VERSION ""

NS_ :

BS_:

BU_: SGW PBWM IDCM EVCU2 ECM DMPI BPCM AGSM

BO_ 276 HYBRID_POWERTRAIN1: 64 EVCU2
 SG_ MessageCounter_HYBRID_POWERTRAI : 435|4@0+ (1,0) [0|15] "-"  ECM
 SG_ TransInpSpdPrfl : 68|13@0+ (1,0) [0|8191] "rpm"  ECM
 SG_ InputSpdRaw : 179|12@0+ (1,-2048) [-2048|2046] "rpm"  ECM
 SG_ HybTransSt : 255|8@0+ (1,0) [0|0] "-"  ECM
 SG_ Hybrid_Remedial_Stop : 290|1@0+ (1,0) [0|0] "-"  ECM
 SG_ HybFeedback_Engine : 294|1@0+ (1,0) [0|0] "-"  ECM
 SG_ HybEstEngTorqV : 280|1@0+ (1,0) [0|0] "-"  ECM
 SG_ HybEstEngTorq : 163|12@0+ (0.32,-300.16) [-300.16|1008] "Nm"  ECM
 SG_ HybCrnkAbrted : 282|1@0+ (1,0) [0|0] "-"  ECM
 SG_ HybCmndEngTorqRespTyp : 277|2@0+ (1,0) [0|0] "-"  ECM
 SG_ HybCmndEngTorqPrdtd : 147|12@0+ (0.32,-300.16) [-300.16|1008] "Nm"  ECM
 SG_ HybCmndEngTorqImmed : 131|12@0+ (0.32,-300.16) [-300.16|1008] "Nm"  ECM
 SG_ EngTrqReserveCmd : 263|8@0+ (0.32,0) [0|81.28] "Nm"  ECM
 SG_ EngCntrlMode : 283|1@0+ (1,0) [0|0] "-"  ECM
 SG_ ECMPrepIdleRes : 295|1@0+ (1,0) [0|0] "-"  ECM
 SG_ CRC_HYBRID_POWERTRAIN1 : 447|8@0+ (1,0) [0|255] "-"  ECM
 SG_ PropulsionSystemActive : 408|1@0+ (1,0) [0|1] "-"  ECM
 SG_ HybFstTrqRq_Trans : 293|1@0+ (1,0) [0|0] "-"  ECM

BO_ 271 ENGINE_HYBD_FD_1: 64 ECM
 SG_ TLC_LRN_Rq : 322|1@0+ (1,0) [0|0] "-"  EVCU2
 SG_ Sum_FW_ID_Slw : 327|5@0+ (1,0) [0|30] "-"  EVCU2
 SG_ Sum_FW_ID_Fst : 367|5@0+ (1,0) [0|30] "-"  EVCU2
 SG_ PT_CrnkAct : 310|1@0+ (1,0) [0|0] "-"  EVCU2
 SG_ MinPrdtdEngRunTorqCapV : 213|1@0+ (1,0) [0|0] "-"  EVCU2
 SG_ MinPrdtdEngRunTorqCap : 243|12@0+ (0.32,-300.16) [-300.16|1008] "Nm"  EVCU2
 SG_ MinImmedEngTorqCapV : 215|1@0+ (1,0) [0|0] "-"  EVCU2
 SG_ MinImmedEngTorqCap : 227|12@0+ (0.32,-300.16) [-300.16|1008] "Nm"  EVCU2
 SG_ MinEngTorqCapV : 196|1@0+ (1,0) [0|0] "-"  EVCU2
 SG_ MinEngTorqCap : 211|12@0+ (0.32,-300.16) [-300.16|1008] "Nm"  EVCU2
 SG_ MinAirFlowMinSparkTorqCapV : 197|1@0+ (1,0) [0|0] "-"  EVCU2
 SG_ MinAirFlowMinSparkTorqCap : 195|12@0+ (0.32,-300.16) [-300.16|1008] "Nm"  EVCU2
 SG_ MessageCounter_ENGINE_HYBD_FD_1 : 435|4@0+ (1,0) [0|15] "-"  EVCU2
 SG_ MaxPrdtdEngTorqCapV : 198|1@0+ (1,0) [0|0] "-"  EVCU2
 SG_ MaxPrdtdEngTorqCap : 179|12@0+ (0.32,-300.16) [-300.16|1008] "Nm"  EVCU2
 SG_ MaxOffEngTorqCap : 163|12@0+ (0.32,-300.16) [-300.16|1008] "Nm"  EVCU2
 SG_ HybActEngTorqRespTyp : 149|2@0+ (1,0) [0|0] "-"  EVCU2
 SG_ Feedback_HCP : 293|1@0+ (1,0) [0|0] "-"  EVCU2
 SG_ ETRQ_Mode : 362|3@0+ (1,0) [0|5] "-"  EVCU2
 SG_ EngTrqReserveReq : 351|8@0+ (0.32,0) [0|81.28] "Nm"  EVCU2
 SG_ EngRunCrnkAct : 295|1@0+ (1,0) [0|0] "-"  EVCU2
 SG_ EngOffRecom : 276|1@0+ (1,0) [0|0] "-"  EVCU2
 SG_ Engine_Sync_720 : 277|1@0+ (1,0) [0|0] "-"  Vector__XXX
 SG_ EngDFCO_St : 278|1@0+ (1,0) [0|0] "-"  EVCU2
 SG_ EngDFCO_Req : 279|1@0+ (1,0) [0|0] "-"  EVCU2
 SG_ EngDFCO_Allw : 260|1@0+ (1,0) [0|0] "-"  EVCU2
 SG_ EngCmbstnCmnd : 199|1@0+ (1,0) [0|0] "-"  EVCU2
 SG_ EngAirFlwStdyStTorqV : 262|1@0+ (1,0) [0|0] "-"  EVCU2
 SG_ EngAirFlwStdyStTorq : 275|12@0+ (0.32,-300.16) [-300.16|1008] "Nm"  EVCU2
 SG_ EngActuatorsStat : 133|2@0+ (1,0) [0|0] "-"  EVCU2
 SG_ EngActStdyStTorqV : 263|1@0+ (1,0) [0|0] "-"  EVCU2
 SG_ EngActStdyStTorq : 259|12@0+ (0.32,-300.16) [-300.16|1008] "Nm"  EVCU2
 SG_ CylOff : 245|1@0+ (1,0) [0|0] "-"  EVCU2
 SG_ CRC_ENGINE_HYBD_FD_1 : 447|8@0+ (1,0) [0|255] "-"  EVCU2
 SG_ Crank_Maturing_Fault : 246|1@0+ (1,0) [0|0] "-"  EVCU2
 SG_ Crank_Locked : 247|1@0+ (1,0) [0|0] "-"  Vector__XXX
 SG_ Cam_Int_1_Locked : 229|1@0+ (1,0) [0|0] "-"  Vector__XXX
 SG_ Cam_Exh_1_Locked : 231|1@0+ (1,0) [0|0] "-"  Vector__XXX
 SG_ AccPosV : 214|1@0+ (1,0) [0|1] "" EVCU2
 SG_ AccPos : 343|8@0+ (0.392157,0) [0|100] "%"  EVCU2
 SG_ ECMReq_Remedial_Stop : 135|2@0+ (1,0) [0|0] "-"  EVCU2
 SG_ ECM_Crank_Phase : 372|3@0+ (1,0) [0|7] "-"  Vector__XXX
 SG_ MAP_4_BAR_PHEV : 392|9@0+ (0.8,0) [0|408] "kPa"  EVCU2
 SG_ RedSpkAuthorityAvbl : 308|1@0+ (1,0) [0|1] "" EVCU2
 SG_ EngMinSparkNomCurrAirTorqCap : 82|11@0+ (1,-500) [-500|1547] "Nm"  EVCU2
 SG_ PnLimitMaxEngTrqCapV : 182|1@0+ (1,0) [0|1] "" EVCU2
 SG_ PnLimitMaxEngTrqCap : 321|10@0+ (1,0) [0|1023] "Nm"  EVCU2
 SG_ PnLimitActvFlg : 83|1@0+ (1,0) [0|1] "" EVCU2
 SG_ EngSysFld : 294|1@0+ (1,0) [0|0] "" EVCU2

BO_ 258 BRAKE_FD_2: 64 EVCU2
 SG_ VehicleSpeedVSOSig : 4|13@0+ (0.0625,0) [0|511.875] "Km/h"  IDCM,BPCM

BO_ 476 AGSM_FD_2: 32 AGSM
 SG_ MessageCounter_AGSM2 : 179|4@0+ (1,0) [0|15] "-"  PBWM,EVCU2
 SG_ CRC_AGSM2 : 191|8@0+ (1,0) [0|255] "-"  PBWM,EVCU2
 SG_ ShiftLeverPositionReq : 95|4@0+ (1,0) [0|15] "-"  PBWM,EVCU2

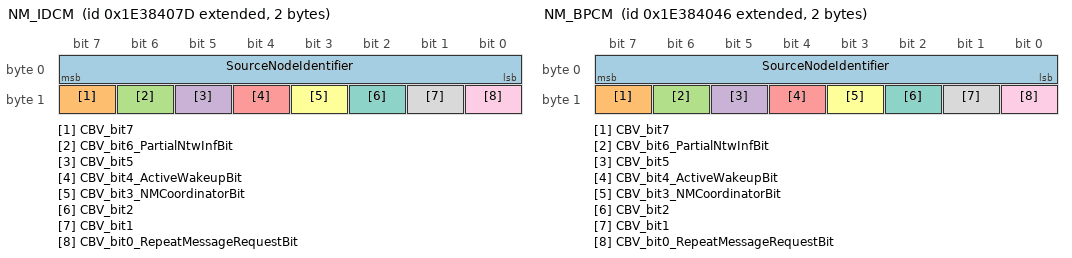
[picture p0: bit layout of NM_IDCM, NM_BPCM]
BO_ 2654486653 NM_IDCM: 2 IDCM
 SG_ SourceNodeIdentifier : 7|8@0+ (1,0) [0|255] "-"  DMPI,PBWM,EVCU2,SGW,BPCM,ECM
 SG_ CBV_bit7 : 15|1@0+ (1,0) [0|1] "" DMPI,PBWM,EVCU2,SGW,BPCM,ECM
 SG_ CBV_bit6_PartialNtwInfBit : 14|1@0+ (1,0) [0|1] "" DMPI,PBWM,EVCU2,SGW,BPCM,ECM
 SG_ CBV_bit5 : 13|1@0+ (1,0) [0|1] "" DMPI,PBWM,EVCU2,SGW,BPCM,ECM
 SG_ CBV_bit4_ActiveWakeupBit : 12|1@0+ (1,0) [0|1] "" DMPI,PBWM,EVCU2,SGW,BPCM,ECM
 SG_ CBV_bit3_NMCoordinatorBit : 11|1@0+ (1,0) [0|1] "" DMPI,PBWM,EVCU2,SGW,BPCM,ECM
 SG_ CBV_bit2 : 10|1@0+ (1,0) [0|1] "" DMPI,PBWM,EVCU2,SGW,BPCM,ECM
 SG_ CBV_bit1 : 9|1@0+ (1,0) [0|1] "" DMPI,PBWM,EVCU2,SGW,BPCM,ECM
 SG_ CBV_bit0_RepeatMessageRequestBit : 8|1@0+ (1,0) [0|1] "" DMPI,PBWM,EVCU2,SGW,BPCM,ECM

BO_ 2654486598 NM_BPCM: 2 BPCM
 SG_ SourceNodeIdentifier : 7|8@0+ (1,0) [0|255] "-"  DMPI,PBWM,EVCU2,IDCM,SGW,ECM
 SG_ CBV_bit7 : 15|1@0+ (1,0) [0|1] "" DMPI,PBWM,EVCU2,IDCM,SGW,ECM
 SG_ CBV_bit6_PartialNtwInfBit : 14|1@0+ (1,0) [0|1] "" DMPI,PBWM,EVCU2,IDCM,SGW,ECM
 SG_ CBV_bit5 : 13|1@0+ (1,0) [0|1] "" DMPI,PBWM,EVCU2,IDCM,SGW,ECM
 SG_ CBV_bit4_ActiveWakeupBit : 12|1@0+ (1,0) [0|1] "" DMPI,PBWM,EVCU2,IDCM,SGW,ECM
 SG_ CBV_bit3_NMCoordinatorBit : 11|1@0+ (1,0) [0|1] "" DMPI,PBWM,EVCU2,IDCM,SGW,ECM
 SG_ CBV_bit2 : 10|1@0+ (1,0) [0|1] "" DMPI,PBWM,EVCU2,IDCM,SGW,ECM
 SG_ CBV_bit1 : 9|1@0+ (1,0) [0|1] "" DMPI,PBWM,EVCU2,IDCM,SGW,ECM
 SG_ CBV_bit0_RepeatMessageRequestBit : 8|1@0+ (1,0) [0|1] "" DMPI,PBWM,EVCU2,IDCM,SGW,ECM

BO_ 1579 HYBRID_CHARGING_STATUS: 32 EVCU2
 SG_ HVBatteryVoltage_MinCal : 32|9@0+ (1,0) [0|510] "V"  IDCM,BPCM
 SG_ HVBatteryVoltage_MaxCal : 16|9@0+ (1,0) [0|510] "V"  IDCM,BPCM
 SG_ HVBatteryCurrent_MaxCal : 63|8@0+ (0.25,-32) [-32|31.5] "Amp"  IDCM,BPCM
 SG_ ChargeSystemFaultReason : 55|8@0+ (1,0) [0|254] "-"  IDCM
 SG_ ACCurrent_MaxCal : 0|9@0+ (0.25,-31.5) [-31.5|50] "Amp"  IDCM,BPCM
 SG_ MessageCounter_HYBRID_CHARGING_ : 179|4@0+ (1,0) [0|15] "-"  IDCM
 SG_ ChargingLevel : 4|4@0+ (1,0) [0|14] "-"  IDCM,SGW,BPCM
 SG_ OBCM_PLUG_STS : 23|2@0+ (1,0) [0|3] "" IDCM
 SG_ VDCM_UDCChrgr : 71|16@0+ (0.1,0) [0|6553.5] "V"  IDCM
 SG_ VDCM_IDCChrgr : 87|16@0+ (0.1,0) [0|6553.5] "A"  IDCM
 SG_ ChargeSystemSts : 7|3@0+ (1,0) [0|6] "-"  IDCM,BPCM
 SG_ ChargeSystemFault : 17|1@0+ (1,0) [0|1] "-"  IDCM
 SG_ CRC_HYBRID_CHARGING_STATUS : 191|8@0+ (1,0) [0|255] "-"  IDCM

BO_ 478 HYBRID_CHARGING_COMMAND: 32 EVCU2
 SG_ MessageCounter_HYBRID_CHARGING_ : 179|4@0+ (1,0) [0|15] "-"  IDCM
 SG_ CRC_HYBRID_CHARGING_COMMAND : 191|8@0+ (1,0) [0|255] "-"  IDCM
 SG_ VoltageRequest : 4|13@0+ (0.1,0) [0|819.1] "Volts"  IDCM
 SG_ OBC_ControlMethod : 38|2@0+ (1,0) [0|2] "-"  IDCM
 SG_ J1772_CloseS2 : 51|1@0+ (1,0) [0|1] "-"  IDCM
 SG_ HVPowertrain_InterlockSts : 34|2@0+ (1,0) [0|3] "-"  BPCM
 SG_ ClearLegislatedDiagInfo : 52|1@0+ (1,0) [0|1] "-"  BPCM
 SG_ OBC_OperativeModeReq : 87|4@0+ (1,0) [0|14] "-"  IDCM
 SG_ HV_Volt_Min_Thrsh : 138|11@0+ (1,0) [0|2047] "V"  IDCM
 SG_ HV_Volt_Max_Thrsh : 133|11@0+ (1,0) [0|2047] "V"  IDCM
 SG_ DC_Curr_Max_Thrsh : 127|10@0+ (1,-511) [-511|512] "A"  IDCM
 SG_ ChargeEnable : 171|2@0+ (1,0) [0|2] "-"  IDCM
 SG_ AC_Curr_Min_Thrsh : 165|10@0+ (1,-511) [-511|512] "A"  IDCM
 SG_ AC_Curr_Max_Thrsh : 159|10@0+ (1,-511) [-511|512] "A"  IDCM
 SG_ CurrentRequest : 81|10@0+ (0.1,-32) [-32|70.3] "A"  IDCM
 SG_ VDCM_StsWldgReq : 83|1@0+ (1,0) [0|1] "-"  IDCM
 SG_ VDCM_SessnStopReq : 82|1@0+ (1,0) [0|1] "-"  IDCM
 SG_ VDCM_StsSWWldgReq : 55|2@0+ (1,0) [0|3] "-"  Vector__XXX

BO_ 1578 HV_CHARGER2: 32 IDCM
 SG_ OBC_IdleTimeSec : 71|16@0+ (3,0) [0|196602] "sec"  EVCU2
 SG_ OBC_IdleTimeMin : 87|16@0+ (1,0) [0|65534] "min"  EVCU2
 SG_ OBC_ChargeTimeSec : 39|16@0+ (3,0) [0|196602] "sec"  EVCU2
 SG_ OBC_ChargeTimeMin : 55|16@0+ (1,0) [0|65534] "min"  EVCU2
 SG_ Charging_WHr : 23|16@0+ (1,0) [0|65534] "WHr"  EVCU2
 SG_ OnboardChargerReady : 116|2@0+ (1,0) [0|2] "-"  EVCU2
 SG_ OnboardChargerMode : 114|4@0+ (1,0) [0|15] "-"  EVCU2
 SG_ OBC_WakeReason : 107|4@0+ (1,0) [0|7] "-"  EVCU2
 SG_ OBC_GenericFailSts : 125|1@0+ (1,0) [0|1] "-"  EVCU2
 SG_ OBC_FaultReason : 102|7@0+ (1,0) [0|126] "-"  EVCU2
 SG_ OBC_EVServiceLampOn : 124|1@0+ (1,0) [0|1] "-"  EVCU2
 SG_ OBC_EVServiceLampFlash : 123|1@0+ (1,0) [0|1] "-"  EVCU2
 SG_ OBC_CurrentFailureSts : 121|1@0+ (1,0) [0|1] "-"  EVCU2
 SG_ OBC_ChargingFaultSts : 110|3@0+ (1,0) [0|7] "-"  EVCU2
 SG_ OBC_ChargeFailure : 120|1@0+ (1,0) [0|1] "-"  EVCU2
 SG_ OBC_CaptureEnvironmentData : 119|1@0+ (1,0) [0|1] "-"  EVCU2
 SG_ ACplug_PwrMax : 7|16@0+ (1,-32767) [-32767|32767] "W"  EVCU2
 SG_ OBC_Prox : 159|8@0+ (0.05,0) [0|12.75] "V"  EVCU2
 SG_ OBC_Pilot : 151|8@0+ (0.05,0) [0|12.75] "V"  EVCU2
 SG_ OBCM_PrechargeSts : 167|2@0+ (1,0) [0|3] "-"  EVCU2
 SG_ ChrgFailSts : 165|3@0+ (1,0) [0|7] "" EVCU2

BO_ 1372 DUALCHARGER_THERMAL: 32 IDCM
 SG_ OBC_Temp4 : 63|8@0+ (1,-40) [-40|214] "°C"  EVCU2
 SG_ OBC_Temp3 : 55|8@0+ (1,-40) [-40|214] "°C"  EVCU2
 SG_ OBC_Temp2 : 47|8@0+ (1,-40) [-40|214] "°C"  EVCU2
 SG_ OBC_Temp1 : 39|8@0+ (1,-40) [-40|214] "°C"  EVCU2

BO_ 2564682064 DIAGNOSTIC_ROE_IDCM: 8 IDCM
 SG_ N_PDU : 7|64@0+ (1,0) [0|0] "" SGW

BO_ 2564682320 DIAGNOSTIC_ROE_FD_IDCM: 64 IDCM
 SG_ N_PDU : 7|64@0+ (1,0) [0|0] "" SGW

BO_ 2564682308 DIAGNOSTIC_ROE_FD_BPCM: 64 BPCM
 SG_ N_PDU : 7|64@0+ (1,0) [0|0] "" SGW

BO_ 2564682052 DIAGNOSTIC_ROE_BPCM: 8 BPCM
 SG_ N_PDU : 7|64@0+ (1,0) [0|0] "" SGW

BO_ 2564485712 DIAGNOSTIC_RESPONSE_FD_IDCM: 64 IDCM
 SG_ N_PDU : 7|64@0+ (1,0) [0|0] "" SGW

BO_ 2564485700 DIAGNOSTIC_RESPONSE_FD_BPCM: 64 BPCM
 SG_ N_PDU : 7|64@0+ (1,0) [0|0] "" SGW

BO_ 2564444402 DIAGNOSTIC_REQUEST_FD_IDCM: 64 SGW
 SG_ N_PDU : 7|64@0+ (1,0) [0|0] "" IDCM

BO_ 2564441330 DIAGNOSTIC_REQUEST_FD_BPCM: 64 SGW
 SG_ N_PDU : 7|64@0+ (1,0) [0|0] "" BPCM

BO_ 1845 HVBATTERY_RM_BATTERYID: 64 BPCM
 SG_ HVBatSerialLength : 199|8@0+ (1,0) [0|254] "" SGW
 SG_ HVBatSerialNumber : 7|192@0+ (1,0) [0|0] "" SGW

BO_ 1460 FOTA_MASTER: 32 SGW
 SG_ FOTA_Status : 7|4@0+ (1,0) [0|15] "" EVCU2,BPCM

BO_ 1852 HVBATTERY_RM_CELLS8: 64 BPCM
 SG_ HVBatCellVoltage_Cell192 : 36|13@0+ (0.001,0) [0|5] "V"  Vector__XXX
 SG_ HVBatCellVoltage_Cell191 : 20|13@0+ (0.001,0) [0|5] "V"  Vector__XXX
 SG_ HVBatCellVoltage_Cell190 : 4|13@0+ (0.001,0) [0|5] "V"  Vector__XXX
 SG_ HVBatCellVoltage_Cell216 : 420|13@0+ (0.001,0) [0|5] "V"  SGW
 SG_ HVBatCellVoltage_Cell215 : 404|13@0+ (0.001,0) [0|5] "V"  Vector__XXX
 SG_ HVBatCellVoltage_Cell214 : 388|13@0+ (0.001,0) [0|5] "V"  Vector__XXX
 SG_ HVBatCellVoltage_Cell213 : 372|13@0+ (0.001,0) [0|5] "V"  Vector__XXX
 SG_ HVBatCellVoltage_Cell212 : 356|13@0+ (0.001,0) [0|5] "V"  Vector__XXX
 SG_ HVBatCellVoltage_Cell211 : 340|13@0+ (0.001,0) [0|5] "V"  Vector__XXX
 SG_ HVBatCellVoltage_Cell210 : 324|13@0+ (0.001,0) [0|5] "V"  Vector__XXX
 SG_ HVBatCellVoltage_Cell209 : 308|13@0+ (0.001,0) [0|5] "V"  Vector__XXX
 SG_ HVBatCellVoltage_Cell208 : 292|13@0+ (0.001,0) [0|5] "V"  Vector__XXX
 SG_ HVBatCellVoltage_Cell207 : 276|13@0+ (0.001,0) [0|5] "V"  Vector__XXX
 SG_ HVBatCellVoltage_Cell206 : 260|13@0+ (0.001,0) [0|5] "V"  Vector__XXX
 SG_ HVBatCellVoltage_Cell205 : 244|13@0+ (0.001,0) [0|5] "V"  Vector__XXX
 SG_ HVBatCellVoltage_Cell204 : 228|13@0+ (0.001,0) [0|5] "V"  Vector__XXX
 SG_ HVBatCellVoltage_Cell203 : 212|13@0+ (0.001,0) [0|5] "V"  Vector__XXX
 SG_ HVBatCellVoltage_Cell202 : 196|13@0+ (0.001,0) [0|5] "V"  Vector__XXX
 SG_ HVBatCellVoltage_Cell201 : 180|13@0+ (0.001,0) [0|5] "V"  Vector__XXX
 SG_ HVBatCellVoltage_Cell200 : 164|13@0+ (0.001,0) [0|5] "V"  Vector__XXX
 SG_ HVBatCellVoltage_Cell198 : 132|13@0+ (0.001,0) [0|5] "V"  Vector__XXX
 SG_ HVBatCellVoltage_Cell197 : 116|13@0+ (0.001,0) [0|5] "V"  Vector__XXX
 SG_ HVBatCellVoltage_Cell196 : 100|13@0+ (0.001,0) [0|5] "V"  Vector__XXX
 SG_ HVBatCellVoltage_Cell195 : 84|13@0+ (0.001,0) [0|5] "V"  Vector__XXX
 SG_ HVBatCellVoltage_Cell194 : 68|13@0+ (0.001,0) [0|5] "V"  Vector__XXX
 SG_ HVBatCellVoltage_Cell193 : 52|13@0+ (0.001,0) [0|5] "V"  Vector__XXX

BO_ 1851 HVBATTERY_RM_CELLS7: 64 BPCM
 SG_ HVBatCellVoltage_Cell189 : 420|13@0+ (0.001,0) [0|5] "V"  Vector__XXX
 SG_ HVBatCellVoltage_Cell188 : 404|13@0+ (0.001,0) [0|5] "V"  Vector__XXX
 SG_ HVBatCellVoltage_Cell187 : 388|13@0+ (0.001,0) [0|5] "V"  Vector__XXX
 SG_ HVBatCellVoltage_Cell186 : 372|13@0+ (0.001,0) [0|5] "V"  Vector__XXX
 SG_ HVBatCellVoltage_Cell185 : 356|13@0+ (0.001,0) [0|5] "V"  Vector__XXX
 SG_ HVBatCellVoltage_Cell184 : 340|13@0+ (0.001,0) [0|5] "V"  Vector__XXX
 SG_ HVBatCellVoltage_Cell183 : 324|13@0+ (0.001,0) [0|5] "V"  SGW
 SG_ HVBatCellVoltage_Cell182 : 308|13@0+ (0.001,0) [0|5] "V"  SGW
 SG_ HVBatCellVoltage_Cell181 : 292|13@0+ (0.001,0) [0|5] "V"  SGW
 SG_ HVBatCellVoltage_Cell180 : 276|13@0+ (0.001,0) [0|5] "V"  SGW
 SG_ HVBatCellVoltage_Cell179 : 260|13@0+ (0.001,0) [0|5] "V"  SGW
 SG_ HVBatCellVoltage_Cell178 : 244|13@0+ (0.001,0) [0|5] "V"  SGW
 SG_ HVBatCellVoltage_Cell177 : 228|13@0+ (0.001,0) [0|5] "V"  SGW
 SG_ HVBatCellVoltage_Cell176 : 212|13@0+ (0.001,0) [0|5] "V"  SGW
 SG_ HVBatCellVoltage_Cell175 : 196|13@0+ (0.001,0) [0|5] "V"  SGW
 SG_ HVBatCellVoltage_Cell174 : 180|13@0+ (0.001,0) [0|5] "V"  SGW
 SG_ HVBatCellVoltage_Cell173 : 164|13@0+ (0.001,0) [0|5] "V"  SGW
 SG_ HVBatCellVoltage_Cell172 : 148|13@0+ (0.001,0) [0|5] "V"  SGW
 SG_ HVBatCellVoltage_Cell171 : 132|13@0+ (0.001,0) [0|5] "V"  SGW
 SG_ HVBatCellVoltage_Cell170 : 116|13@0+ (0.001,0) [0|5] "V"  SGW
 SG_ HVBatCellVoltage_Cell169 : 100|13@0+ (0.001,0) [0|5] "V"  SGW
 SG_ HVBatCellVoltage_Cell168 : 84|13@0+ (0.001,0) [0|5] "V"  SGW
 SG_ HVBatCellVoltage_Cell167 : 68|13@0+ (0.001,0) [0|5] "V"  SGW
 SG_ HVBatCellVoltage_Cell166 : 52|13@0+ (0.001,0) [0|5] "V"  SGW
 SG_ HVBatCellVoltage_Cell165 : 36|13@0+ (0.001,0) [0|5] "V"  SGW
 SG_ HVBatCellVoltage_Cell164 : 20|13@0+ (0.001,0) [0|5] "V"  SGW
 SG_ HVBatCellVoltage_Cell163 : 4|13@0+ (0.001,0) [0|5] "V"  SGW

BO_ 1850 HVBATTERY_RM_CELLS6: 64 BPCM
 SG_ HVBatCellVoltage_Cell162 : 420|13@0+ (0.001,0) [0|5] "V"  SGW
 SG_ HVBatCellVoltage_Cell161 : 404|13@0+ (0.001,0) [0|5] "V"  SGW
 SG_ HVBatCellVoltage_Cell160 : 388|13@0+ (0.001,0) [0|5] "V"  SGW
 SG_ HVBatCellVoltage_Cell159 : 372|13@0+ (0.001,0) [0|5] "V"  SGW
 SG_ HVBatCellVoltage_Cell158 : 356|13@0+ (0.001,0) [0|5] "V"  SGW
 SG_ HVBatCellVoltage_Cell157 : 340|13@0+ (0.001,0) [0|5] "V"  SGW
 SG_ HVBatCellVoltage_Cell156 : 324|13@0+ (0.001,0) [0|5] "V"  SGW
 SG_ HVBatCellVoltage_Cell155 : 308|13@0+ (0.001,0) [0|5] "V"  SGW
 SG_ HVBatCellVoltage_Cell154 : 292|13@0+ (0.001,0) [0|5] "V"  SGW
 SG_ HVBatCellVoltage_Cell153 : 276|13@0+ (0.001,0) [0|5] "V"  SGW
 SG_ HVBatCellVoltage_Cell152 : 260|13@0+ (0.001,0) [0|5] "V"  SGW
 SG_ HVBatCellVoltage_Cell151 : 244|13@0+ (0.001,0) [0|5] "V"  SGW
 SG_ HVBatCellVoltage_Cell150 : 228|13@0+ (0.001,0) [0|5] "V"  SGW
 SG_ HVBatCellVoltage_Cell149 : 212|13@0+ (0.001,0) [0|5] "V"  SGW
 SG_ HVBatCellVoltage_Cell148 : 196|13@0+ (0.001,0) [0|5] "V"  SGW
 SG_ HVBatCellVoltage_Cell147 : 180|13@0+ (0.001,0) [0|5] "V"  SGW
 SG_ HVBatCellVoltage_Cell146 : 164|13@0+ (0.001,0) [0|5] "V"  SGW
 SG_ HVBatCellVoltage_Cell145 : 148|13@0+ (0.001,0) [0|5] "V"  SGW
 SG_ HVBatCellVoltage_Cell144 : 132|13@0+ (0.001,0) [0|5] "V"  SGW
 SG_ HVBatCellVoltage_Cell143 : 116|13@0+ (0.001,0) [0|5] "V"  SGW
 SG_ HVBatCellVoltage_Cell142 : 100|13@0+ (0.001,0) [0|5] "V"  SGW
 SG_ HVBatCellVoltage_Cell141 : 84|13@0+ (0.001,0) [0|5] "V"  SGW
 SG_ HVBatCellVoltage_Cell140 : 68|13@0+ (0.001,0) [0|5] "V"  SGW
 SG_ HVBatCellVoltage_Cell139 : 52|13@0+ (0.001,0) [0|5] "V"  SGW
 SG_ HVBatCellVoltage_Cell138 : 36|13@0+ (0.001,0) [0|5] "V"  SGW
 SG_ HVBatCellVoltage_Cell137 : 20|13@0+ (0.001,0) [0|5] "V"  SGW
 SG_ HVBatCellVoltage_Cell136 : 4|13@0+ (0.001,0) [0|5] "V"  SGW

BO_ 1849 HVBATTERY_RM_CELLS5: 64 BPCM
 SG_ HVBatCellVoltage_Cell135 : 420|13@0+ (0.001,0) [0|5] "V"  SGW
 SG_ HVBatCellVoltage_Cell134 : 404|13@0+ (0.001,0) [0|5] "V"  SGW
 SG_ HVBatCellVoltage_Cell133 : 388|13@0+ (0.001,0) [0|5] "V"  SGW
 SG_ HVBatCellVoltage_Cell132 : 372|13@0+ (0.001,0) [0|5] "V"  SGW
 SG_ HVBatCellVoltage_Cell131 : 356|13@0+ (0.001,0) [0|5] "V"  SGW
 SG_ HVBatCellVoltage_Cell130 : 340|13@0+ (0.001,0) [0|5] "V"  SGW
 SG_ HVBatCellVoltage_Cell129 : 324|13@0+ (0.001,0) [0|5] "V"  SGW
 SG_ HVBatCellVoltage_Cell128 : 308|13@0+ (0.001,0) [0|5] "V"  SGW
 SG_ HVBatCellVoltage_Cell127 : 292|13@0+ (0.001,0) [0|5] "V"  SGW
 SG_ HVBatCellVoltage_Cell126 : 276|13@0+ (0.001,0) [0|5] "V"  SGW
 SG_ HVBatCellVoltage_Cell125 : 260|13@0+ (0.001,0) [0|5] "V"  SGW
 SG_ HVBatCellVoltage_Cell124 : 244|13@0+ (0.001,0) [0|5] "V"  SGW
 SG_ HVBatCellVoltage_Cell123 : 228|13@0+ (0.001,0) [0|5] "V"  SGW
 SG_ HVBatCellVoltage_Cell122 : 212|13@0+ (0.001,0) [0|5] "V"  SGW
 SG_ HVBatCellVoltage_Cell121 : 196|13@0+ (0.001,0) [0|5] "V"  SGW
 SG_ HVBatCellVoltage_Cell120 : 180|13@0+ (0.001,0) [0|5] "V"  SGW
 SG_ HVBatCellVoltage_Cell119 : 164|13@0+ (0.001,0) [0|5] "V"  SGW
 SG_ HVBatCellVoltage_Cell118 : 148|13@0+ (0.001,0) [0|5] "V"  SGW
 SG_ HVBatCellVoltage_Cell117 : 132|13@0+ (0.001,0) [0|5] "V"  SGW
 SG_ HVBatCellVoltage_Cell116 : 116|13@0+ (0.001,0) [0|5] "V"  SGW
 SG_ HVBatCellVoltage_Cell115 : 100|13@0+ (0.001,0) [0|5] "V"  SGW
 SG_ HVBatCellVoltage_Cell114 : 84|13@0+ (0.001,0) [0|5] "V"  SGW
 SG_ HVBatCellVoltage_Cell113 : 68|13@0+ (0.001,0) [0|5] "V"  SGW
 SG_ HVBatCellVoltage_Cell112 : 52|13@0+ (0.001,0) [0|5] "V"  SGW
 SG_ HVBatCellVoltage_Cell111 : 36|13@0+ (0.001,0) [0|5] "V"  SGW
 SG_ HVBatCellVoltage_Cell110 : 20|13@0+ (0.001,0) [0|5] "V"  SGW
 SG_ HVBatCellVoltage_Cell109 : 4|13@0+ (0.001,0) [0|5] "V"  SGW

CM_ SG_ 276 TransInpSpdPrfl "Transmission Input Speed Profile";
CM_ SG_ 276 PropulsionSystemActive "Propulsion system active, [1] = active";
CM_ SG_ 276 MessageCounter_HYBRID_POWERTRAI "This signal is a counter used for safety checks strategies. This counter is incremented of 1 (one) unit at each frame transmission.";
CM_ SG_ 276 InputSpdRaw "Trans input speed from HCP.";
CM_ SG_ 276 HybTransSt "Hybrid transmission state";
CM_ SG_ 276 Hybrid_Remedial_Stop "Engine Start Allowed.0 = ENG_ON_ALLOWED, 1 = ENG_ON_NOT_ALLOW";
CM_ SG_ 276 HybFstTrqRq_Trans "HCP request for Spark Retard to honor Trans Torque reduction request. 0 - False; 1 - True.";
CM_ SG_ 276 HybFeedback_Engine "Indication that the HCP is receiving valid data from the ECM. 0 - False; 1 - True.";
CM_ SG_ 276 HybEstEngTorqV "Hybrid estimated engine torque validity. 0 = Valid, 1 = Invalid";
CM_ SG_ 276 HybEstEngTorq "Hybrid estimated engine torque";
CM_ SG_ 276 HybCrnkAbrted "Hybrid Crank Aborted";
CM_ SG_ 276 HybCmndEngTorqRespTyp "Hybrid Commanded Engine Torque Response Type";
CM_ SG_ 276 HybCmndEngTorqPrdtd "Hybrid commanded engine torque predicted torque (slow path).";
CM_ SG_ 276 HybCmndEngTorqImmed "Hybrid commanded engine torque immediate torque (fast path)";
CM_ SG_ 276 EngTrqReserveCmd "Engine torque reserve command";
CM_ SG_ 276 EngCntrlMode "EngCntrlMode, [0] = Torque Mode, [1] = Speed Mode";
CM_ SG_ 276 ECMPrepIdleRes "ECM to prep for rolling idle reserve";
CM_ SG_ 276 CRC_HYBRID_POWERTRAIN1 "CRC according to SAE J1850 standard at each frame transmission.";
CM_ SG_ 271 EngMinSparkNomCurrAirTorqCap "Engine Torque capacity at current airflow  min and  nominal spark advance.";
CM_ SG_ 271 Engine_Sync_720 "Indicates that the crank and cams have synchronized";
CM_ SG_ 271 EngDFCO_St "Engine deceleration fuel cut off state";
CM_ SG_ 271 EngDFCO_Req "Engine deceleration fuel cut off requested";
CM_ SG_ 271 EngDFCO_Allw "Engine deceleration fuel cut off allowed";
CM_ SG_ 271 EngCmbstnCmnd "Engine combustion commanded";
CM_ SG_ 271 EngAirFlwStdyStTorqV "Engine airflow steady state torque validity; Invalid = [1]";
CM_ SG_ 271 EngAirFlwStdyStTorq "Engine airflow steady state torque (potential)";
CM_ SG_ 271 EngActuatorsStat "Engine Actuator Status for Autostop";
CM_ SG_ 271 EngActStdyStTorqV "Engine actual steady state torque validity; Invalid = [1]";
CM_ SG_ 271 EngActStdyStTorq "Engine actual steady state torque (current conditions)";
CM_ SG_ 271 ECMReq_Remedial_Stop "Engine Stop Request";
CM_ SG_ 271 ECM_Crank_Phase "BSG applications between the ECM and HCP";
CM_ SG_ 271 CylOff "Cylinder off due to misfire";
CM_ SG_ 271 CRC_ENGINE_HYBD_FD_1 "CRC according to SAE J1850 standard at each frame transmission.";
CM_ SG_ 271 Crank_Maturing_Fault "Indicates ECM is maturing a crank fault diagnostic";
CM_ SG_ 271 Crank_Locked "Indicates that the crankshaft has locked its position";
CM_ SG_ 271 Cam_Int_1_Locked "Indicates the camshaft driver has locked the camshaft position (intake cam bank 1)";
CM_ SG_ 271 Cam_Exh_1_Locked "Indicates the camshaft driver has locked the camshaft position (exhaust cam bank 1)";
CM_ SG_ 271 AccPosV "Accelerator Effective Position Validity";
CM_ SG_ 271 AccPos "Accelerator Effective Position";
CM_ SG_ 271 TLC_LRN_Rq "TLC learning request";
CM_ SG_ 271 Sum_FW_ID_Slw "Enumeration of system controlling combustion slow path";
CM_ SG_ 271 Sum_FW_ID_Fst "Enumeration of system controlling combustion fast path";
CM_ SG_ 271 RedSpkAuthorityAvbl "Reduced Spark Availability Warning";
CM_ SG_ 271 PT_CrnkAct "Powertrain crank active";
CM_ SG_ 271 PnLimitMaxEngTrqCapV "Validity Bit for Engine Max Torque Capacity PN Limitation";
CM_ SG_ 271 PnLimitMaxEngTrqCap "Engine Max Torque Capacity for PN Limitation";
CM_ SG_ 271 EngSysFld "Engine System Failed";
CM_ SG_ 271 PnLimitActvFlg "Activation flag for PN Limitation feature.";
CM_ SG_ 271 MinPrdtdEngRunTorqCapV "Minimum predicted engine run torque capacity validity; Invalid = [1]";
CM_ SG_ 271 MinPrdtdEngRunTorqCap "Minimum predicted engine run torque capacity (minimum air flow, MBT spark)";
CM_ SG_ 271 MinImmedEngTorqCapV "Minimum immediate engine torque capacity validity; Invalid = [1]";
CM_ SG_ 271 MinImmedEngTorqCap "Minimum immediate engine torque capacity (current air flow, minimum spark)";
CM_ SG_ 271 MinEngTorqCapV "Minimum engine torque capacity validity; Invalid = [1]";
CM_ SG_ 271 MinEngTorqCap "Minimum engine torque capacity (min air flow, fuel off)";
CM_ SG_ 271 MinAirFlowMinSparkTorqCapV "Engine Torque capacity at minimum air flow and  minimum spark validity; Invalid = [1]";
CM_ SG_ 271 ETRQ_Mode "Enumeration of combustion torque mode";
CM_ SG_ 271 EngTrqReserveReq "Engine Torque Reserve Request";
CM_ SG_ 271 EngRunCrnkAct "ECM run crank terminal status, 1=active";
CM_ SG_ 271 EngOffRecom "Engine off recommendation";
CM_ SG_ 271 MinAirFlowMinSparkTorqCap "Engine Torque capacity at minimum air flow and  minimum spark";
CM_ SG_ 271 MessageCounter_ENGINE_HYBD_FD_1 "This signal is a counter used for safety checks strategies. This counter is incremented of 1 (one) unit at each frame transmission.";
CM_ SG_ 271 MaxPrdtdEngTorqCapV "Maximum predicted engine torque capacity validity; Invalid = [1]";
CM_ SG_ 271 MaxPrdtdEngTorqCap "Maximum predicted engine torque capacity";
CM_ SG_ 271 MaxOffEngTorqCap "Capacity Max-off";
CM_ SG_ 271 MAP_4_BAR_PHEV "Engine manifold pressure (4 bar range) 10ms cyclic";
CM_ SG_ 271 HybActEngTorqRespTyp "Hybrid Actual Engine Torque Response Type";
CM_ SG_ 271 Feedback_HCP "Indication that the ECM is receiving valid data from the HCP. 0 - False; 1 - True.";
CM_ SG_ 258 VehicleSpeedVSOSig "It is the average vehicle speed calculated.";
CM_ SG_ 476 MessageCounter_AGSM2 "This signal is a counter used for safety checks strategies. This counter is incremented of 1 (one) unit at each frame transmission.";
CM_ SG_ 476 CRC_AGSM2 "CRC according to SAE J1850 standard at each frame transmission.";
CM_ SG_ 476 ShiftLeverPositionReq "This signal describes the shift lever position requested by the driver.";
CM_ SG_ 2654486653 SourceNodeIdentifier "Source Node Identifier";
CM_ SG_ 2654486653 CBV_bit6_PartialNtwInfBit "Partial Network Information Bit (PNI)";
CM_ SG_ 2654486653 CBV_bit4_ActiveWakeupBit "Active Wakeup Bit";
CM_ SG_ 2654486653 CBV_bit3_NMCoordinatorBit "NM Coordinator Sleep Bit";
CM_ SG_ 2654486653 CBV_bit0_RepeatMessageRequestBit "Repeat Message Request Bit";
CM_ SG_ 2654486598 SourceNodeIdentifier "Source Node Identifier";
CM_ SG_ 2654486598 CBV_bit6_PartialNtwInfBit "Partial Network Information Bit (PNI)";
CM_ SG_ 2654486598 CBV_bit4_ActiveWakeupBit "Active Wakeup Bit";
CM_ SG_ 2654486598 CBV_bit3_NMCoordinatorBit "NM Coordinator Sleep Bit";
CM_ SG_ 2654486598 CBV_bit0_RepeatMessageRequestBit "Repeat Message Request Bit";
CM_ SG_ 1579 VDCM_UDCChrgr "For comm with charging station type B";
CM_ SG_ 1579 VDCM_IDCChrgr "For comm with charging station type B";
CM_ SG_ 1579 OBCM_PLUG_STS "Plug Status retrieved by the VDCM according to the proximity Sts and pilot Sts and current input available sent by the OBCM";
CM_ SG_ 1579 MessageCounter_HYBRID_CHARGING_ "This signal is a counter used for safety checks strategies. This counter is incremented of 1 (one) unit at each frame transmission.";
CM_ SG_ 1579 HVBatteryVoltage_MinCal "Minimum allowable HV battery voltage";
CM_ SG_ 1579 HVBatteryVoltage_MaxCal "Maximum allowable HV battery voltage";
CM_ SG_ 1579 HVBatteryCurrent_MaxCal "Maximum allowable HV battery current";
CM_ SG_ 1579 CRC_HYBRID_CHARGING_STATUS "CRC according to SAE J1850 standard at each frame transmission.";
CM_ SG_ 1579 ChargingLevel "Charging level and type.";
CM_ SG_ 1579 ChargeSystemSts "Charging System status";
CM_ SG_ 1579 ChargeSystemFaultReason "Charge System Fault Reason";
CM_ SG_ 1579 ChargeSystemFault "Charging System Fault status";
CM_ SG_ 1579 ACCurrent_MaxCal "Maximum allowable AC current";
CM_ SG_ 478 VoltageRequest "High Voltage Battery Voltage";
CM_ SG_ 478 VDCM_StsWldgReq "This signal indicates the welding check request from VDCM";
CM_ SG_ 478 VDCM_StsSWWldgReq "Software welding check request from VDCM";
CM_ SG_ 478 VDCM_SessnStopReq "This signal indicates the session stop request from VDCM";
CM_ SG_ 478 OBC_OperativeModeReq "This signal indicates the Onboard charger mode request";
CM_ SG_ 478 OBC_ControlMethod "Onboard charger commanded control method";
CM_ SG_ 478 MessageCounter_HYBRID_CHARGING_ "This signal is a counter used for safety checks strategies. This counter is incremented of 1 (one) unit at each frame transmission.";
CM_ SG_ 478 J1772_CloseS2 "J 1772 Close command";
CM_ SG_ 478 HVPowertrain_InterlockSts "Powertrain High voltage interlock state";
CM_ SG_ 478 HV_Volt_Min_Thrsh "This signal indicates the Commanded minimum Traction Battery Voltage to On Board Charger.";
CM_ SG_ 478 HV_Volt_Max_Thrsh "This signal indicates the Commanded maximum Traction Battery Voltage to On Board Charger.";
CM_ SG_ 478 DC_Curr_Max_Thrsh "Maximum Threshold for charging DC current.";
CM_ SG_ 478 CurrentRequest "HCP current request to the on board charger";
CM_ SG_ 478 CRC_HYBRID_CHARGING_COMMAND "CRC according to SAE J1850 standard at each frame transmission.";
CM_ SG_ 478 ClearLegislatedDiagInfo "Clear Legislated Diagnostic Information";
CM_ SG_ 478 ChargeEnable "Charge Enable";
CM_ SG_ 478 AC_Curr_Min_Thrsh "Commanded AC current min threshold to On Board Charge";
CM_ SG_ 478 AC_Curr_Max_Thrsh "Commanded AC current max threshold to On Board Charge";
CM_ SG_ 1578 OnboardChargerReady "OBCM Ready status";
CM_ SG_ 1578 OnboardChargerMode "OBCM operative mode";
CM_ SG_ 1578 OBCM_PrechargeSts "OBCM precharge status feedback";
CM_ SG_ 1578 OBC_WakeReason "OBCM wakeup status";
CM_ SG_ 1578 OBC_IdleTimeSec "On board charger idle time";
CM_ SG_ 1578 OBC_IdleTimeMin "On board charger idle time - long";
CM_ SG_ 1578 OBC_GenericFailSts ".";
CM_ SG_ 1578 OBC_FaultReason "OBCM Fault Reason";
CM_ SG_ 1578 OBC_EVServiceLampOn "Ev service On request from OBCM";
CM_ SG_ 1578 OBC_EVServiceLampFlash "Ev service LIGHT flash from OBCM";
CM_ SG_ 1578 OBC_CurrentFailureSts ".";
CM_ SG_ 1578 OBC_ChargingFaultSts "OBCM charging fault status";
CM_ SG_ 1578 OBC_ChargeTimeSec "On board charge time";
CM_ SG_ 1578 OBC_ChargeTimeMin "On board charge time - long";
CM_ SG_ 1578 OBC_ChargeFailure "0 = Open, 1 = Off/SNA";
CM_ SG_ 1578 OBC_CaptureEnvironmentData "Capture Environmental Data";
CM_ SG_ 1578 ChrgFailSts "TxMessageResponse from EVSE.";
CM_ SG_ 1578 Charging_WHr "Watt-hours of charge";
CM_ SG_ 1578 ACplug_PwrMax "Maximum  AC power limit";
CM_ SG_ 1372 OBC_Temp4 "OBCM temperature sensor 3";
CM_ SG_ 1372 OBC_Temp3 "OBCM temperature sensor 4";
CM_ SG_ 1372 OBC_Temp2 "OBCM temperature sensor 2";
CM_ SG_ 1372 OBC_Temp1 "OBCM temperature sensor 1";
CM_ SG_ 2564682064 N_PDU "This signal is used for diagnostic purposes";
CM_ SG_ 2564682320 N_PDU "This signal is used for diagnostic purposes";
CM_ SG_ 2564682308 N_PDU "This signal is used for diagnostic purposes";
CM_ SG_ 2564682052 N_PDU "This signal is used for diagnostic purposes";
CM_ SG_ 2564485712 N_PDU "This signal is used for diagnostic purposes";
CM_ SG_ 2564485700 N_PDU "This signal is used for diagnostic purposes";
CM_ SG_ 2564444402 N_PDU "This signal is used for diagnostic purposes";
CM_ SG_ 2564441330 N_PDU "This signal is used for diagnostic purposes";
CM_ SG_ 1845 HVBatSerialNumber "High Voltage Battery pack serial number, ASCII 8-bit encoded.";
CM_ SG_ 1845 HVBatSerialLength "Length of the High Voltage Battery pack's serial number (number of ASCII characters)";
CM_ SG_ 1460 FOTA_Status "FOTA_Status";
CM_ SG_ 1852 HVBatCellVoltage_Cell216 "High voltage battery cell voltage for Cell 216";
CM_ SG_ 1852 HVBatCellVoltage_Cell215 "High voltage battery cell voltage for Cell 215";
CM_ SG_ 1852 HVBatCellVoltage_Cell214 "High voltage battery cell voltage for Cell 214";
CM_ SG_ 1852 HVBatCellVoltage_Cell213 "High voltage battery cell voltage for Cell 213";
CM_ SG_ 1852 HVBatCellVoltage_Cell212 "High voltage battery cell voltage for Cell 212";
CM_ SG_ 1852 HVBatCellVoltage_Cell211 "High voltage battery cell voltage for Cell 211";
CM_ SG_ 1852 HVBatCellVoltage_Cell210 "High voltage battery cell voltage for Cell 210";
CM_ SG_ 1852 HVBatCellVoltage_Cell209 "High voltage battery cell voltage for Cell 209";
CM_ SG_ 1852 HVBatCellVoltage_Cell208 "High voltage battery cell voltage for Cell 208";
CM_ SG_ 1852 HVBatCellVoltage_Cell207 "High voltage battery cell voltage for Cell 207";
CM_ SG_ 1852 HVBatCellVoltage_Cell206 "High voltage battery cell voltage for Cell 206";
CM_ SG_ 1852 HVBatCellVoltage_Cell205 "High voltage battery cell voltage for Cell 205";
CM_ SG_ 1852 HVBatCellVoltage_Cell204 "High voltage battery cell voltage for Cell 204";
CM_ SG_ 1852 HVBatCellVoltage_Cell203 "High voltage battery cell voltage for Cell 203";
CM_ SG_ 1852 HVBatCellVoltage_Cell202 "High voltage battery cell voltage for Cell 202";
CM_ SG_ 1852 HVBatCellVoltage_Cell201 "High voltage battery cell voltage for Cell 201";
CM_ SG_ 1852 HVBatCellVoltage_Cell200 "High voltage battery cell voltage for Cell 200";
CM_ SG_ 1852 HVBatCellVoltage_Cell198 "High voltage battery cell voltage for Cell 198";
CM_ SG_ 1852 HVBatCellVoltage_Cell197 "High voltage battery cell voltage for Cell 197";
CM_ SG_ 1852 HVBatCellVoltage_Cell196 "High voltage battery cell voltage for Cell 196";
CM_ SG_ 1852 HVBatCellVoltage_Cell195 "High voltage battery cell voltage for Cell 195";
CM_ SG_ 1852 HVBatCellVoltage_Cell194 "High voltage battery cell voltage for Cell 194";
CM_ SG_ 1852 HVBatCellVoltage_Cell193 "High voltage battery cell voltage for Cell 193";
CM_ SG_ 1852 HVBatCellVoltage_Cell192 "High voltage battery cell voltage for Cell 192";
CM_ SG_ 1852 HVBatCellVoltage_Cell191 "High voltage battery cell voltage for Cell 191";
CM_ SG_ 1852 HVBatCellVoltage_Cell190 "High voltage battery cell voltage for Cell 190";
CM_ SG_ 1851 HVBatCellVoltage_Cell189 "High voltage battery cell voltage for Cell 189";
CM_ SG_ 1851 HVBatCellVoltage_Cell188 "High voltage battery cell voltage for Cell 188";
CM_ SG_ 1851 HVBatCellVoltage_Cell187 "High voltage battery cell voltage for Cell 187";
CM_ SG_ 1851 HVBatCellVoltage_Cell186 "High voltage battery cell voltage for Cell 186";
CM_ SG_ 1851 HVBatCellVoltage_Cell185 "High voltage battery cell voltage for Cell 185";
CM_ SG_ 1851 HVBatCellVoltage_Cell184 "High voltage battery cell voltage for Cell 184";
CM_ SG_ 1851 HVBatCellVoltage_Cell183 "High voltage battery cell voltage for Cell 183";
CM_ SG_ 1851 HVBatCellVoltage_Cell182 "High voltage battery cell voltage for Cell 182";
CM_ SG_ 1851 HVBatCellVoltage_Cell181 "High voltage battery cell voltage for Cell 181";
CM_ SG_ 1851 HVBatCellVoltage_Cell180 "High voltage battery cell voltage for Cell 180";
CM_ SG_ 1851 HVBatCellVoltage_Cell179 "High voltage battery cell voltage for Cell 179";
CM_ SG_ 1851 HVBatCellVoltage_Cell178 "High voltage battery cell voltage for Cell 178";
CM_ SG_ 1851 HVBatCellVoltage_Cell177 "High voltage battery cell voltage for Cell 177";
CM_ SG_ 1851 HVBatCellVoltage_Cell176 "High voltage battery cell voltage for Cell 176";
CM_ SG_ 1851 HVBatCellVoltage_Cell175 "High voltage battery cell voltage for Cell 175";
CM_ SG_ 1851 HVBatCellVoltage_Cell174 "High voltage battery cell voltage for Cell 174";
CM_ SG_ 1851 HVBatCellVoltage_Cell173 "High voltage battery cell voltage for Cell 173";
CM_ SG_ 1851 HVBatCellVoltage_Cell172 "High voltage battery cell voltage for Cell 172";
CM_ SG_ 1851 HVBatCellVoltage_Cell171 "High voltage battery cell voltage for Cell 171";
CM_ SG_ 1851 HVBatCellVoltage_Cell170 "High voltage battery cell voltage for Cell 170";
CM_ SG_ 1851 HVBatCellVoltage_Cell169 "High voltage battery cell voltage for Cell 169";
CM_ SG_ 1851 HVBatCellVoltage_Cell168 "High voltage battery cell voltage for Cell 168";
CM_ SG_ 1851 HVBatCellVoltage_Cell167 "High voltage battery cell voltage for Cell 167";
CM_ SG_ 1851 HVBatCellVoltage_Cell166 "High voltage battery cell voltage for Cell 166";
CM_ SG_ 1851 HVBatCellVoltage_Cell165 "High voltage battery cell voltage for Cell 165";
CM_ SG_ 1851 HVBatCellVoltage_Cell164 "High voltage battery cell voltage for Cell 164";
CM_ SG_ 1851 HVBatCellVoltage_Cell163 "High voltage battery cell voltage for Cell 163";
CM_ SG_ 1850 HVBatCellVoltage_Cell162 "High voltage battery cell voltage for Cell 162";
CM_ SG_ 1850 HVBatCellVoltage_Cell161 "High voltage battery cell voltage for Cell 161";
CM_ SG_ 1850 HVBatCellVoltage_Cell160 "High voltage battery cell voltage for Cell 160";
CM_ SG_ 1850 HVBatCellVoltage_Cell159 "High voltage battery cell voltage for Cell 159";
CM_ SG_ 1850 HVBatCellVoltage_Cell158 "High voltage battery cell voltage for Cell 158";
CM_ SG_ 1850 HVBatCellVoltage_Cell157 "High voltage battery cell voltage for Cell 157";
CM_ SG_ 1850 HVBatCellVoltage_Cell156 "High voltage battery cell voltage for Cell 156";
CM_ SG_ 1850 HVBatCellVoltage_Cell155 "High voltage battery cell voltage for Cell 155";
CM_ SG_ 1850 HVBatCellVoltage_Cell154 "High voltage battery cell voltage for Cell 154";
CM_ SG_ 1850 HVBatCellVoltage_Cell153 "High voltage battery cell voltage for Cell 153";
CM_ SG_ 1850 HVBatCellVoltage_Cell152 "High voltage battery cell voltage for Cell 152";
CM_ SG_ 1850 HVBatCellVoltage_Cell151 "High voltage battery cell voltage for Cell 151";
CM_ SG_ 1850 HVBatCellVoltage_Cell150 "High voltage battery cell voltage for Cell 150";
CM_ SG_ 1850 HVBatCellVoltage_Cell149 "High voltage battery cell voltage for Cell 149";
CM_ SG_ 1850 HVBatCellVoltage_Cell148 "High voltage battery cell voltage for Cell 148";
CM_ SG_ 1850 HVBatCellVoltage_Cell147 "High voltage battery cell voltage for Cell 147";
CM_ SG_ 1850 HVBatCellVoltage_Cell146 "High voltage battery cell voltage for Cell 146";
CM_ SG_ 1850 HVBatCellVoltage_Cell145 "High voltage battery cell voltage for Cell 145";
CM_ SG_ 1850 HVBatCellVoltage_Cell144 "High voltage battery cell voltage for Cell 144";
CM_ SG_ 1850 HVBatCellVoltage_Cell143 "High voltage battery cell voltage for Cell 143";
CM_ SG_ 1850 HVBatCellVoltage_Cell142 "High voltage battery cell voltage for Cell 142";
CM_ SG_ 1850 HVBatCellVoltage_Cell141 "High voltage battery cell voltage for Cell 141";
CM_ SG_ 1850 HVBatCellVoltage_Cell140 "High voltage battery cell voltage for Cell 140";
CM_ SG_ 1850 HVBatCellVoltage_Cell139 "High voltage battery cell voltage for Cell 139";
CM_ SG_ 1850 HVBatCellVoltage_Cell138 "High voltage battery cell voltage for Cell 138";
CM_ SG_ 1850 HVBatCellVoltage_Cell137 "High voltage battery cell voltage for Cell 137";
CM_ SG_ 1850 HVBatCellVoltage_Cell136 "High voltage battery cell voltage for Cell 136";
CM_ SG_ 1849 HVBatCellVoltage_Cell135 "High voltage battery cell voltage for Cell 135";
CM_ SG_ 1849 HVBatCellVoltage_Cell134 "High voltage battery cell voltage for Cell 134";
CM_ SG_ 1849 HVBatCellVoltage_Cell133 "High voltage battery cell voltage for Cell 133";
CM_ SG_ 1849 HVBatCellVoltage_Cell132 "High voltage battery cell voltage for Cell 132";
CM_ SG_ 1849 HVBatCellVoltage_Cell131 "High voltage battery cell voltage for Cell 131";
CM_ SG_ 1849 HVBatCellVoltage_Cell130 "High voltage battery cell voltage for Cell 130";
CM_ SG_ 1849 HVBatCellVoltage_Cell129 "High voltage battery cell voltage for Cell 129";
CM_ SG_ 1849 HVBatCellVoltage_Cell128 "High voltage battery cell voltage for Cell 128";
CM_ SG_ 1849 HVBatCellVoltage_Cell127 "High voltage battery cell voltage for Cell 127";
CM_ SG_ 1849 HVBatCellVoltage_Cell126 "High voltage battery cell voltage for Cell 126";
CM_ SG_ 1849 HVBatCellVoltage_Cell125 "High voltage battery cell voltage for Cell 125";
CM_ SG_ 1849 HVBatCellVoltage_Cell124 "High voltage battery cell voltage for Cell 124";
CM_ SG_ 1849 HVBatCellVoltage_Cell123 "High voltage battery cell voltage for Cell 123";
CM_ SG_ 1849 HVBatCellVoltage_Cell122 "High voltage battery cell voltage for Cell 122";
CM_ SG_ 1849 HVBatCellVoltage_Cell121 "High voltage battery cell voltage for Cell 121";
CM_ SG_ 1849 HVBatCellVoltage_Cell120 "High voltage battery cell voltage for Cell 120";
CM_ SG_ 1849 HVBatCellVoltage_Cell119 "High voltage battery cell voltage for Cell 119";
CM_ SG_ 1849 HVBatCellVoltage_Cell118 "High voltage battery cell voltage for Cell 118";
CM_ SG_ 1849 HVBatCellVoltage_Cell117 "High voltage battery cell voltage for Cell 117";
CM_ SG_ 1849 HVBatCellVoltage_Cell116 "High voltage battery cell voltage for Cell 116";
CM_ SG_ 1849 HVBatCellVoltage_Cell115 "High voltage battery cell voltage for Cell 115";
CM_ SG_ 1849 HVBatCellVoltage_Cell114 "High voltage battery cell voltage for Cell 114";
CM_ SG_ 1849 HVBatCellVoltage_Cell113 "High voltage battery cell voltage for Cell 113";
CM_ SG_ 1849 HVBatCellVoltage_Cell112 "High voltage battery cell voltage for Cell 112";
CM_ SG_ 1849 HVBatCellVoltage_Cell111 "High voltage battery cell voltage for Cell 111";
CM_ SG_ 1849 HVBatCellVoltage_Cell110 "High voltage battery cell voltage for Cell 110";
CM_ SG_ 1849 HVBatCellVoltage_Cell109 "High voltage battery cell voltage for Cell 109";
BA_DEF_ BO_ "CANFD_BRS" ENUM "0","1";
BA_DEF_ BO_ "VFrameFormat" ENUM "StandardCAN","ExtendedCAN","reserved","reserved","reserved","reserved","reserved","reserved","reserved","reserved","reserved","reserved","reserved","reserved","StandardCAN_FD","ExtendedCAN_FD";
BA_DEF_ BO_ "CanTpFcFrameId" HEX 0 2147483647;
BA_DEF_ BO_ "DiagConnection" HEX 0 65535;
BA_DEF_ BO_ "DiagState" ENUM "No","Yes";
BA_DEF_ BO_ "NmAsrMessage" ENUM "No","Yes";
BA_DEF_ BO_ "GenMsgDelayTime" INT 0 65535;
BA_DEF_ BO_ "GenMsgCycleTime" INT 0 65535;
BA_DEF_ BO_ "GenMsgCycleTimeFast" INT 0 65535;
BA_DEF_ BO_ "GenMsgStartDelayTime" INT 0 65535;
BA_DEF_ BO_ "GenMsgILSupport" ENUM "No","Yes";
BA_DEF_ BO_ "GenMsgNrOfRepetition" INT 0 255;
BA_DEF_ BO_ "GenMsgSendType" ENUM "Cyclic","NotUsed","NotUsed","NotUsed","NotUsed","NotUsed","NotUsed","NotUsed","NoMsgSendType";
BA_DEF_ BO_ "NmMessage" ENUM "No","Yes";
BA_DEF_ BO_ "DiagResponse" ENUM "No","Yes";
BA_DEF_ BO_ "Type" ENUM "P","C","PE","COC","PE_Cntrl","E","E_Cntrl","OC","S","BAF","DC","EM","MM","ISO-TP","-";
BA_DEF_ BO_ "DiagRequest" ENUM "No","Yes";
BA_DEF_ SG_ "GenSigTimeoutTime_SGW" INT 0 65535;
BA_DEF_ SG_ "GenSigTimeoutTime_PBWM" INT 0 65535;
BA_DEF_ SG_ "GenSigTimeoutTime_IDCM" INT 0 65535;
BA_DEF_ SG_ "GenSigTimeoutTime_EVCU2" INT 0 65535;
BA_DEF_ SG_ "GenSigTimeoutTime_ECM" INT 0 65535;
BA_DEF_ SG_ "GenSigTimeoutTime_DMPI" INT 0 65535;
BA_DEF_ SG_ "GenSigTimeoutTime_BPCM" INT 0 65535;
BA_DEF_ SG_ "GenSigTimeoutTime_AGSM" INT 0 65535;
BA_DEF_ SG_ "SystemSignalLongSymbol" STRING ;
BA_DEF_ SG_ "GenSigSendType" ENUM "NotUsed","OnWrite","OnWriteWithRepetition","OnChange","OnChangeWithRepetition","IfActive","IfActiveWithRepetition","NoSigSendType";
BA_DEF_ SG_ "GenSigInactiveValue" INT 0 2147483647;
BA_DEF_ SG_ "GenSigStartValue" INT 0 2147483647;
BA_DEF_DEF_ "CANFD_BRS" "0";
BA_DEF_DEF_ "VFrameFormat" "StandardCAN_FD";
BA_DEF_DEF_ "CanTpFcFrameId" 2147483647;
BA_DEF_DEF_ "DiagConnection" 0;
BA_DEF_DEF_ "DiagState" "No";
BA_DEF_DEF_ "NmAsrMessage" "No";
BA_DEF_DEF_ "GenMsgDelayTime" 0;
BA_DEF_DEF_ "GenMsgCycleTime" 0;
BA_DEF_DEF_ "GenMsgCycleTimeFast" 0;
BA_DEF_DEF_ "GenMsgStartDelayTime" 0;
BA_DEF_DEF_ "GenMsgILSupport" "No";
BA_DEF_DEF_ "GenMsgNrOfRepetition" 0;
BA_DEF_DEF_ "GenMsgSendType" "NoMsgSendType";
BA_DEF_DEF_ "NmMessage" "No";
BA_DEF_DEF_ "DiagResponse" "No";
BA_DEF_DEF_ "Type" "-";
BA_DEF_DEF_ "DiagRequest" "No";
BA_DEF_DEF_ "GenSigTimeoutTime_SGW" 2500;
BA_DEF_DEF_ "GenSigTimeoutTime_PBWM" 2500;
BA_DEF_DEF_ "GenSigTimeoutTime_IDCM" 2500;
BA_DEF_DEF_ "GenSigTimeoutTime_EVCU2" 2500;
BA_DEF_DEF_ "GenSigTimeoutTime_ECM" 2500;
BA_DEF_DEF_ "GenSigTimeoutTime_DMPI" 2500;
BA_DEF_DEF_ "GenSigTimeoutTime_BPCM" 2500;
BA_DEF_DEF_ "GenSigTimeoutTime_AGSM" 2500;
BA_DEF_DEF_ "SystemSignalLongSymbol" "";
BA_DEF_DEF_ "GenSigSendType" "NoSigSendType";
BA_DEF_DEF_ "GenSigInactiveValue" 0;
BA_DEF_DEF_ "GenSigStartValue" 0;
BA_ "CANFD_BRS" BO_ 276 1;
BA_ "GenMsgCycleTime" BO_ 276 10;
BA_ "GenMsgStartDelayTime" BO_ 276 10;
BA_ "GenMsgILSupport" BO_ 276 1;
BA_ "GenMsgSendType" BO_ 276 0;
BA_ "Type" BO_ 276 1;
BA_ "CANFD_BRS" BO_ 271 1;
BA_ "GenMsgCycleTime" BO_ 271 10;
BA_ "GenMsgILSupport" BO_ 271 1;
BA_ "GenMsgSendType" BO_ 271 0;
BA_ "Type" BO_ 271 1;
BA_ "CANFD_BRS" BO_ 258 1;
BA_ "GenMsgCycleTime" BO_ 258 10;
BA_ "GenMsgILSupport" BO_ 258 1;
BA_ "GenMsgSendType" BO_ 258 0;
BA_ "Type" BO_ 258 1;
BA_ "CANFD_BRS" BO_ 476 1;
BA_ "GenMsgDelayTime" BO_ 476 15;
BA_ "GenMsgCycleTime" BO_ 476 20;
BA_ "GenMsgCycleTimeFast" BO_ 476 20;
BA_ "GenMsgILSupport" BO_ 476 1;
BA_ "GenMsgNrOfRepetition" BO_ 476 2;
BA_ "GenMsgSendType" BO_ 476 0;
BA_ "Type" BO_ 476 3;
BA_ "CANFD_BRS" BO_ 2654486653 1;
BA_ "VFrameFormat" BO_ 2654486653 15;
BA_ "NmAsrMessage" BO_ 2654486653 1;
BA_ "NmMessage" BO_ 2654486653 1;
BA_ "Type" BO_ 2654486653 8;
BA_ "CANFD_BRS" BO_ 2654486598 1;
BA_ "VFrameFormat" BO_ 2654486598 15;
BA_ "NmAsrMessage" BO_ 2654486598 1;
BA_ "NmMessage" BO_ 2654486598 1;
BA_ "Type" BO_ 2654486598 8;
BA_ "CANFD_BRS" BO_ 1579 1;
BA_ "GenMsgCycleTime" BO_ 1579 500;
BA_ "GenMsgILSupport" BO_ 1579 1;
BA_ "GenMsgSendType" BO_ 1579 0;
BA_ "Type" BO_ 1579 1;
BA_ "CANFD_BRS" BO_ 478 1;
BA_ "GenMsgCycleTime" BO_ 478 20;
BA_ "GenMsgILSupport" BO_ 478 1;
BA_ "GenMsgSendType" BO_ 478 0;
BA_ "Type" BO_ 478 1;
BA_ "CANFD_BRS" BO_ 1578 1;
BA_ "GenMsgCycleTime" BO_ 1578 500;
BA_ "GenMsgCycleTimeFast" BO_ 1578 10;
BA_ "GenMsgILSupport" BO_ 1578 1;
BA_ "GenMsgNrOfRepetition" BO_ 1578 3;
BA_ "GenMsgSendType" BO_ 1578 0;
BA_ "Type" BO_ 1578 3;
BA_ "CANFD_BRS" BO_ 1372 1;
BA_ "GenMsgCycleTime" BO_ 1372 250;
BA_ "GenMsgILSupport" BO_ 1372 1;
BA_ "GenMsgSendType" BO_ 1372 0;
BA_ "Type" BO_ 1372 1;
BA_ "VFrameFormat" BO_ 2564682064 1;
BA_ "DiagConnection" BO_ 2564682064 61776;
BA_ "DiagResponse" BO_ 2564682064 1;
BA_ "Type" BO_ 2564682064 8;
BA_ "CANFD_BRS" BO_ 2564682320 1;
BA_ "VFrameFormat" BO_ 2564682320 15;
BA_ "DiagConnection" BO_ 2564682320 62032;
BA_ "DiagResponse" BO_ 2564682320 1;
BA_ "Type" BO_ 2564682320 8;
BA_ "CANFD_BRS" BO_ 2564682308 1;
BA_ "VFrameFormat" BO_ 2564682308 15;
BA_ "DiagConnection" BO_ 2564682308 62020;
BA_ "DiagResponse" BO_ 2564682308 1;
BA_ "Type" BO_ 2564682308 8;
BA_ "VFrameFormat" BO_ 2564682052 1;
BA_ "DiagConnection" BO_ 2564682052 61764;
BA_ "DiagResponse" BO_ 2564682052 1;
BA_ "Type" BO_ 2564682052 8;
BA_ "DiagResponse" BO_ 2564485712 1;
BA_ "Type" BO_ 2564485712 8;
BA_ "CANFD_BRS" BO_ 2564485712 1;
BA_ "VFrameFormat" BO_ 2564485712 15;
BA_ "DiagConnection" BO_ 2564485712 62032;
BA_ "CANFD_BRS" BO_ 2564485700 1;
BA_ "VFrameFormat" BO_ 2564485700 15;
BA_ "DiagConnection" BO_ 2564485700 62020;
BA_ "DiagResponse" BO_ 2564485700 1;
BA_ "Type" BO_ 2564485700 8;
BA_ "CANFD_BRS" BO_ 2564444402 1;
BA_ "VFrameFormat" BO_ 2564444402 15;
BA_ "DiagConnection" BO_ 2564444402 62032;
BA_ "Type" BO_ 2564444402 8;
BA_ "DiagRequest" BO_ 2564444402 1;
BA_ "CANFD_BRS" BO_ 2564441330 1;
BA_ "VFrameFormat" BO_ 2564441330 15;
BA_ "DiagConnection" BO_ 2564441330 62020;
BA_ "Type" BO_ 2564441330 8;
BA_ "DiagRequest" BO_ 2564441330 1;
BA_ "CANFD_BRS" BO_ 1845 1;
BA_ "GenMsgCycleTime" BO_ 1845 1000;
BA_ "GenMsgILSupport" BO_ 1845 1;
BA_ "GenMsgSendType" BO_ 1845 0;
BA_ "Type" BO_ 1845 1;
BA_ "CANFD_BRS" BO_ 1460 1;
BA_ "GenMsgDelayTime" BO_ 1460 20;
BA_ "GenMsgCycleTime" BO_ 1460 1000;
BA_ "GenMsgILSupport" BO_ 1460 1;
BA_ "GenMsgSendType" BO_ 1460 0;
BA_ "Type" BO_ 1460 3;
BA_ "CANFD_BRS" BO_ 1852 1;
BA_ "GenMsgCycleTime" BO_ 1852 1000;
BA_ "GenMsgILSupport" BO_ 1852 1;
BA_ "GenMsgSendType" BO_ 1852 0;
BA_ "Type" BO_ 1852 1;
BA_ "CANFD_BRS" BO_ 1851 1;
BA_ "GenMsgCycleTime" BO_ 1851 1000;
BA_ "GenMsgILSupport" BO_ 1851 1;
BA_ "GenMsgSendType" BO_ 1851 0;
BA_ "Type" BO_ 1851 1;
BA_ "CANFD_BRS" BO_ 1850 1;
BA_ "GenMsgCycleTime" BO_ 1850 1000;
BA_ "GenMsgILSupport" BO_ 1850 1;
BA_ "GenMsgSendType" BO_ 1850 0;
BA_ "Type" BO_ 1850 1;
BA_ "CANFD_BRS" BO_ 1849 1;
BA_ "GenMsgCycleTime" BO_ 1849 1000;
BA_ "GenMsgILSupport" BO_ 1849 1;
BA_ "GenMsgSendType" BO_ 1849 0;
BA_ "Type" BO_ 1849 1;
BA_ "GenSigTimeoutTime_SGW" SG_ 276 ECMPrepIdleRes 0;
BA_ "GenSigTimeoutTime_PBWM" SG_ 276 ECMPrepIdleRes 0;
BA_ "GenSigTimeoutTime_IDCM" SG_ 276 ECMPrepIdleRes 0;
BA_ "GenSigTimeoutTime_EVCU2" SG_ 276 ECMPrepIdleRes 0;
BA_ "GenSigTimeoutTime_DMPI" SG_ 276 ECMPrepIdleRes 0;
BA_ "GenSigTimeoutTime_BPCM" SG_ 276 ECMPrepIdleRes 0;
BA_ "GenSigTimeoutTime_AGSM" SG_ 276 ECMPrepIdleRes 0;
BA_ "GenSigTimeoutTime_SGW" SG_ 276 CRC_HYBRID_POWERTRAIN1 0;
BA_ "GenSigTimeoutTime_PBWM" SG_ 276 CRC_HYBRID_POWERTRAIN1 0;
BA_ "GenSigTimeoutTime_IDCM" SG_ 276 CRC_HYBRID_POWERTRAIN1 0;
BA_ "GenSigTimeoutTime_EVCU2" SG_ 276 CRC_HYBRID_POWERTRAIN1 0;
BA_ "GenSigTimeoutTime_DMPI" SG_ 276 CRC_HYBRID_POWERTRAIN1 0;
BA_ "GenSigTimeoutTime_BPCM" SG_ 276 CRC_HYBRID_POWERTRAIN1 0;
BA_ "GenSigTimeoutTime_AGSM" SG_ 276 CRC_HYBRID_POWERTRAIN1 0;
BA_ "GenSigTimeoutTime_SGW" SG_ 276 EngCntrlMode 0;
BA_ "GenSigTimeoutTime_PBWM" SG_ 276 EngCntrlMode 0;
BA_ "GenSigTimeoutTime_IDCM" SG_ 276 EngCntrlMode 0;
BA_ "GenSigTimeoutTime_EVCU2" SG_ 276 EngCntrlMode 0;
BA_ "GenSigTimeoutTime_DMPI" SG_ 276 EngCntrlMode 0;
BA_ "GenSigTimeoutTime_BPCM" SG_ 276 EngCntrlMode 0;
BA_ "GenSigTimeoutTime_AGSM" SG_ 276 EngCntrlMode 0;
BA_ "GenSigTimeoutTime_SGW" SG_ 276 EngTrqReserveCmd 0;
BA_ "GenSigTimeoutTime_PBWM" SG_ 276 EngTrqReserveCmd 0;
BA_ "GenSigTimeoutTime_IDCM" SG_ 276 EngTrqReserveCmd 0;
BA_ "GenSigTimeoutTime_EVCU2" SG_ 276 EngTrqReserveCmd 0;
BA_ "GenSigTimeoutTime_DMPI" SG_ 276 EngTrqReserveCmd 0;
BA_ "GenSigTimeoutTime_BPCM" SG_ 276 EngTrqReserveCmd 0;
BA_ "GenSigTimeoutTime_AGSM" SG_ 276 EngTrqReserveCmd 0;
BA_ "GenSigTimeoutTime_SGW" SG_ 276 HybCmndEngTorqImmed 0;
BA_ "GenSigTimeoutTime_PBWM" SG_ 276 HybCmndEngTorqImmed 0;
BA_ "GenSigTimeoutTime_IDCM" SG_ 276 HybCmndEngTorqImmed 0;
BA_ "GenSigTimeoutTime_EVCU2" SG_ 276 HybCmndEngTorqImmed 0;
BA_ "GenSigTimeoutTime_DMPI" SG_ 276 HybCmndEngTorqImmed 0;
BA_ "GenSigTimeoutTime_BPCM" SG_ 276 HybCmndEngTorqImmed 0;
BA_ "GenSigTimeoutTime_AGSM" SG_ 276 HybCmndEngTorqImmed 0;
BA_ "GenSigStartValue" SG_ 276 HybCmndEngTorqImmed 938;
BA_ "GenSigTimeoutTime_SGW" SG_ 276 HybCmndEngTorqPrdtd 0;
BA_ "GenSigTimeoutTime_PBWM" SG_ 276 HybCmndEngTorqPrdtd 0;
BA_ "GenSigTimeoutTime_IDCM" SG_ 276 HybCmndEngTorqPrdtd 0;
BA_ "GenSigTimeoutTime_EVCU2" SG_ 276 HybCmndEngTorqPrdtd 0;
BA_ "GenSigTimeoutTime_DMPI" SG_ 276 HybCmndEngTorqPrdtd 0;
BA_ "GenSigTimeoutTime_BPCM" SG_ 276 HybCmndEngTorqPrdtd 0;
BA_ "GenSigTimeoutTime_AGSM" SG_ 276 HybCmndEngTorqPrdtd 0;
BA_ "GenSigStartValue" SG_ 276 HybCmndEngTorqPrdtd 938;
BA_ "GenSigTimeoutTime_SGW" SG_ 276 HybCmndEngTorqRespTyp 0;
BA_ "GenSigTimeoutTime_PBWM" SG_ 276 HybCmndEngTorqRespTyp 0;
BA_ "GenSigTimeoutTime_IDCM" SG_ 276 HybCmndEngTorqRespTyp 0;
BA_ "GenSigTimeoutTime_EVCU2" SG_ 276 HybCmndEngTorqRespTyp 0;
BA_ "GenSigTimeoutTime_DMPI" SG_ 276 HybCmndEngTorqRespTyp 0;
BA_ "GenSigTimeoutTime_BPCM" SG_ 276 HybCmndEngTorqRespTyp 0;
BA_ "GenSigTimeoutTime_AGSM" SG_ 276 HybCmndEngTorqRespTyp 0;
BA_ "GenSigTimeoutTime_SGW" SG_ 276 HybCrnkAbrted 0;
BA_ "GenSigTimeoutTime_PBWM" SG_ 276 HybCrnkAbrted 0;
BA_ "GenSigTimeoutTime_IDCM" SG_ 276 HybCrnkAbrted 0;
BA_ "GenSigTimeoutTime_EVCU2" SG_ 276 HybCrnkAbrted 0;
BA_ "GenSigTimeoutTime_DMPI" SG_ 276 HybCrnkAbrted 0;
BA_ "GenSigTimeoutTime_BPCM" SG_ 276 HybCrnkAbrted 0;
BA_ "GenSigTimeoutTime_AGSM" SG_ 276 HybCrnkAbrted 0;
BA_ "GenSigTimeoutTime_SGW" SG_ 276 HybEstEngTorq 0;
BA_ "GenSigTimeoutTime_PBWM" SG_ 276 HybEstEngTorq 0;
BA_ "GenSigTimeoutTime_IDCM" SG_ 276 HybEstEngTorq 0;
BA_ "GenSigTimeoutTime_EVCU2" SG_ 276 HybEstEngTorq 0;
BA_ "GenSigTimeoutTime_DMPI" SG_ 276 HybEstEngTorq 0;
BA_ "GenSigTimeoutTime_BPCM" SG_ 276 HybEstEngTorq 0;
BA_ "GenSigTimeoutTime_AGSM" SG_ 276 HybEstEngTorq 0;
BA_ "GenSigStartValue" SG_ 276 HybEstEngTorq 938;
BA_ "GenSigTimeoutTime_SGW" SG_ 276 HybEstEngTorqV 0;
BA_ "GenSigTimeoutTime_PBWM" SG_ 276 HybEstEngTorqV 0;
BA_ "GenSigTimeoutTime_IDCM" SG_ 276 HybEstEngTorqV 0;
BA_ "GenSigTimeoutTime_EVCU2" SG_ 276 HybEstEngTorqV 0;
BA_ "GenSigTimeoutTime_DMPI" SG_ 276 HybEstEngTorqV 0;
BA_ "GenSigTimeoutTime_BPCM" SG_ 276 HybEstEngTorqV 0;
BA_ "GenSigTimeoutTime_AGSM" SG_ 276 HybEstEngTorqV 0;
BA_ "GenSigTimeoutTime_SGW" SG_ 276 HybFeedback_Engine 0;
BA_ "GenSigTimeoutTime_PBWM" SG_ 276 HybFeedback_Engine 0;
BA_ "GenSigTimeoutTime_IDCM" SG_ 276 HybFeedback_Engine 0;
BA_ "GenSigTimeoutTime_EVCU2" SG_ 276 HybFeedback_Engine 0;
BA_ "GenSigTimeoutTime_DMPI" SG_ 276 HybFeedback_Engine 0;
BA_ "GenSigTimeoutTime_BPCM" SG_ 276 HybFeedback_Engine 0;
BA_ "GenSigTimeoutTime_AGSM" SG_ 276 HybFeedback_Engine 0;
BA_ "GenSigTimeoutTime_EVCU2" SG_ 276 Hybrid_Remedial_Stop 0;
BA_ "GenSigTimeoutTime_DMPI" SG_ 276 Hybrid_Remedial_Stop 0;
BA_ "GenSigTimeoutTime_BPCM" SG_ 276 Hybrid_Remedial_Stop 0;
BA_ "GenSigTimeoutTime_AGSM" SG_ 276 Hybrid_Remedial_Stop 0;
BA_ "GenSigTimeoutTime_SGW" SG_ 276 HybFstTrqRq_Trans 0;
BA_ "GenSigTimeoutTime_PBWM" SG_ 276 HybFstTrqRq_Trans 0;
BA_ "GenSigTimeoutTime_IDCM" SG_ 276 HybFstTrqRq_Trans 0;
BA_ "GenSigTimeoutTime_EVCU2" SG_ 276 HybFstTrqRq_Trans 0;
BA_ "GenSigTimeoutTime_DMPI" SG_ 276 HybFstTrqRq_Trans 0;
BA_ "GenSigTimeoutTime_BPCM" SG_ 276 HybFstTrqRq_Trans 0;
BA_ "GenSigTimeoutTime_AGSM" SG_ 276 HybFstTrqRq_Trans 0;
BA_ "GenSigTimeoutTime_BPCM" SG_ 478 VoltageRequest 0;
BA_ "GenSigTimeoutTime_AGSM" SG_ 478 VoltageRequest 0;
BA_ "GenSigTimeoutTime_SGW" SG_ 478 VoltageRequest 0;
BA_ "GenSigTimeoutTime_PBWM" SG_ 478 VoltageRequest 0;
BA_ "GenSigTimeoutTime_EVCU2" SG_ 478 VoltageRequest 0;
BA_ "GenSigTimeoutTime_ECM" SG_ 478 VoltageRequest 0;
BA_ "GenSigTimeoutTime_DMPI" SG_ 478 VoltageRequest 0;
BA_ "GenSigTimeoutTime_SGW" SG_ 1579 MessageCounter_HYBRID_CHARGING_ 0;
BA_ "GenSigTimeoutTime_PBWM" SG_ 1579 MessageCounter_HYBRID_CHARGING_ 0;
BA_ "GenSigTimeoutTime_EVCU2" SG_ 1579 MessageCounter_HYBRID_CHARGING_ 0;
BA_ "GenSigTimeoutTime_ECM" SG_ 1579 MessageCounter_HYBRID_CHARGING_ 0;
BA_ "GenSigTimeoutTime_DMPI" SG_ 1579 MessageCounter_HYBRID_CHARGING_ 0;
BA_ "GenSigTimeoutTime_BPCM" SG_ 1579 MessageCounter_HYBRID_CHARGING_ 0;
BA_ "GenSigTimeoutTime_AGSM" SG_ 1579 MessageCounter_HYBRID_CHARGING_ 0;
BA_ "SystemSignalLongSymbol" SG_ 1579 MessageCounter_HYBRID_CHARGING_ "MessageCounter_HYBRID_CHARGING_STATUS";
BA_ "GenSigTimeoutTime_SGW" SG_ 1579 ACCurrent_MaxCal 0;
BA_ "GenSigTimeoutTime_PBWM" SG_ 1579 ACCurrent_MaxCal 0;
BA_ "GenSigTimeoutTime_EVCU2" SG_ 1579 ACCurrent_MaxCal 0;
BA_ "GenSigTimeoutTime_ECM" SG_ 1579 ACCurrent_MaxCal 0;
BA_ "GenSigTimeoutTime_DMPI" SG_ 1579 ACCurrent_MaxCal 0;
BA_ "GenSigTimeoutTime_AGSM" SG_ 1579 ACCurrent_MaxCal 0;
BA_ "GenSigTimeoutTime_SGW" SG_ 1579 ChargeSystemFaultReason 0;
BA_ "GenSigTimeoutTime_PBWM" SG_ 1579 ChargeSystemFaultReason 0;
BA_ "GenSigTimeoutTime_EVCU2" SG_ 1579 ChargeSystemFaultReason 0;
BA_ "GenSigTimeoutTime_ECM" SG_ 1579 ChargeSystemFaultReason 0;
BA_ "GenSigTimeoutTime_DMPI" SG_ 1579 ChargeSystemFaultReason 0;
BA_ "GenSigTimeoutTime_BPCM" SG_ 1579 ChargeSystemFaultReason 0;
BA_ "GenSigTimeoutTime_AGSM" SG_ 1579 ChargeSystemFaultReason 0;
BA_ "GenSigTimeoutTime_SGW" SG_ 1579 HVBatteryCurrent_MaxCal 0;
BA_ "GenSigTimeoutTime_PBWM" SG_ 1579 HVBatteryCurrent_MaxCal 0;
BA_ "GenSigTimeoutTime_EVCU2" SG_ 1579 HVBatteryCurrent_MaxCal 0;
BA_ "GenSigTimeoutTime_ECM" SG_ 1579 HVBatteryCurrent_MaxCal 0;
BA_ "GenSigTimeoutTime_DMPI" SG_ 1579 HVBatteryCurrent_MaxCal 0;
BA_ "GenSigTimeoutTime_AGSM" SG_ 1579 HVBatteryCurrent_MaxCal 0;
BA_ "GenSigTimeoutTime_SGW" SG_ 1579 HVBatteryVoltage_MaxCal 0;
BA_ "GenSigTimeoutTime_PBWM" SG_ 1579 HVBatteryVoltage_MaxCal 0;
BA_ "GenSigTimeoutTime_EVCU2" SG_ 1579 HVBatteryVoltage_MaxCal 0;
BA_ "GenSigTimeoutTime_ECM" SG_ 1579 HVBatteryVoltage_MaxCal 0;
BA_ "GenSigTimeoutTime_DMPI" SG_ 1579 HVBatteryVoltage_MaxCal 0;
BA_ "GenSigTimeoutTime_AGSM" SG_ 1579 HVBatteryVoltage_MaxCal 0;
BA_ "GenSigTimeoutTime_SGW" SG_ 1579 HVBatteryVoltage_MinCal 0;
BA_ "GenSigTimeoutTime_PBWM" SG_ 1579 HVBatteryVoltage_MinCal 0;
BA_ "GenSigTimeoutTime_EVCU2" SG_ 1579 HVBatteryVoltage_MinCal 0;
BA_ "GenSigTimeoutTime_ECM" SG_ 1579 HVBatteryVoltage_MinCal 0;
BA_ "GenSigTimeoutTime_DMPI" SG_ 1579 HVBatteryVoltage_MinCal 0;
BA_ "GenSigTimeoutTime_AGSM" SG_ 1579 HVBatteryVoltage_MinCal 0;
BA_ "GenSigTimeoutTime_PBWM" SG_ 1579 ChargingLevel 0;
BA_ "GenSigTimeoutTime_EVCU2" SG_ 1579 ChargingLevel 0;
BA_ "GenSigTimeoutTime_ECM" SG_ 1579 ChargingLevel 0;
BA_ "GenSigTimeoutTime_DMPI" SG_ 1579 ChargingLevel 0;
BA_ "GenSigTimeoutTime_AGSM" SG_ 1579 ChargingLevel 0;
BA_ "GenSigTimeoutTime_SGW" SG_ 478 VDCM_StsSWWldgReq 0;
BA_ "GenSigTimeoutTime_PBWM" SG_ 478 VDCM_StsSWWldgReq 0;
BA_ "GenSigTimeoutTime_IDCM" SG_ 478 VDCM_StsSWWldgReq 0;
BA_ "GenSigTimeoutTime_EVCU2" SG_ 478 VDCM_StsSWWldgReq 0;
BA_ "GenSigTimeoutTime_ECM" SG_ 478 VDCM_StsSWWldgReq 0;
BA_ "GenSigTimeoutTime_DMPI" SG_ 478 VDCM_StsSWWldgReq 0;
BA_ "GenSigTimeoutTime_BPCM" SG_ 478 VDCM_StsSWWldgReq 0;
BA_ "GenSigTimeoutTime_AGSM" SG_ 478 VDCM_StsSWWldgReq 0;
BA_ "GenSigTimeoutTime_SGW" SG_ 1579 CRC_HYBRID_CHARGING_STATUS 0;
BA_ "GenSigTimeoutTime_PBWM" SG_ 1579 CRC_HYBRID_CHARGING_STATUS 0;
BA_ "GenSigTimeoutTime_EVCU2" SG_ 1579 CRC_HYBRID_CHARGING_STATUS 0;
BA_ "GenSigTimeoutTime_ECM" SG_ 1579 CRC_HYBRID_CHARGING_STATUS 0;
BA_ "GenSigTimeoutTime_DMPI" SG_ 1579 CRC_HYBRID_CHARGING_STATUS 0;
BA_ "GenSigTimeoutTime_BPCM" SG_ 1579 CRC_HYBRID_CHARGING_STATUS 0;
BA_ "GenSigTimeoutTime_AGSM" SG_ 1579 CRC_HYBRID_CHARGING_STATUS 0;
BA_ "GenSigTimeoutTime_SGW" SG_ 1579 VDCM_IDCChrgr 0;
BA_ "GenSigTimeoutTime_PBWM" SG_ 1579 VDCM_IDCChrgr 0;
BA_ "GenSigTimeoutTime_EVCU2" SG_ 1579 VDCM_IDCChrgr 0;
BA_ "GenSigTimeoutTime_ECM" SG_ 1579 VDCM_IDCChrgr 0;
BA_ "GenSigTimeoutTime_DMPI" SG_ 1579 VDCM_IDCChrgr 0;
BA_ "GenSigTimeoutTime_BPCM" SG_ 1579 VDCM_IDCChrgr 0;
BA_ "GenSigTimeoutTime_AGSM" SG_ 1579 VDCM_IDCChrgr 0;
BA_ "GenSigTimeoutTime_SGW" SG_ 1579 VDCM_UDCChrgr 0;
BA_ "GenSigTimeoutTime_PBWM" SG_ 1579 VDCM_UDCChrgr 0;
BA_ "GenSigTimeoutTime_EVCU2" SG_ 1579 VDCM_UDCChrgr 0;
BA_ "GenSigTimeoutTime_ECM" SG_ 1579 VDCM_UDCChrgr 0;
BA_ "GenSigTimeoutTime_DMPI" SG_ 1579 VDCM_UDCChrgr 0;
BA_ "GenSigTimeoutTime_BPCM" SG_ 1579 VDCM_UDCChrgr 0;
BA_ "GenSigTimeoutTime_AGSM" SG_ 1579 VDCM_UDCChrgr 0;
BA_ "GenSigTimeoutTime_SGW" SG_ 1579 ChargeSystemFault 0;
BA_ "GenSigTimeoutTime_PBWM" SG_ 1579 ChargeSystemFault 0;
BA_ "GenSigTimeoutTime_EVCU2" SG_ 1579 ChargeSystemFault 0;
BA_ "GenSigTimeoutTime_ECM" SG_ 1579 ChargeSystemFault 0;
BA_ "GenSigTimeoutTime_DMPI" SG_ 1579 ChargeSystemFault 0;
BA_ "GenSigTimeoutTime_BPCM" SG_ 1579 ChargeSystemFault 0;
BA_ "GenSigTimeoutTime_AGSM" SG_ 1579 ChargeSystemFault 0;
BA_ "GenSigTimeoutTime_SGW" SG_ 1579 ChargeSystemSts 0;
BA_ "GenSigTimeoutTime_PBWM" SG_ 1579 ChargeSystemSts 0;
BA_ "GenSigTimeoutTime_EVCU2" SG_ 1579 ChargeSystemSts 0;
BA_ "GenSigTimeoutTime_ECM" SG_ 1579 ChargeSystemSts 0;
BA_ "GenSigTimeoutTime_DMPI" SG_ 1579 ChargeSystemSts 0;
BA_ "GenSigTimeoutTime_AGSM" SG_ 1579 ChargeSystemSts 0;
BA_ "GenSigTimeoutTime_SGW" SG_ 478 OBC_OperativeModeReq 0;
BA_ "GenSigTimeoutTime_PBWM" SG_ 478 OBC_OperativeModeReq 0;
BA_ "GenSigTimeoutTime_EVCU2" SG_ 478 OBC_OperativeModeReq 0;
BA_ "GenSigTimeoutTime_SGW" SG_ 1579 OBCM_PLUG_STS 0;
BA_ "GenSigTimeoutTime_PBWM" SG_ 1579 OBCM_PLUG_STS 0;
BA_ "GenSigTimeoutTime_EVCU2" SG_ 1579 OBCM_PLUG_STS 0;
BA_ "GenSigTimeoutTime_ECM" SG_ 1579 OBCM_PLUG_STS 0;
BA_ "GenSigTimeoutTime_DMPI" SG_ 1579 OBCM_PLUG_STS 0;
BA_ "GenSigTimeoutTime_BPCM" SG_ 1579 OBCM_PLUG_STS 0;
BA_ "GenSigTimeoutTime_AGSM" SG_ 1579 OBCM_PLUG_STS 0;
BA_ "GenSigTimeoutTime_SGW" SG_ 478 VDCM_SessnStopReq 0;
BA_ "GenSigTimeoutTime_PBWM" SG_ 478 VDCM_SessnStopReq 0;
BA_ "GenSigTimeoutTime_EVCU2" SG_ 478 VDCM_SessnStopReq 0;
BA_ "GenSigTimeoutTime_ECM" SG_ 478 VDCM_SessnStopReq 0;
BA_ "GenSigTimeoutTime_DMPI" SG_ 478 VDCM_SessnStopReq 0;
BA_ "GenSigTimeoutTime_BPCM" SG_ 478 VDCM_SessnStopReq 0;
BA_ "GenSigTimeoutTime_AGSM" SG_ 478 VDCM_SessnStopReq 0;
BA_ "GenSigTimeoutTime_SGW" SG_ 478 VDCM_StsWldgReq 0;
BA_ "GenSigTimeoutTime_PBWM" SG_ 478 VDCM_StsWldgReq 0;
BA_ "GenSigTimeoutTime_EVCU2" SG_ 478 VDCM_StsWldgReq 0;
BA_ "GenSigTimeoutTime_ECM" SG_ 478 VDCM_StsWldgReq 0;
BA_ "GenSigTimeoutTime_DMPI" SG_ 478 VDCM_StsWldgReq 0;
BA_ "GenSigTimeoutTime_BPCM" SG_ 478 VDCM_StsWldgReq 0;
BA_ "GenSigTimeoutTime_AGSM" SG_ 478 VDCM_StsWldgReq 0;
BA_ "GenSigTimeoutTime_PBWM" SG_ 1852 HVBatCellVoltage_Cell216 0;
BA_ "GenSigTimeoutTime_IDCM" SG_ 1852 HVBatCellVoltage_Cell216 0;
BA_ "GenSigTimeoutTime_IDCM" SG_ 1851 HVBatCellVoltage_Cell188 0;
BA_ "GenSigTimeoutTime_EVCU2" SG_ 1851 HVBatCellVoltage_Cell188 0;
BA_ "GenSigTimeoutTime_ECM" SG_ 1851 HVBatCellVoltage_Cell188 0;
BA_ "GenSigTimeoutTime_DMPI" SG_ 1851 HVBatCellVoltage_Cell188 0;
BA_ "GenSigTimeoutTime_BPCM" SG_ 1851 HVBatCellVoltage_Cell188 0;
BA_ "GenSigTimeoutTime_AGSM" SG_ 1851 HVBatCellVoltage_Cell188 0;
BA_ "GenSigTimeoutTime_SGW" SG_ 1851 HVBatCellVoltage_Cell187 0;
BA_ "GenSigTimeoutTime_PBWM" SG_ 1851 HVBatCellVoltage_Cell187 0;
BA_ "GenSigTimeoutTime_IDCM" SG_ 1851 HVBatCellVoltage_Cell187 0;
BA_ "GenSigTimeoutTime_EVCU2" SG_ 1851 HVBatCellVoltage_Cell187 0;
BA_ "GenSigTimeoutTime_ECM" SG_ 1851 HVBatCellVoltage_Cell187 0;
BA_ "GenSigTimeoutTime_DMPI" SG_ 1851 HVBatCellVoltage_Cell187 0;
BA_ "GenSigTimeoutTime_BPCM" SG_ 1851 HVBatCellVoltage_Cell187 0;
BA_ "GenSigTimeoutTime_AGSM" SG_ 1851 HVBatCellVoltage_Cell187 0;
BA_ "GenSigTimeoutTime_SGW" SG_ 1851 HVBatCellVoltage_Cell185 0;
BA_ "GenSigTimeoutTime_PBWM" SG_ 1851 HVBatCellVoltage_Cell185 0;
BA_ "GenSigTimeoutTime_IDCM" SG_ 1851 HVBatCellVoltage_Cell185 0;
BA_ "GenSigTimeoutTime_EVCU2" SG_ 1851 HVBatCellVoltage_Cell185 0;
BA_ "GenSigTimeoutTime_ECM" SG_ 1851 HVBatCellVoltage_Cell185 0;
BA_ "GenSigTimeoutTime_DMPI" SG_ 1851 HVBatCellVoltage_Cell185 0;
BA_ "GenSigTimeoutTime_BPCM" SG_ 1851 HVBatCellVoltage_Cell185 0;
BA_ "GenSigTimeoutTime_AGSM" SG_ 1851 HVBatCellVoltage_Cell185 0;
BA_ "GenSigTimeoutTime_SGW" SG_ 1851 HVBatCellVoltage_Cell186 0;
BA_ "GenSigTimeoutTime_PBWM" SG_ 1851 HVBatCellVoltage_Cell186 0;
BA_ "GenSigTimeoutTime_IDCM" SG_ 1851 HVBatCellVoltage_Cell186 0;
BA_ "GenSigTimeoutTime_EVCU2" SG_ 1851 HVBatCellVoltage_Cell186 0;
BA_ "GenSigTimeoutTime_ECM" SG_ 1851 HVBatCellVoltage_Cell186 0;
BA_ "GenSigTimeoutTime_DMPI" SG_ 1851 HVBatCellVoltage_Cell186 0;
BA_ "GenSigTimeoutTime_BPCM" SG_ 1851 HVBatCellVoltage_Cell186 0;
BA_ "GenSigTimeoutTime_AGSM" SG_ 1851 HVBatCellVoltage_Cell186 0;
BA_ "GenSigTimeoutTime_PBWM" SG_ 1851 HVBatCellVoltage_Cell169 0;
BA_ "GenSigTimeoutTime_IDCM" SG_ 1851 HVBatCellVoltage_Cell169 0;
BA_ "GenSigTimeoutTime_EVCU2" SG_ 1851 HVBatCellVoltage_Cell169 0;
BA_ "GenSigTimeoutTime_ECM" SG_ 1851 HVBatCellVoltage_Cell169 0;
BA_ "GenSigTimeoutTime_DMPI" SG_ 1851 HVBatCellVoltage_Cell169 0;
BA_ "GenSigTimeoutTime_BPCM" SG_ 1851 HVBatCellVoltage_Cell169 0;
BA_ "GenSigTimeoutTime_AGSM" SG_ 1851 HVBatCellVoltage_Cell169 0;
BA_ "GenSigTimeoutTime_PBWM" SG_ 1851 HVBatCellVoltage_Cell170 0;
BA_ "GenSigTimeoutTime_IDCM" SG_ 1851 HVBatCellVoltage_Cell170 0;
BA_ "GenSigTimeoutTime_EVCU2" SG_ 1851 HVBatCellVoltage_Cell170 0;
BA_ "GenSigTimeoutTime_ECM" SG_ 1851 HVBatCellVoltage_Cell170 0;
BA_ "GenSigTimeoutTime_DMPI" SG_ 1851 HVBatCellVoltage_Cell170 0;
BA_ "GenSigTimeoutTime_BPCM" SG_ 1851 HVBatCellVoltage_Cell170 0;
BA_ "GenSigTimeoutTime_AGSM" SG_ 1851 HVBatCellVoltage_Cell170 0;
BA_ "GenSigTimeoutTime_PBWM" SG_ 1851 HVBatCellVoltage_Cell171 0;
BA_ "GenSigTimeoutTime_IDCM" SG_ 1851 HVBatCellVoltage_Cell171 0;
BA_ "GenSigTimeoutTime_EVCU2" SG_ 1851 HVBatCellVoltage_Cell171 0;
BA_ "GenSigTimeoutTime_ECM" SG_ 1851 HVBatCellVoltage_Cell171 0;
BA_ "GenSigTimeoutTime_DMPI" SG_ 1851 HVBatCellVoltage_Cell171 0;
BA_ "GenSigTimeoutTime_BPCM" SG_ 1851 HVBatCellVoltage_Cell171 0;
BA_ "GenSigTimeoutTime_AGSM" SG_ 1851 HVBatCellVoltage_Cell171 0;
BA_ "GenSigTimeoutTime_PBWM" SG_ 1851 HVBatCellVoltage_Cell172 0;
BA_ "GenSigTimeoutTime_IDCM" SG_ 1851 HVBatCellVoltage_Cell172 0;
BA_ "GenSigTimeoutTime_EVCU2" SG_ 1851 HVBatCellVoltage_Cell172 0;
BA_ "GenSigTimeoutTime_ECM" SG_ 1851 HVBatCellVoltage_Cell172 0;
BA_ "GenSigTimeoutTime_DMPI" SG_ 1851 HVBatCellVoltage_Cell172 0;
BA_ "GenSigTimeoutTime_BPCM" SG_ 1851 HVBatCellVoltage_Cell172 0;
BA_ "GenSigTimeoutTime_AGSM" SG_ 1851 HVBatCellVoltage_Cell172 0;
BA_ "GenSigTimeoutTime_PBWM" SG_ 1851 HVBatCellVoltage_Cell173 0;
BA_ "GenSigTimeoutTime_IDCM" SG_ 1851 HVBatCellVoltage_Cell173 0;
BA_ "GenSigTimeoutTime_EVCU2" SG_ 1851 HVBatCellVoltage_Cell173 0;
BA_ "GenSigTimeoutTime_ECM" SG_ 1851 HVBatCellVoltage_Cell173 0;
BA_ "GenSigTimeoutTime_DMPI" SG_ 1851 HVBatCellVoltage_Cell173 0;
BA_ "GenSigTimeoutTime_BPCM" SG_ 1851 HVBatCellVoltage_Cell173 0;
BA_ "GenSigTimeoutTime_AGSM" SG_ 1851 HVBatCellVoltage_Cell173 0;
BA_ "GenSigTimeoutTime_PBWM" SG_ 1851 HVBatCellVoltage_Cell174 0;
BA_ "GenSigTimeoutTime_IDCM" SG_ 1851 HVBatCellVoltage_Cell174 0;
BA_ "GenSigTimeoutTime_EVCU2" SG_ 1851 HVBatCellVoltage_Cell174 0;
BA_ "GenSigTimeoutTime_ECM" SG_ 1851 HVBatCellVoltage_Cell174 0;
BA_ "GenSigTimeoutTime_DMPI" SG_ 1851 HVBatCellVoltage_Cell174 0;
BA_ "GenSigTimeoutTime_BPCM" SG_ 1851 HVBatCellVoltage_Cell174 0;
BA_ "GenSigTimeoutTime_AGSM" SG_ 1851 HVBatCellVoltage_Cell174 0;
BA_ "GenSigTimeoutTime_PBWM" SG_ 1851 HVBatCellVoltage_Cell175 0;
BA_ "GenSigTimeoutTime_IDCM" SG_ 1851 HVBatCellVoltage_Cell175 0;
BA_ "GenSigTimeoutTime_EVCU2" SG_ 1851 HVBatCellVoltage_Cell175 0;
BA_ "GenSigTimeoutTime_ECM" SG_ 1851 HVBatCellVoltage_Cell175 0;
BA_ "GenSigTimeoutTime_DMPI" SG_ 1851 HVBatCellVoltage_Cell175 0;
BA_ "GenSigTimeoutTime_BPCM" SG_ 1851 HVBatCellVoltage_Cell175 0;
BA_ "GenSigTimeoutTime_AGSM" SG_ 1851 HVBatCellVoltage_Cell175 0;
BA_ "GenSigTimeoutTime_PBWM" SG_ 1851 HVBatCellVoltage_Cell176 0;
BA_ "GenSigTimeoutTime_IDCM" SG_ 1851 HVBatCellVoltage_Cell176 0;
BA_ "GenSigTimeoutTime_EVCU2" SG_ 1851 HVBatCellVoltage_Cell176 0;
BA_ "GenSigTimeoutTime_ECM" SG_ 1851 HVBatCellVoltage_Cell176 0;
BA_ "GenSigTimeoutTime_DMPI" SG_ 1851 HVBatCellVoltage_Cell176 0;
BA_ "GenSigTimeoutTime_BPCM" SG_ 1851 HVBatCellVoltage_Cell176 0;
BA_ "GenSigTimeoutTime_AGSM" SG_ 1851 HVBatCellVoltage_Cell176 0;
BA_ "GenSigTimeoutTime_PBWM" SG_ 1851 HVBatCellVoltage_Cell177 0;
BA_ "GenSigTimeoutTime_IDCM" SG_ 1851 HVBatCellVoltage_Cell177 0;
BA_ "GenSigTimeoutTime_EVCU2" SG_ 1851 HVBatCellVoltage_Cell177 0;
BA_ "GenSigTimeoutTime_ECM" SG_ 1851 HVBatCellVoltage_Cell177 0;
BA_ "GenSigTimeoutTime_DMPI" SG_ 1851 HVBatCellVoltage_Cell177 0;
BA_ "GenSigTimeoutTime_BPCM" SG_ 1851 HVBatCellVoltage_Cell177 0;
BA_ "GenSigTimeoutTime_AGSM" SG_ 1851 HVBatCellVoltage_Cell177 0;
BA_ "GenSigTimeoutTime_PBWM" SG_ 1851 HVBatCellVoltage_Cell178 0;
BA_ "GenSigTimeoutTime_IDCM" SG_ 1851 HVBatCellVoltage_Cell178 0;
BA_ "GenSigTimeoutTime_EVCU2" SG_ 1851 HVBatCellVoltage_Cell178 0;
BA_ "GenSigTimeoutTime_ECM" SG_ 1851 HVBatCellVoltage_Cell178 0;
BA_ "GenSigTimeoutTime_DMPI" SG_ 1851 HVBatCellVoltage_Cell178 0;
BA_ "GenSigTimeoutTime_BPCM" SG_ 1851 HVBatCellVoltage_Cell178 0;
BA_ "GenSigTimeoutTime_AGSM" SG_ 1851 HVBatCellVoltage_Cell178 0;
BA_ "GenSigTimeoutTime_PBWM" SG_ 1851 HVBatCellVoltage_Cell179 0;
BA_ "GenSigTimeoutTime_IDCM" SG_ 1851 HVBatCellVoltage_Cell179 0;
BA_ "GenSigTimeoutTime_EVCU2" SG_ 1851 HVBatCellVoltage_Cell179 0;
BA_ "GenSigTimeoutTime_ECM" SG_ 1851 HVBatCellVoltage_Cell179 0;
BA_ "GenSigTimeoutTime_DMPI" SG_ 1851 HVBatCellVoltage_Cell179 0;
BA_ "GenSigTimeoutTime_BPCM" SG_ 1851 HVBatCellVoltage_Cell179 0;
BA_ "GenSigTimeoutTime_AGSM" SG_ 1851 HVBatCellVoltage_Cell179 0;
BA_ "GenSigTimeoutTime_PBWM" SG_ 1851 HVBatCellVoltage_Cell180 0;
BA_ "GenSigTimeoutTime_IDCM" SG_ 1851 HVBatCellVoltage_Cell180 0;
BA_ "GenSigTimeoutTime_EVCU2" SG_ 1851 HVBatCellVoltage_Cell180 0;
BA_ "GenSigTimeoutTime_ECM" SG_ 1851 HVBatCellVoltage_Cell180 0;
BA_ "GenSigTimeoutTime_DMPI" SG_ 1851 HVBatCellVoltage_Cell180 0;
BA_ "GenSigTimeoutTime_BPCM" SG_ 1851 HVBatCellVoltage_Cell180 0;
BA_ "GenSigTimeoutTime_AGSM" SG_ 1851 HVBatCellVoltage_Cell180 0;
BA_ "GenSigTimeoutTime_PBWM" SG_ 1851 HVBatCellVoltage_Cell181 0;
BA_ "GenSigTimeoutTime_IDCM" SG_ 1851 HVBatCellVoltage_Cell181 0;
BA_ "GenSigTimeoutTime_EVCU2" SG_ 1851 HVBatCellVoltage_Cell181 0;
BA_ "GenSigTimeoutTime_ECM" SG_ 1851 HVBatCellVoltage_Cell181 0;
BA_ "GenSigTimeoutTime_DMPI" SG_ 1851 HVBatCellVoltage_Cell181 0;
BA_ "GenSigTimeoutTime_BPCM" SG_ 1851 HVBatCellVoltage_Cell181 0;
BA_ "GenSigTimeoutTime_AGSM" SG_ 1851 HVBatCellVoltage_Cell181 0;
BA_ "GenSigTimeoutTime_PBWM" SG_ 1851 HVBatCellVoltage_Cell182 0;
BA_ "GenSigTimeoutTime_IDCM" SG_ 1851 HVBatCellVoltage_Cell182 0;
BA_ "GenSigTimeoutTime_EVCU2" SG_ 1851 HVBatCellVoltage_Cell182 0;
BA_ "GenSigTimeoutTime_ECM" SG_ 1851 HVBatCellVoltage_Cell182 0;
BA_ "GenSigTimeoutTime_DMPI" SG_ 1851 HVBatCellVoltage_Cell182 0;
BA_ "GenSigTimeoutTime_BPCM" SG_ 1851 HVBatCellVoltage_Cell182 0;
BA_ "GenSigTimeoutTime_AGSM" SG_ 1851 HVBatCellVoltage_Cell182 0;
BA_ "GenSigTimeoutTime_PBWM" SG_ 1851 HVBatCellVoltage_Cell183 0;
BA_ "GenSigTimeoutTime_IDCM" SG_ 1851 HVBatCellVoltage_Cell183 0;
BA_ "GenSigTimeoutTime_EVCU2" SG_ 1851 HVBatCellVoltage_Cell183 0;
BA_ "GenSigTimeoutTime_ECM" SG_ 1851 HVBatCellVoltage_Cell183 0;
BA_ "GenSigTimeoutTime_DMPI" SG_ 1851 HVBatCellVoltage_Cell183 0;
BA_ "GenSigTimeoutTime_BPCM" SG_ 1851 HVBatCellVoltage_Cell183 0;
BA_ "GenSigTimeoutTime_AGSM" SG_ 1851 HVBatCellVoltage_Cell183 0;
BA_ "GenSigTimeoutTime_SGW" SG_ 1851 HVBatCellVoltage_Cell184 0;
BA_ "GenSigTimeoutTime_PBWM" SG_ 1851 HVBatCellVoltage_Cell184 0;
BA_ "GenSigTimeoutTime_IDCM" SG_ 1851 HVBatCellVoltage_Cell184 0;
BA_ "GenSigTimeoutTime_EVCU2" SG_ 1851 HVBatCellVoltage_Cell184 0;
BA_ "GenSigTimeoutTime_ECM" SG_ 1851 HVBatCellVoltage_Cell184 0;
BA_ "GenSigTimeoutTime_DMPI" SG_ 1851 HVBatCellVoltage_Cell184 0;
BA_ "GenSigTimeoutTime_BPCM" SG_ 1851 HVBatCellVoltage_Cell184 0;
BA_ "GenSigTimeoutTime_AGSM" SG_ 1851 HVBatCellVoltage_Cell184 0;
BA_ "GenSigTimeoutTime_PBWM" SG_ 1850 HVBatCellVoltage_Cell159 0;
BA_ "GenSigTimeoutTime_IDCM" SG_ 1850 HVBatCellVoltage_Cell159 0;
BA_ "GenSigTimeoutTime_EVCU2" SG_ 1850 HVBatCellVoltage_Cell159 0;
BA_ "GenSigTimeoutTime_PBWM" SG_ 1850 HVBatCellVoltage_Cell160 0;
BA_ "GenSigTimeoutTime_IDCM" SG_ 1850 HVBatCellVoltage_Cell160 0;
BA_ "GenSigTimeoutTime_EVCU2" SG_ 1850 HVBatCellVoltage_Cell160 0;
BA_ "GenSigTimeoutTime_ECM" SG_ 1850 HVBatCellVoltage_Cell160 0;
BA_ "GenSigTimeoutTime_DMPI" SG_ 1850 HVBatCellVoltage_Cell160 0;
BA_ "GenSigTimeoutTime_BPCM" SG_ 1850 HVBatCellVoltage_Cell160 0;
BA_ "GenSigTimeoutTime_AGSM" SG_ 1850 HVBatCellVoltage_Cell160 0;
BA_ "GenSigTimeoutTime_PBWM" SG_ 1850 HVBatCellVoltage_Cell161 0;
BA_ "GenSigTimeoutTime_IDCM" SG_ 1850 HVBatCellVoltage_Cell161 0;
BA_ "GenSigTimeoutTime_EVCU2" SG_ 1850 HVBatCellVoltage_Cell161 0;
BA_ "GenSigTimeoutTime_ECM" SG_ 1850 HVBatCellVoltage_Cell161 0;
BA_ "GenSigTimeoutTime_DMPI" SG_ 1850 HVBatCellVoltage_Cell161 0;
BA_ "GenSigTimeoutTime_BPCM" SG_ 1850 HVBatCellVoltage_Cell161 0;
BA_ "GenSigTimeoutTime_AGSM" SG_ 1850 HVBatCellVoltage_Cell161 0;
BA_ "GenSigTimeoutTime_PBWM" SG_ 1850 HVBatCellVoltage_Cell162 0;
BA_ "GenSigTimeoutTime_IDCM" SG_ 1850 HVBatCellVoltage_Cell162 0;
BA_ "GenSigTimeoutTime_EVCU2" SG_ 1850 HVBatCellVoltage_Cell162 0;
BA_ "GenSigTimeoutTime_ECM" SG_ 1850 HVBatCellVoltage_Cell162 0;
BA_ "GenSigTimeoutTime_DMPI" SG_ 1850 HVBatCellVoltage_Cell162 0;
BA_ "GenSigTimeoutTime_BPCM" SG_ 1850 HVBatCellVoltage_Cell162 0;
BA_ "GenSigTimeoutTime_AGSM" SG_ 1850 HVBatCellVoltage_Cell162 0;
BA_ "GenSigTimeoutTime_ECM" SG_ 1851 HVBatCellVoltage_Cell163 0;
BA_ "GenSigTimeoutTime_DMPI" SG_ 1851 HVBatCellVoltage_Cell163 0;
BA_ "GenSigTimeoutTime_BPCM" SG_ 1851 HVBatCellVoltage_Cell163 0;
BA_ "GenSigTimeoutTime_AGSM" SG_ 1851 HVBatCellVoltage_Cell163 0;
BA_ "GenSigTimeoutTime_PBWM" SG_ 1851 HVBatCellVoltage_Cell163 0;
BA_ "GenSigTimeoutTime_IDCM" SG_ 1851 HVBatCellVoltage_Cell163 0;
BA_ "GenSigTimeoutTime_EVCU2" SG_ 1851 HVBatCellVoltage_Cell163 0;
BA_ "GenSigTimeoutTime_PBWM" SG_ 1851 HVBatCellVoltage_Cell164 0;
BA_ "GenSigTimeoutTime_IDCM" SG_ 1851 HVBatCellVoltage_Cell164 0;
BA_ "GenSigTimeoutTime_EVCU2" SG_ 1851 HVBatCellVoltage_Cell164 0;
BA_ "GenSigTimeoutTime_ECM" SG_ 1851 HVBatCellVoltage_Cell164 0;
BA_ "GenSigTimeoutTime_DMPI" SG_ 1851 HVBatCellVoltage_Cell164 0;
BA_ "GenSigTimeoutTime_BPCM" SG_ 1851 HVBatCellVoltage_Cell164 0;
BA_ "GenSigTimeoutTime_AGSM" SG_ 1851 HVBatCellVoltage_Cell164 0;
BA_ "GenSigTimeoutTime_PBWM" SG_ 1851 HVBatCellVoltage_Cell165 0;
BA_ "GenSigTimeoutTime_IDCM" SG_ 1851 HVBatCellVoltage_Cell165 0;
BA_ "GenSigTimeoutTime_EVCU2" SG_ 1851 HVBatCellVoltage_Cell165 0;
BA_ "GenSigTimeoutTime_ECM" SG_ 1851 HVBatCellVoltage_Cell165 0;
BA_ "GenSigTimeoutTime_DMPI" SG_ 1851 HVBatCellVoltage_Cell165 0;
BA_ "GenSigTimeoutTime_BPCM" SG_ 1851 HVBatCellVoltage_Cell165 0;
BA_ "GenSigTimeoutTime_AGSM" SG_ 1851 HVBatCellVoltage_Cell165 0;
BA_ "GenSigTimeoutTime_PBWM" SG_ 1851 HVBatCellVoltage_Cell166 0;
BA_ "GenSigTimeoutTime_IDCM" SG_ 1851 HVBatCellVoltage_Cell166 0;
BA_ "GenSigTimeoutTime_EVCU2" SG_ 1851 HVBatCellVoltage_Cell166 0;
BA_ "GenSigTimeoutTime_ECM" SG_ 1851 HVBatCellVoltage_Cell166 0;
BA_ "GenSigTimeoutTime_DMPI" SG_ 1851 HVBatCellVoltage_Cell166 0;
BA_ "GenSigTimeoutTime_BPCM" SG_ 1851 HVBatCellVoltage_Cell166 0;
BA_ "GenSigTimeoutTime_AGSM" SG_ 1851 HVBatCellVoltage_Cell166 0;
BA_ "GenSigTimeoutTime_PBWM" SG_ 1851 HVBatCellVoltage_Cell167 0;
BA_ "GenSigTimeoutTime_IDCM" SG_ 1851 HVBatCellVoltage_Cell167 0;
BA_ "GenSigTimeoutTime_EVCU2" SG_ 1851 HVBatCellVoltage_Cell167 0;
BA_ "GenSigTimeoutTime_ECM" SG_ 1851 HVBatCellVoltage_Cell167 0;
BA_ "GenSigTimeoutTime_DMPI" SG_ 1851 HVBatCellVoltage_Cell167 0;
BA_ "GenSigTimeoutTime_BPCM" SG_ 1851 HVBatCellVoltage_Cell167 0;
BA_ "GenSigTimeoutTime_AGSM" SG_ 1851 HVBatCellVoltage_Cell167 0;
BA_ "GenSigTimeoutTime_PBWM" SG_ 1851 HVBatCellVoltage_Cell168 0;
BA_ "GenSigTimeoutTime_IDCM" SG_ 1851 HVBatCellVoltage_Cell168 0;
BA_ "GenSigTimeoutTime_EVCU2" SG_ 1851 HVBatCellVoltage_Cell168 0;
BA_ "GenSigTimeoutTime_ECM" SG_ 1851 HVBatCellVoltage_Cell168 0;
BA_ "GenSigTimeoutTime_DMPI" SG_ 1851 HVBatCellVoltage_Cell168 0;
BA_ "GenSigTimeoutTime_BPCM" SG_ 1851 HVBatCellVoltage_Cell168 0;
BA_ "GenSigTimeoutTime_AGSM" SG_ 1851 HVBatCellVoltage_Cell168 0;
BA_ "GenSigTimeoutTime_ECM" SG_ 1850 HVBatCellVoltage_Cell159 0;
BA_ "GenSigTimeoutTime_DMPI" SG_ 1850 HVBatCellVoltage_Cell159 0;
BA_ "GenSigTimeoutTime_BPCM" SG_ 1850 HVBatCellVoltage_Cell159 0;
BA_ "GenSigTimeoutTime_AGSM" SG_ 1850 HVBatCellVoltage_Cell159 0;
BA_ "GenSigTimeoutTime_PBWM" SG_ 1850 HVBatCellVoltage_Cell157 0;
BA_ "GenSigTimeoutTime_IDCM" SG_ 1850 HVBatCellVoltage_Cell157 0;
BA_ "GenSigTimeoutTime_EVCU2" SG_ 1850 HVBatCellVoltage_Cell157 0;
BA_ "GenSigTimeoutTime_ECM" SG_ 1850 HVBatCellVoltage_Cell157 0;
BA_ "GenSigTimeoutTime_DMPI" SG_ 1850 HVBatCellVoltage_Cell157 0;
BA_ "GenSigTimeoutTime_BPCM" SG_ 1850 HVBatCellVoltage_Cell157 0;
BA_ "GenSigTimeoutTime_AGSM" SG_ 1850 HVBatCellVoltage_Cell157 0;
BA_ "GenSigTimeoutTime_PBWM" SG_ 1850 HVBatCellVoltage_Cell158 0;
BA_ "GenSigTimeoutTime_IDCM" SG_ 1850 HVBatCellVoltage_Cell158 0;
BA_ "GenSigTimeoutTime_EVCU2" SG_ 1850 HVBatCellVoltage_Cell158 0;
BA_ "GenSigTimeoutTime_ECM" SG_ 1850 HVBatCellVoltage_Cell158 0;
BA_ "GenSigTimeoutTime_DMPI" SG_ 1850 HVBatCellVoltage_Cell158 0;
BA_ "GenSigTimeoutTime_BPCM" SG_ 1850 HVBatCellVoltage_Cell158 0;
BA_ "GenSigTimeoutTime_AGSM" SG_ 1850 HVBatCellVoltage_Cell158 0;
BA_ "GenSigTimeoutTime_PBWM" SG_ 1850 HVBatCellVoltage_Cell153 0;
BA_ "GenSigTimeoutTime_IDCM" SG_ 1850 HVBatCellVoltage_Cell153 0;
BA_ "GenSigTimeoutTime_EVCU2" SG_ 1850 HVBatCellVoltage_Cell153 0;
BA_ "GenSigTimeoutTime_ECM" SG_ 1850 HVBatCellVoltage_Cell153 0;
BA_ "GenSigTimeoutTime_DMPI" SG_ 1850 HVBatCellVoltage_Cell153 0;
BA_ "GenSigTimeoutTime_BPCM" SG_ 1850 HVBatCellVoltage_Cell153 0;
BA_ "GenSigTimeoutTime_AGSM" SG_ 1850 HVBatCellVoltage_Cell153 0;
BA_ "GenSigTimeoutTime_PBWM" SG_ 1850 HVBatCellVoltage_Cell154 0;
BA_ "GenSigTimeoutTime_IDCM" SG_ 1850 HVBatCellVoltage_Cell154 0;
BA_ "GenSigTimeoutTime_EVCU2" SG_ 1850 HVBatCellVoltage_Cell154 0;
BA_ "GenSigTimeoutTime_ECM" SG_ 1850 HVBatCellVoltage_Cell154 0;
BA_ "GenSigTimeoutTime_DMPI" SG_ 1850 HVBatCellVoltage_Cell154 0;
BA_ "GenSigTimeoutTime_BPCM" SG_ 1850 HVBatCellVoltage_Cell154 0;
BA_ "GenSigTimeoutTime_AGSM" SG_ 1850 HVBatCellVoltage_Cell154 0;
BA_ "GenSigTimeoutTime_PBWM" SG_ 1850 HVBatCellVoltage_Cell155 0;
BA_ "GenSigTimeoutTime_IDCM" SG_ 1850 HVBatCellVoltage_Cell155 0;
BA_ "GenSigTimeoutTime_EVCU2" SG_ 1850 HVBatCellVoltage_Cell155 0;
BA_ "GenSigTimeoutTime_ECM" SG_ 1850 HVBatCellVoltage_Cell155 0;
BA_ "GenSigTimeoutTime_DMPI" SG_ 1850 HVBatCellVoltage_Cell155 0;
BA_ "GenSigTimeoutTime_BPCM" SG_ 1850 HVBatCellVoltage_Cell155 0;
BA_ "GenSigTimeoutTime_AGSM" SG_ 1850 HVBatCellVoltage_Cell155 0;
BA_ "GenSigTimeoutTime_PBWM" SG_ 1850 HVBatCellVoltage_Cell156 0;
BA_ "GenSigTimeoutTime_IDCM" SG_ 1850 HVBatCellVoltage_Cell156 0;
BA_ "GenSigTimeoutTime_EVCU2" SG_ 1850 HVBatCellVoltage_Cell156 0;
BA_ "GenSigTimeoutTime_ECM" SG_ 1850 HVBatCellVoltage_Cell156 0;
BA_ "GenSigTimeoutTime_DMPI" SG_ 1850 HVBatCellVoltage_Cell156 0;
BA_ "GenSigTimeoutTime_BPCM" SG_ 1850 HVBatCellVoltage_Cell156 0;
BA_ "GenSigTimeoutTime_AGSM" SG_ 1850 HVBatCellVoltage_Cell156 0;
BA_ "GenSigTimeoutTime_PBWM" SG_ 1850 HVBatCellVoltage_Cell137 0;
BA_ "GenSigTimeoutTime_IDCM" SG_ 1850 HVBatCellVoltage_Cell137 0;
BA_ "GenSigTimeoutTime_EVCU2" SG_ 1850 HVBatCellVoltage_Cell137 0;
BA_ "GenSigTimeoutTime_ECM" SG_ 1850 HVBatCellVoltage_Cell137 0;
BA_ "GenSigTimeoutTime_DMPI" SG_ 1850 HVBatCellVoltage_Cell137 0;
BA_ "GenSigTimeoutTime_BPCM" SG_ 1850 HVBatCellVoltage_Cell137 0;
BA_ "GenSigTimeoutTime_AGSM" SG_ 1850 HVBatCellVoltage_Cell137 0;
BA_ "GenSigTimeoutTime_PBWM" SG_ 1850 HVBatCellVoltage_Cell138 0;
BA_ "GenSigTimeoutTime_IDCM" SG_ 1850 HVBatCellVoltage_Cell138 0;
BA_ "GenSigTimeoutTime_EVCU2" SG_ 1850 HVBatCellVoltage_Cell138 0;
BA_ "GenSigTimeoutTime_ECM" SG_ 1850 HVBatCellVoltage_Cell138 0;
BA_ "GenSigTimeoutTime_DMPI" SG_ 1850 HVBatCellVoltage_Cell138 0;
BA_ "GenSigTimeoutTime_BPCM" SG_ 1850 HVBatCellVoltage_Cell138 0;
BA_ "GenSigTimeoutTime_AGSM" SG_ 1850 HVBatCellVoltage_Cell138 0;
BA_ "GenSigTimeoutTime_PBWM" SG_ 1850 HVBatCellVoltage_Cell139 0;
BA_ "GenSigTimeoutTime_IDCM" SG_ 1850 HVBatCellVoltage_Cell139 0;
BA_ "GenSigTimeoutTime_EVCU2" SG_ 1850 HVBatCellVoltage_Cell139 0;
BA_ "GenSigTimeoutTime_ECM" SG_ 1850 HVBatCellVoltage_Cell139 0;
BA_ "GenSigTimeoutTime_DMPI" SG_ 1850 HVBatCellVoltage_Cell139 0;
BA_ "GenSigTimeoutTime_BPCM" SG_ 1850 HVBatCellVoltage_Cell139 0;
BA_ "GenSigTimeoutTime_AGSM" SG_ 1850 HVBatCellVoltage_Cell139 0;
BA_ "GenSigTimeoutTime_PBWM" SG_ 1850 HVBatCellVoltage_Cell140 0;
BA_ "GenSigTimeoutTime_IDCM" SG_ 1850 HVBatCellVoltage_Cell140 0;
BA_ "GenSigTimeoutTime_EVCU2" SG_ 1850 HVBatCellVoltage_Cell140 0;
BA_ "GenSigTimeoutTime_ECM" SG_ 1850 HVBatCellVoltage_Cell140 0;
BA_ "GenSigTimeoutTime_DMPI" SG_ 1850 HVBatCellVoltage_Cell140 0;
BA_ "GenSigTimeoutTime_BPCM" SG_ 1850 HVBatCellVoltage_Cell140 0;
BA_ "GenSigTimeoutTime_AGSM" SG_ 1850 HVBatCellVoltage_Cell140 0;
BA_ "GenSigTimeoutTime_PBWM" SG_ 1850 HVBatCellVoltage_Cell141 0;
BA_ "GenSigTimeoutTime_IDCM" SG_ 1850 HVBatCellVoltage_Cell141 0;
BA_ "GenSigTimeoutTime_EVCU2" SG_ 1850 HVBatCellVoltage_Cell141 0;
BA_ "GenSigTimeoutTime_ECM" SG_ 1850 HVBatCellVoltage_Cell141 0;
BA_ "GenSigTimeoutTime_DMPI" SG_ 1850 HVBatCellVoltage_Cell141 0;
BA_ "GenSigTimeoutTime_BPCM" SG_ 1850 HVBatCellVoltage_Cell141 0;
BA_ "GenSigTimeoutTime_AGSM" SG_ 1850 HVBatCellVoltage_Cell141 0;
BA_ "GenSigTimeoutTime_PBWM" SG_ 1850 HVBatCellVoltage_Cell142 0;
BA_ "GenSigTimeoutTime_IDCM" SG_ 1850 HVBatCellVoltage_Cell142 0;
BA_ "GenSigTimeoutTime_EVCU2" SG_ 1850 HVBatCellVoltage_Cell142 0;
BA_ "GenSigTimeoutTime_ECM" SG_ 1850 HVBatCellVoltage_Cell142 0;
BA_ "GenSigTimeoutTime_DMPI" SG_ 1850 HVBatCellVoltage_Cell142 0;
BA_ "GenSigTimeoutTime_BPCM" SG_ 1850 HVBatCellVoltage_Cell142 0;
BA_ "GenSigTimeoutTime_AGSM" SG_ 1850 HVBatCellVoltage_Cell142 0;
BA_ "GenSigTimeoutTime_PBWM" SG_ 1850 HVBatCellVoltage_Cell143 0;
BA_ "GenSigTimeoutTime_IDCM" SG_ 1850 HVBatCellVoltage_Cell143 0;
BA_ "GenSigTimeoutTime_EVCU2" SG_ 1850 HVBatCellVoltage_Cell143 0;
BA_ "GenSigTimeoutTime_ECM" SG_ 1850 HVBatCellVoltage_Cell143 0;
BA_ "GenSigTimeoutTime_DMPI" SG_ 1850 HVBatCellVoltage_Cell143 0;
BA_ "GenSigTimeoutTime_BPCM" SG_ 1850 HVBatCellVoltage_Cell143 0;
BA_ "GenSigTimeoutTime_AGSM" SG_ 1850 HVBatCellVoltage_Cell143 0;
BA_ "GenSigTimeoutTime_PBWM" SG_ 1850 HVBatCellVoltage_Cell144 0;
BA_ "GenSigTimeoutTime_IDCM" SG_ 1850 HVBatCellVoltage_Cell144 0;
BA_ "GenSigTimeoutTime_EVCU2" SG_ 1850 HVBatCellVoltage_Cell144 0;
BA_ "GenSigTimeoutTime_ECM" SG_ 1850 HVBatCellVoltage_Cell144 0;
BA_ "GenSigTimeoutTime_DMPI" SG_ 1850 HVBatCellVoltage_Cell144 0;
BA_ "GenSigTimeoutTime_BPCM" SG_ 1850 HVBatCellVoltage_Cell144 0;
BA_ "GenSigTimeoutTime_AGSM" SG_ 1850 HVBatCellVoltage_Cell144 0;
BA_ "GenSigTimeoutTime_PBWM" SG_ 1850 HVBatCellVoltage_Cell145 0;
BA_ "GenSigTimeoutTime_IDCM" SG_ 1850 HVBatCellVoltage_Cell145 0;
BA_ "GenSigTimeoutTime_EVCU2" SG_ 1850 HVBatCellVoltage_Cell145 0;
BA_ "GenSigTimeoutTime_ECM" SG_ 1850 HVBatCellVoltage_Cell145 0;
BA_ "GenSigTimeoutTime_DMPI" SG_ 1850 HVBatCellVoltage_Cell145 0;
BA_ "GenSigTimeoutTime_BPCM" SG_ 1850 HVBatCellVoltage_Cell145 0;
BA_ "GenSigTimeoutTime_AGSM" SG_ 1850 HVBatCellVoltage_Cell145 0;
BA_ "GenSigTimeoutTime_SGW" SG_ 276 MessageCounter_HYBRID_POWERTRAI 0;
BA_ "GenSigTimeoutTime_PBWM" SG_ 276 MessageCounter_HYBRID_POWERTRAI 0;
BA_ "GenSigTimeoutTime_IDCM" SG_ 276 MessageCounter_HYBRID_POWERTRAI 0;
BA_ "GenSigTimeoutTime_EVCU2" SG_ 276 MessageCounter_HYBRID_POWERTRAI 0;
BA_ "GenSigTimeoutTime_DMPI" SG_ 276 MessageCounter_HYBRID_POWERTRAI 0;
BA_ "GenSigTimeoutTime_BPCM" SG_ 276 MessageCounter_HYBRID_POWERTRAI 0;
BA_ "GenSigTimeoutTime_AGSM" SG_ 276 MessageCounter_HYBRID_POWERTRAI 0;
BA_ "SystemSignalLongSymbol" SG_ 276 MessageCounter_HYBRID_POWERTRAI "MessageCounter_HYBRID_POWERTRAIN1";
BA_ "GenSigTimeoutTime_SGW" SG_ 276 Hybrid_Remedial_Stop 0;
BA_ "GenSigTimeoutTime_PBWM" SG_ 276 Hybrid_Remedial_Stop 0;
BA_ "GenSigTimeoutTime_IDCM" SG_ 276 Hybrid_Remedial_Stop 0;
BA_ "GenSigTimeoutTime_SGW" SG_ 276 HybTransSt 0;
BA_ "GenSigTimeoutTime_PBWM" SG_ 276 HybTransSt 0;
BA_ "GenSigTimeoutTime_IDCM" SG_ 276 HybTransSt 0;
BA_ "GenSigTimeoutTime_EVCU2" SG_ 276 HybTransSt 0;
BA_ "GenSigTimeoutTime_DMPI" SG_ 276 HybTransSt 0;
BA_ "GenSigTimeoutTime_BPCM" SG_ 276 HybTransSt 0;
BA_ "GenSigTimeoutTime_AGSM" SG_ 276 HybTransSt 0;
BA_ "GenSigTimeoutTime_SGW" SG_ 276 InputSpdRaw 0;
BA_ "GenSigTimeoutTime_PBWM" SG_ 276 InputSpdRaw 0;
BA_ "GenSigTimeoutTime_IDCM" SG_ 276 InputSpdRaw 0;
BA_ "GenSigTimeoutTime_EVCU2" SG_ 276 InputSpdRaw 0;
BA_ "GenSigTimeoutTime_DMPI" SG_ 276 InputSpdRaw 0;
BA_ "GenSigTimeoutTime_BPCM" SG_ 276 InputSpdRaw 0;
BA_ "GenSigTimeoutTime_AGSM" SG_ 276 InputSpdRaw 0;
BA_ "GenSigTimeoutTime_SGW" SG_ 276 TransInpSpdPrfl 0;
BA_ "GenSigTimeoutTime_PBWM" SG_ 276 TransInpSpdPrfl 0;
BA_ "GenSigTimeoutTime_IDCM" SG_ 276 TransInpSpdPrfl 0;
BA_ "GenSigTimeoutTime_EVCU2" SG_ 276 TransInpSpdPrfl 0;
BA_ "GenSigTimeoutTime_DMPI" SG_ 276 TransInpSpdPrfl 0;
BA_ "GenSigTimeoutTime_BPCM" SG_ 276 TransInpSpdPrfl 0;
BA_ "GenSigTimeoutTime_AGSM" SG_ 276 TransInpSpdPrfl 0;
BA_ "GenSigTimeoutTime_SGW" SG_ 276 PropulsionSystemActive 0;
BA_ "GenSigTimeoutTime_PBWM" SG_ 276 PropulsionSystemActive 0;
BA_ "GenSigTimeoutTime_IDCM" SG_ 276 PropulsionSystemActive 0;
BA_ "GenSigTimeoutTime_EVCU2" SG_ 276 PropulsionSystemActive 0;
BA_ "GenSigTimeoutTime_DMPI" SG_ 276 PropulsionSystemActive 0;
BA_ "GenSigTimeoutTime_BPCM" SG_ 276 PropulsionSystemActive 0;
BA_ "GenSigTimeoutTime_AGSM" SG_ 276 PropulsionSystemActive 0;
BA_ "GenSigTimeoutTime_SGW" SG_ 478 OBC_ControlMethod 0;
BA_ "GenSigTimeoutTime_PBWM" SG_ 478 OBC_ControlMethod 0;
BA_ "GenSigTimeoutTime_EVCU2" SG_ 478 OBC_ControlMethod 0;
BA_ "GenSigTimeoutTime_ECM" SG_ 478 OBC_ControlMethod 0;
BA_ "GenSigTimeoutTime_DMPI" SG_ 478 OBC_ControlMethod 0;
BA_ "GenSigTimeoutTime_BPCM" SG_ 478 OBC_ControlMethod 0;
BA_ "GenSigTimeoutTime_AGSM" SG_ 478 OBC_ControlMethod 0;
BA_ "GenSigTimeoutTime_SGW" SG_ 478 ClearLegislatedDiagInfo 0;
BA_ "GenSigTimeoutTime_PBWM" SG_ 478 ClearLegislatedDiagInfo 0;
BA_ "GenSigTimeoutTime_IDCM" SG_ 478 ClearLegislatedDiagInfo 0;
BA_ "GenSigTimeoutTime_EVCU2" SG_ 478 ClearLegislatedDiagInfo 0;
BA_ "GenSigTimeoutTime_ECM" SG_ 478 ClearLegislatedDiagInfo 0;
BA_ "GenSigTimeoutTime_DMPI" SG_ 478 ClearLegislatedDiagInfo 0;
BA_ "GenSigTimeoutTime_AGSM" SG_ 478 ClearLegislatedDiagInfo 0;
BA_ "GenSigTimeoutTime_SGW" SG_ 478 HVPowertrain_InterlockSts 0;
BA_ "GenSigTimeoutTime_PBWM" SG_ 478 HVPowertrain_InterlockSts 0;
BA_ "GenSigTimeoutTime_IDCM" SG_ 478 HVPowertrain_InterlockSts 0;
BA_ "GenSigTimeoutTime_EVCU2" SG_ 478 HVPowertrain_InterlockSts 0;
BA_ "GenSigTimeoutTime_ECM" SG_ 478 HVPowertrain_InterlockSts 0;
BA_ "GenSigTimeoutTime_DMPI" SG_ 478 HVPowertrain_InterlockSts 0;
BA_ "GenSigTimeoutTime_AGSM" SG_ 478 HVPowertrain_InterlockSts 0;
BA_ "GenSigTimeoutTime_SGW" SG_ 478 J1772_CloseS2 0;
BA_ "GenSigTimeoutTime_PBWM" SG_ 478 J1772_CloseS2 0;
BA_ "GenSigTimeoutTime_EVCU2" SG_ 478 J1772_CloseS2 0;
BA_ "GenSigTimeoutTime_ECM" SG_ 478 J1772_CloseS2 0;
BA_ "GenSigTimeoutTime_DMPI" SG_ 478 J1772_CloseS2 0;
BA_ "GenSigTimeoutTime_BPCM" SG_ 478 J1772_CloseS2 0;
BA_ "GenSigTimeoutTime_AGSM" SG_ 478 J1772_CloseS2 0;
BA_ "GenSigTimeoutTime_SGW" SG_ 478 CRC_HYBRID_CHARGING_COMMAND 0;
BA_ "GenSigTimeoutTime_PBWM" SG_ 478 CRC_HYBRID_CHARGING_COMMAND 0;
BA_ "GenSigTimeoutTime_EVCU2" SG_ 478 CRC_HYBRID_CHARGING_COMMAND 0;
BA_ "GenSigTimeoutTime_ECM" SG_ 478 CRC_HYBRID_CHARGING_COMMAND 0;
BA_ "GenSigTimeoutTime_DMPI" SG_ 478 CRC_HYBRID_CHARGING_COMMAND 0;
BA_ "GenSigTimeoutTime_BPCM" SG_ 478 CRC_HYBRID_CHARGING_COMMAND 0;
BA_ "GenSigTimeoutTime_AGSM" SG_ 478 CRC_HYBRID_CHARGING_COMMAND 0;
BA_ "GenSigTimeoutTime_SGW" SG_ 478 MessageCounter_HYBRID_CHARGING_ 0;
BA_ "GenSigTimeoutTime_PBWM" SG_ 478 MessageCounter_HYBRID_CHARGING_ 0;
BA_ "GenSigTimeoutTime_EVCU2" SG_ 478 MessageCounter_HYBRID_CHARGING_ 0;
BA_ "GenSigTimeoutTime_ECM" SG_ 478 MessageCounter_HYBRID_CHARGING_ 0;
BA_ "GenSigTimeoutTime_DMPI" SG_ 478 MessageCounter_HYBRID_CHARGING_ 0;
BA_ "GenSigTimeoutTime_BPCM" SG_ 478 MessageCounter_HYBRID_CHARGING_ 0;
BA_ "GenSigTimeoutTime_AGSM" SG_ 478 MessageCounter_HYBRID_CHARGING_ 0;
BA_ "SystemSignalLongSymbol" SG_ 478 MessageCounter_HYBRID_CHARGING_ "MessageCounter_HYBRID_CHARGING_COMMAND";
BA_ "GenSigTimeoutTime_SGW" SG_ 478 CurrentRequest 0;
BA_ "GenSigTimeoutTime_PBWM" SG_ 478 CurrentRequest 0;
BA_ "GenSigTimeoutTime_EVCU2" SG_ 478 CurrentRequest 0;
BA_ "GenSigTimeoutTime_ECM" SG_ 478 CurrentRequest 0;
BA_ "GenSigTimeoutTime_DMPI" SG_ 478 CurrentRequest 0;
BA_ "GenSigTimeoutTime_BPCM" SG_ 478 CurrentRequest 0;
BA_ "GenSigTimeoutTime_AGSM" SG_ 478 CurrentRequest 0;
BA_ "GenSigTimeoutTime_SGW" SG_ 478 DC_Curr_Max_Thrsh 0;
BA_ "GenSigTimeoutTime_PBWM" SG_ 478 DC_Curr_Max_Thrsh 0;
BA_ "GenSigTimeoutTime_EVCU2" SG_ 478 DC_Curr_Max_Thrsh 0;
BA_ "GenSigTimeoutTime_ECM" SG_ 478 DC_Curr_Max_Thrsh 0;
BA_ "GenSigTimeoutTime_DMPI" SG_ 478 DC_Curr_Max_Thrsh 0;
BA_ "GenSigTimeoutTime_BPCM" SG_ 478 DC_Curr_Max_Thrsh 0;
BA_ "GenSigTimeoutTime_AGSM" SG_ 478 DC_Curr_Max_Thrsh 0;
BA_ "GenSigStartValue" SG_ 478 DC_Curr_Max_Thrsh 511;
BA_ "GenSigTimeoutTime_SGW" SG_ 478 HV_Volt_Max_Thrsh 0;
BA_ "GenSigTimeoutTime_PBWM" SG_ 478 HV_Volt_Max_Thrsh 0;
BA_ "GenSigTimeoutTime_EVCU2" SG_ 478 HV_Volt_Max_Thrsh 0;
BA_ "GenSigTimeoutTime_ECM" SG_ 478 HV_Volt_Max_Thrsh 0;
BA_ "GenSigTimeoutTime_DMPI" SG_ 478 HV_Volt_Max_Thrsh 0;
BA_ "GenSigTimeoutTime_BPCM" SG_ 478 HV_Volt_Max_Thrsh 0;
BA_ "GenSigTimeoutTime_AGSM" SG_ 478 HV_Volt_Max_Thrsh 0;
BA_ "GenSigTimeoutTime_SGW" SG_ 478 HV_Volt_Min_Thrsh 0;
BA_ "GenSigTimeoutTime_PBWM" SG_ 478 HV_Volt_Min_Thrsh 0;
BA_ "GenSigTimeoutTime_EVCU2" SG_ 478 HV_Volt_Min_Thrsh 0;
BA_ "GenSigTimeoutTime_ECM" SG_ 478 HV_Volt_Min_Thrsh 0;
BA_ "GenSigTimeoutTime_DMPI" SG_ 478 HV_Volt_Min_Thrsh 0;
BA_ "GenSigTimeoutTime_BPCM" SG_ 478 HV_Volt_Min_Thrsh 0;
BA_ "GenSigTimeoutTime_AGSM" SG_ 478 HV_Volt_Min_Thrsh 0;
BA_ "GenSigTimeoutTime_ECM" SG_ 478 OBC_OperativeModeReq 0;
BA_ "GenSigTimeoutTime_DMPI" SG_ 478 OBC_OperativeModeReq 0;
BA_ "GenSigTimeoutTime_BPCM" SG_ 478 OBC_OperativeModeReq 0;
BA_ "GenSigTimeoutTime_AGSM" SG_ 478 OBC_OperativeModeReq 0;
BA_ "GenSigStartValue" SG_ 478 OBC_OperativeModeReq 15;
BA_ "GenSigTimeoutTime_SGW" SG_ 478 AC_Curr_Max_Thrsh 0;
BA_ "GenSigTimeoutTime_PBWM" SG_ 478 AC_Curr_Max_Thrsh 0;
BA_ "GenSigTimeoutTime_EVCU2" SG_ 478 AC_Curr_Max_Thrsh 0;
BA_ "GenSigTimeoutTime_ECM" SG_ 478 AC_Curr_Max_Thrsh 0;
BA_ "GenSigTimeoutTime_DMPI" SG_ 478 AC_Curr_Max_Thrsh 0;
BA_ "GenSigTimeoutTime_BPCM" SG_ 478 AC_Curr_Max_Thrsh 0;
BA_ "GenSigTimeoutTime_AGSM" SG_ 478 AC_Curr_Max_Thrsh 0;
BA_ "GenSigTimeoutTime_SGW" SG_ 478 AC_Curr_Min_Thrsh 0;
BA_ "GenSigTimeoutTime_PBWM" SG_ 478 AC_Curr_Min_Thrsh 0;
BA_ "GenSigTimeoutTime_EVCU2" SG_ 478 AC_Curr_Min_Thrsh 0;
BA_ "GenSigTimeoutTime_ECM" SG_ 478 AC_Curr_Min_Thrsh 0;
BA_ "GenSigTimeoutTime_DMPI" SG_ 478 AC_Curr_Min_Thrsh 0;
BA_ "GenSigTimeoutTime_BPCM" SG_ 478 AC_Curr_Min_Thrsh 0;
BA_ "GenSigTimeoutTime_AGSM" SG_ 478 AC_Curr_Min_Thrsh 0;
BA_ "GenSigTimeoutTime_SGW" SG_ 478 ChargeEnable 0;
BA_ "GenSigTimeoutTime_PBWM" SG_ 478 ChargeEnable 0;
BA_ "GenSigTimeoutTime_EVCU2" SG_ 478 ChargeEnable 0;
BA_ "GenSigTimeoutTime_ECM" SG_ 478 ChargeEnable 0;
BA_ "GenSigTimeoutTime_DMPI" SG_ 478 ChargeEnable 0;
BA_ "GenSigTimeoutTime_BPCM" SG_ 478 ChargeEnable 0;
BA_ "GenSigTimeoutTime_AGSM" SG_ 478 ChargeEnable 0;
BA_ "GenSigTimeoutTime_PBWM" SG_ 1850 HVBatCellVoltage_Cell146 0;
BA_ "GenSigTimeoutTime_IDCM" SG_ 1850 HVBatCellVoltage_Cell146 0;
BA_ "GenSigTimeoutTime_EVCU2" SG_ 1850 HVBatCellVoltage_Cell146 0;
BA_ "GenSigTimeoutTime_ECM" SG_ 1850 HVBatCellVoltage_Cell146 0;
BA_ "GenSigTimeoutTime_DMPI" SG_ 1850 HVBatCellVoltage_Cell146 0;
BA_ "GenSigTimeoutTime_BPCM" SG_ 1850 HVBatCellVoltage_Cell146 0;
BA_ "GenSigTimeoutTime_AGSM" SG_ 1850 HVBatCellVoltage_Cell146 0;
BA_ "GenSigTimeoutTime_PBWM" SG_ 1850 HVBatCellVoltage_Cell147 0;
BA_ "GenSigTimeoutTime_IDCM" SG_ 1850 HVBatCellVoltage_Cell147 0;
BA_ "GenSigTimeoutTime_EVCU2" SG_ 1850 HVBatCellVoltage_Cell147 0;
BA_ "GenSigTimeoutTime_ECM" SG_ 1850 HVBatCellVoltage_Cell147 0;
BA_ "GenSigTimeoutTime_DMPI" SG_ 1850 HVBatCellVoltage_Cell147 0;
BA_ "GenSigTimeoutTime_BPCM" SG_ 1850 HVBatCellVoltage_Cell147 0;
BA_ "GenSigTimeoutTime_AGSM" SG_ 1850 HVBatCellVoltage_Cell147 0;
BA_ "GenSigTimeoutTime_PBWM" SG_ 1850 HVBatCellVoltage_Cell148 0;
BA_ "GenSigTimeoutTime_IDCM" SG_ 1850 HVBatCellVoltage_Cell148 0;
BA_ "GenSigTimeoutTime_EVCU2" SG_ 1850 HVBatCellVoltage_Cell148 0;
BA_ "GenSigTimeoutTime_ECM" SG_ 1850 HVBatCellVoltage_Cell148 0;
BA_ "GenSigTimeoutTime_DMPI" SG_ 1850 HVBatCellVoltage_Cell148 0;
BA_ "GenSigTimeoutTime_BPCM" SG_ 1850 HVBatCellVoltage_Cell148 0;
BA_ "GenSigTimeoutTime_AGSM" SG_ 1850 HVBatCellVoltage_Cell148 0;
BA_ "GenSigTimeoutTime_PBWM" SG_ 1850 HVBatCellVoltage_Cell149 0;
BA_ "GenSigTimeoutTime_IDCM" SG_ 1850 HVBatCellVoltage_Cell149 0;
BA_ "GenSigTimeoutTime_EVCU2" SG_ 1850 HVBatCellVoltage_Cell149 0;
BA_ "GenSigTimeoutTime_ECM" SG_ 1850 HVBatCellVoltage_Cell149 0;
BA_ "GenSigTimeoutTime_DMPI" SG_ 1850 HVBatCellVoltage_Cell149 0;
BA_ "GenSigTimeoutTime_BPCM" SG_ 1850 HVBatCellVoltage_Cell149 0;
BA_ "GenSigTimeoutTime_AGSM" SG_ 1850 HVBatCellVoltage_Cell149 0;
BA_ "GenSigTimeoutTime_PBWM" SG_ 1850 HVBatCellVoltage_Cell150 0;
BA_ "GenSigTimeoutTime_IDCM" SG_ 1850 HVBatCellVoltage_Cell150 0;
BA_ "GenSigTimeoutTime_EVCU2" SG_ 1850 HVBatCellVoltage_Cell150 0;
BA_ "GenSigTimeoutTime_ECM" SG_ 1850 HVBatCellVoltage_Cell150 0;
BA_ "GenSigTimeoutTime_DMPI" SG_ 1850 HVBatCellVoltage_Cell150 0;
BA_ "GenSigTimeoutTime_BPCM" SG_ 1850 HVBatCellVoltage_Cell150 0;
BA_ "GenSigTimeoutTime_AGSM" SG_ 1850 HVBatCellVoltage_Cell150 0;
BA_ "GenSigTimeoutTime_PBWM" SG_ 1850 HVBatCellVoltage_Cell151 0;
BA_ "GenSigTimeoutTime_IDCM" SG_ 1850 HVBatCellVoltage_Cell151 0;
BA_ "GenSigTimeoutTime_EVCU2" SG_ 1850 HVBatCellVoltage_Cell151 0;
BA_ "GenSigTimeoutTime_ECM" SG_ 1850 HVBatCellVoltage_Cell151 0;
BA_ "GenSigTimeoutTime_DMPI" SG_ 1850 HVBatCellVoltage_Cell151 0;
BA_ "GenSigTimeoutTime_BPCM" SG_ 1850 HVBatCellVoltage_Cell151 0;
BA_ "GenSigTimeoutTime_AGSM" SG_ 1850 HVBatCellVoltage_Cell151 0;
BA_ "GenSigTimeoutTime_PBWM" SG_ 1850 HVBatCellVoltage_Cell152 0;
BA_ "GenSigTimeoutTime_IDCM" SG_ 1850 HVBatCellVoltage_Cell152 0;
BA_ "GenSigTimeoutTime_EVCU2" SG_ 1850 HVBatCellVoltage_Cell152 0;
BA_ "GenSigTimeoutTime_ECM" SG_ 1850 HVBatCellVoltage_Cell152 0;
BA_ "GenSigTimeoutTime_DMPI" SG_ 1850 HVBatCellVoltage_Cell152 0;
BA_ "GenSigTimeoutTime_BPCM" SG_ 1850 HVBatCellVoltage_Cell152 0;
BA_ "GenSigTimeoutTime_AGSM" SG_ 1850 HVBatCellVoltage_Cell152 0;
BA_ "GenSigTimeoutTime_PBWM" SG_ 1849 HVBatCellVoltage_Cell130 0;
BA_ "GenSigTimeoutTime_IDCM" SG_ 1849 HVBatCellVoltage_Cell130 0;
BA_ "GenSigTimeoutTime_EVCU2" SG_ 1849 HVBatCellVoltage_Cell130 0;
BA_ "GenSigTimeoutTime_ECM" SG_ 1849 HVBatCellVoltage_Cell130 0;
BA_ "GenSigTimeoutTime_DMPI" SG_ 1849 HVBatCellVoltage_Cell130 0;
BA_ "GenSigTimeoutTime_BPCM" SG_ 1849 HVBatCellVoltage_Cell130 0;
BA_ "GenSigTimeoutTime_AGSM" SG_ 1849 HVBatCellVoltage_Cell130 0;
BA_ "GenSigTimeoutTime_PBWM" SG_ 1849 HVBatCellVoltage_Cell131 0;
BA_ "GenSigTimeoutTime_IDCM" SG_ 1849 HVBatCellVoltage_Cell131 0;
BA_ "GenSigTimeoutTime_EVCU2" SG_ 1849 HVBatCellVoltage_Cell131 0;
BA_ "GenSigTimeoutTime_ECM" SG_ 1849 HVBatCellVoltage_Cell131 0;
BA_ "GenSigTimeoutTime_DMPI" SG_ 1849 HVBatCellVoltage_Cell131 0;
BA_ "GenSigTimeoutTime_BPCM" SG_ 1849 HVBatCellVoltage_Cell131 0;
BA_ "GenSigTimeoutTime_AGSM" SG_ 1849 HVBatCellVoltage_Cell131 0;
BA_ "GenSigTimeoutTime_PBWM" SG_ 1849 HVBatCellVoltage_Cell132 0;
BA_ "GenSigTimeoutTime_IDCM" SG_ 1849 HVBatCellVoltage_Cell132 0;
BA_ "GenSigTimeoutTime_EVCU2" SG_ 1849 HVBatCellVoltage_Cell132 0;
BA_ "GenSigTimeoutTime_ECM" SG_ 1849 HVBatCellVoltage_Cell132 0;
BA_ "GenSigTimeoutTime_DMPI" SG_ 1849 HVBatCellVoltage_Cell132 0;
BA_ "GenSigTimeoutTime_BPCM" SG_ 1849 HVBatCellVoltage_Cell132 0;
BA_ "GenSigTimeoutTime_AGSM" SG_ 1849 HVBatCellVoltage_Cell132 0;
BA_ "GenSigTimeoutTime_PBWM" SG_ 1849 HVBatCellVoltage_Cell133 0;
BA_ "GenSigTimeoutTime_IDCM" SG_ 1849 HVBatCellVoltage_Cell133 0;
BA_ "GenSigTimeoutTime_EVCU2" SG_ 1849 HVBatCellVoltage_Cell133 0;
BA_ "GenSigTimeoutTime_ECM" SG_ 1849 HVBatCellVoltage_Cell133 0;
BA_ "GenSigTimeoutTime_DMPI" SG_ 1849 HVBatCellVoltage_Cell133 0;
BA_ "GenSigTimeoutTime_BPCM" SG_ 1849 HVBatCellVoltage_Cell133 0;
BA_ "GenSigTimeoutTime_AGSM" SG_ 1849 HVBatCellVoltage_Cell133 0;
BA_ "GenSigTimeoutTime_PBWM" SG_ 1849 HVBatCellVoltage_Cell134 0;
BA_ "GenSigTimeoutTime_IDCM" SG_ 1849 HVBatCellVoltage_Cell134 0;
BA_ "GenSigTimeoutTime_EVCU2" SG_ 1849 HVBatCellVoltage_Cell134 0;
BA_ "GenSigTimeoutTime_ECM" SG_ 1849 HVBatCellVoltage_Cell134 0;
BA_ "GenSigTimeoutTime_DMPI" SG_ 1849 HVBatCellVoltage_Cell134 0;
BA_ "GenSigTimeoutTime_BPCM" SG_ 1849 HVBatCellVoltage_Cell134 0;
BA_ "GenSigTimeoutTime_AGSM" SG_ 1849 HVBatCellVoltage_Cell134 0;
BA_ "GenSigTimeoutTime_PBWM" SG_ 1849 HVBatCellVoltage_Cell135 0;
BA_ "GenSigTimeoutTime_IDCM" SG_ 1849 HVBatCellVoltage_Cell135 0;
BA_ "GenSigTimeoutTime_EVCU2" SG_ 1849 HVBatCellVoltage_Cell135 0;
BA_ "GenSigTimeoutTime_ECM" SG_ 1849 HVBatCellVoltage_Cell135 0;
BA_ "GenSigTimeoutTime_DMPI" SG_ 1849 HVBatCellVoltage_Cell135 0;
BA_ "GenSigTimeoutTime_BPCM" SG_ 1849 HVBatCellVoltage_Cell135 0;
BA_ "GenSigTimeoutTime_AGSM" SG_ 1849 HVBatCellVoltage_Cell135 0;
BA_ "GenSigTimeoutTime_PBWM" SG_ 1850 HVBatCellVoltage_Cell136 0;
BA_ "GenSigTimeoutTime_IDCM" SG_ 1850 HVBatCellVoltage_Cell136 0;
BA_ "GenSigTimeoutTime_EVCU2" SG_ 1850 HVBatCellVoltage_Cell136 0;
BA_ "GenSigTimeoutTime_ECM" SG_ 1850 HVBatCellVoltage_Cell136 0;
BA_ "GenSigTimeoutTime_DMPI" SG_ 1850 HVBatCellVoltage_Cell136 0;
BA_ "GenSigTimeoutTime_BPCM" SG_ 1850 HVBatCellVoltage_Cell136 0;
BA_ "GenSigTimeoutTime_AGSM" SG_ 1850 HVBatCellVoltage_Cell136 0;
BA_ "GenSigTimeoutTime_PBWM" SG_ 1849 HVBatCellVoltage_Cell129 0;
BA_ "GenSigTimeoutTime_IDCM" SG_ 1849 HVBatCellVoltage_Cell129 0;
BA_ "GenSigTimeoutTime_EVCU2" SG_ 1849 HVBatCellVoltage_Cell129 0;
BA_ "GenSigTimeoutTime_ECM" SG_ 1849 HVBatCellVoltage_Cell129 0;
BA_ "GenSigTimeoutTime_DMPI" SG_ 1849 HVBatCellVoltage_Cell129 0;
BA_ "GenSigTimeoutTime_BPCM" SG_ 1849 HVBatCellVoltage_Cell129 0;
BA_ "GenSigTimeoutTime_AGSM" SG_ 1849 HVBatCellVoltage_Cell129 0;
BA_ "GenSigTimeoutTime_PBWM" SG_ 1849 HVBatCellVoltage_Cell121 0;
BA_ "GenSigTimeoutTime_IDCM" SG_ 1849 HVBatCellVoltage_Cell121 0;
BA_ "GenSigTimeoutTime_EVCU2" SG_ 1849 HVBatCellVoltage_Cell121 0;
BA_ "GenSigTimeoutTime_ECM" SG_ 1849 HVBatCellVoltage_Cell121 0;
BA_ "GenSigTimeoutTime_DMPI" SG_ 1849 HVBatCellVoltage_Cell121 0;
BA_ "GenSigTimeoutTime_BPCM" SG_ 1849 HVBatCellVoltage_Cell121 0;
BA_ "GenSigTimeoutTime_AGSM" SG_ 1849 HVBatCellVoltage_Cell121 0;
BA_ "GenSigTimeoutTime_PBWM" SG_ 1849 HVBatCellVoltage_Cell122 0;
BA_ "GenSigTimeoutTime_IDCM" SG_ 1849 HVBatCellVoltage_Cell122 0;
BA_ "GenSigTimeoutTime_EVCU2" SG_ 1849 HVBatCellVoltage_Cell122 0;
BA_ "GenSigTimeoutTime_ECM" SG_ 1849 HVBatCellVoltage_Cell122 0;
BA_ "GenSigTimeoutTime_DMPI" SG_ 1849 HVBatCellVoltage_Cell122 0;
BA_ "GenSigTimeoutTime_BPCM" SG_ 1849 HVBatCellVoltage_Cell122 0;
BA_ "GenSigTimeoutTime_AGSM" SG_ 1849 HVBatCellVoltage_Cell122 0;
BA_ "GenSigTimeoutTime_PBWM" SG_ 1849 HVBatCellVoltage_Cell123 0;
BA_ "GenSigTimeoutTime_IDCM" SG_ 1849 HVBatCellVoltage_Cell123 0;
BA_ "GenSigTimeoutTime_EVCU2" SG_ 1849 HVBatCellVoltage_Cell123 0;
BA_ "GenSigTimeoutTime_ECM" SG_ 1849 HVBatCellVoltage_Cell123 0;
BA_ "GenSigTimeoutTime_DMPI" SG_ 1849 HVBatCellVoltage_Cell123 0;
BA_ "GenSigTimeoutTime_BPCM" SG_ 1849 HVBatCellVoltage_Cell123 0;
BA_ "GenSigTimeoutTime_AGSM" SG_ 1849 HVBatCellVoltage_Cell123 0;
BA_ "GenSigTimeoutTime_PBWM" SG_ 1849 HVBatCellVoltage_Cell124 0;
BA_ "GenSigTimeoutTime_IDCM" SG_ 1849 HVBatCellVoltage_Cell124 0;
BA_ "GenSigTimeoutTime_EVCU2" SG_ 1849 HVBatCellVoltage_Cell124 0;
BA_ "GenSigTimeoutTime_ECM" SG_ 1849 HVBatCellVoltage_Cell124 0;
BA_ "GenSigTimeoutTime_DMPI" SG_ 1849 HVBatCellVoltage_Cell124 0;
BA_ "GenSigTimeoutTime_BPCM" SG_ 1849 HVBatCellVoltage_Cell124 0;
BA_ "GenSigTimeoutTime_AGSM" SG_ 1849 HVBatCellVoltage_Cell124 0;
BA_ "GenSigTimeoutTime_PBWM" SG_ 1849 HVBatCellVoltage_Cell125 0;
BA_ "GenSigTimeoutTime_IDCM" SG_ 1849 HVBatCellVoltage_Cell125 0;
BA_ "GenSigTimeoutTime_EVCU2" SG_ 1849 HVBatCellVoltage_Cell125 0;
BA_ "GenSigTimeoutTime_ECM" SG_ 1849 HVBatCellVoltage_Cell125 0;
BA_ "GenSigTimeoutTime_DMPI" SG_ 1849 HVBatCellVoltage_Cell125 0;
BA_ "GenSigTimeoutTime_BPCM" SG_ 1849 HVBatCellVoltage_Cell125 0;
BA_ "GenSigTimeoutTime_AGSM" SG_ 1849 HVBatCellVoltage_Cell125 0;
BA_ "GenSigTimeoutTime_PBWM" SG_ 1849 HVBatCellVoltage_Cell126 0;
BA_ "GenSigTimeoutTime_IDCM" SG_ 1849 HVBatCellVoltage_Cell126 0;
BA_ "GenSigTimeoutTime_EVCU2" SG_ 1849 HVBatCellVoltage_Cell126 0;
BA_ "GenSigTimeoutTime_ECM" SG_ 1849 HVBatCellVoltage_Cell126 0;
BA_ "GenSigTimeoutTime_DMPI" SG_ 1849 HVBatCellVoltage_Cell126 0;
BA_ "GenSigTimeoutTime_BPCM" SG_ 1849 HVBatCellVoltage_Cell126 0;
BA_ "GenSigTimeoutTime_AGSM" SG_ 1849 HVBatCellVoltage_Cell126 0;
BA_ "GenSigTimeoutTime_PBWM" SG_ 1849 HVBatCellVoltage_Cell127 0;
BA_ "GenSigTimeoutTime_IDCM" SG_ 1849 HVBatCellVoltage_Cell127 0;
BA_ "GenSigTimeoutTime_EVCU2" SG_ 1849 HVBatCellVoltage_Cell127 0;
BA_ "GenSigTimeoutTime_ECM" SG_ 1849 HVBatCellVoltage_Cell127 0;
BA_ "GenSigTimeoutTime_DMPI" SG_ 1849 HVBatCellVoltage_Cell127 0;
BA_ "GenSigTimeoutTime_BPCM" SG_ 1849 HVBatCellVoltage_Cell127 0;
BA_ "GenSigTimeoutTime_AGSM" SG_ 1849 HVBatCellVoltage_Cell127 0;
BA_ "GenSigTimeoutTime_PBWM" SG_ 1849 HVBatCellVoltage_Cell128 0;
BA_ "GenSigTimeoutTime_IDCM" SG_ 1849 HVBatCellVoltage_Cell128 0;
BA_ "GenSigTimeoutTime_EVCU2" SG_ 1849 HVBatCellVoltage_Cell128 0;
BA_ "GenSigTimeoutTime_ECM" SG_ 1849 HVBatCellVoltage_Cell128 0;
BA_ "GenSigTimeoutTime_DMPI" SG_ 1849 HVBatCellVoltage_Cell128 0;
BA_ "GenSigTimeoutTime_BPCM" SG_ 1849 HVBatCellVoltage_Cell128 0;
BA_ "GenSigTimeoutTime_AGSM" SG_ 1849 HVBatCellVoltage_Cell128 0;
BA_ "GenSigTimeoutTime_PBWM" SG_ 1849 HVBatCellVoltage_Cell109 0;
BA_ "GenSigTimeoutTime_IDCM" SG_ 1849 HVBatCellVoltage_Cell109 0;
BA_ "GenSigTimeoutTime_EVCU2" SG_ 1849 HVBatCellVoltage_Cell109 0;
BA_ "GenSigTimeoutTime_ECM" SG_ 1849 HVBatCellVoltage_Cell109 0;
BA_ "GenSigTimeoutTime_DMPI" SG_ 1849 HVBatCellVoltage_Cell109 0;
BA_ "GenSigTimeoutTime_BPCM" SG_ 1849 HVBatCellVoltage_Cell109 0;
BA_ "GenSigTimeoutTime_AGSM" SG_ 1849 HVBatCellVoltage_Cell109 0;
BA_ "GenSigTimeoutTime_PBWM" SG_ 1849 HVBatCellVoltage_Cell110 0;
BA_ "GenSigTimeoutTime_IDCM" SG_ 1849 HVBatCellVoltage_Cell110 0;
BA_ "GenSigTimeoutTime_EVCU2" SG_ 1849 HVBatCellVoltage_Cell110 0;
BA_ "GenSigTimeoutTime_ECM" SG_ 1849 HVBatCellVoltage_Cell110 0;
BA_ "GenSigTimeoutTime_DMPI" SG_ 1849 HVBatCellVoltage_Cell110 0;
BA_ "GenSigTimeoutTime_BPCM" SG_ 1849 HVBatCellVoltage_Cell110 0;
BA_ "GenSigTimeoutTime_AGSM" SG_ 1849 HVBatCellVoltage_Cell110 0;
BA_ "GenSigTimeoutTime_PBWM" SG_ 1849 HVBatCellVoltage_Cell111 0;
BA_ "GenSigTimeoutTime_IDCM" SG_ 1849 HVBatCellVoltage_Cell111 0;
BA_ "GenSigTimeoutTime_EVCU2" SG_ 1849 HVBatCellVoltage_Cell111 0;
BA_ "GenSigTimeoutTime_ECM" SG_ 1849 HVBatCellVoltage_Cell111 0;
BA_ "GenSigTimeoutTime_DMPI" SG_ 1849 HVBatCellVoltage_Cell111 0;
BA_ "GenSigTimeoutTime_BPCM" SG_ 1849 HVBatCellVoltage_Cell111 0;
BA_ "GenSigTimeoutTime_AGSM" SG_ 1849 HVBatCellVoltage_Cell111 0;
BA_ "GenSigTimeoutTime_PBWM" SG_ 1849 HVBatCellVoltage_Cell112 0;
BA_ "GenSigTimeoutTime_IDCM" SG_ 1849 HVBatCellVoltage_Cell112 0;
BA_ "GenSigTimeoutTime_EVCU2" SG_ 1849 HVBatCellVoltage_Cell112 0;
BA_ "GenSigTimeoutTime_ECM" SG_ 1849 HVBatCellVoltage_Cell112 0;
BA_ "GenSigTimeoutTime_DMPI" SG_ 1849 HVBatCellVoltage_Cell112 0;
BA_ "GenSigTimeoutTime_BPCM" SG_ 1849 HVBatCellVoltage_Cell112 0;
BA_ "GenSigTimeoutTime_AGSM" SG_ 1849 HVBatCellVoltage_Cell112 0;
BA_ "GenSigTimeoutTime_PBWM" SG_ 1849 HVBatCellVoltage_Cell113 0;
BA_ "GenSigTimeoutTime_IDCM" SG_ 1849 HVBatCellVoltage_Cell113 0;
BA_ "GenSigTimeoutTime_EVCU2" SG_ 1849 HVBatCellVoltage_Cell113 0;
BA_ "GenSigTimeoutTime_ECM" SG_ 1849 HVBatCellVoltage_Cell113 0;
BA_ "GenSigTimeoutTime_DMPI" SG_ 1849 HVBatCellVoltage_Cell113 0;
BA_ "GenSigTimeoutTime_BPCM" SG_ 1849 HVBatCellVoltage_Cell113 0;
BA_ "GenSigTimeoutTime_AGSM" SG_ 1849 HVBatCellVoltage_Cell113 0;
BA_ "GenSigTimeoutTime_PBWM" SG_ 1849 HVBatCellVoltage_Cell114 0;
BA_ "GenSigTimeoutTime_IDCM" SG_ 1849 HVBatCellVoltage_Cell114 0;
BA_ "GenSigTimeoutTime_EVCU2" SG_ 1849 HVBatCellVoltage_Cell114 0;
BA_ "GenSigTimeoutTime_ECM" SG_ 1849 HVBatCellVoltage_Cell114 0;
BA_ "GenSigTimeoutTime_DMPI" SG_ 1849 HVBatCellVoltage_Cell114 0;
BA_ "GenSigTimeoutTime_BPCM" SG_ 1849 HVBatCellVoltage_Cell114 0;
BA_ "GenSigTimeoutTime_AGSM" SG_ 1849 HVBatCellVoltage_Cell114 0;
BA_ "GenSigTimeoutTime_PBWM" SG_ 1849 HVBatCellVoltage_Cell115 0;
BA_ "GenSigTimeoutTime_IDCM" SG_ 1849 HVBatCellVoltage_Cell115 0;
BA_ "GenSigTimeoutTime_EVCU2" SG_ 1849 HVBatCellVoltage_Cell115 0;
BA_ "GenSigTimeoutTime_ECM" SG_ 1849 HVBatCellVoltage_Cell115 0;
BA_ "GenSigTimeoutTime_DMPI" SG_ 1849 HVBatCellVoltage_Cell115 0;
BA_ "GenSigTimeoutTime_BPCM" SG_ 1849 HVBatCellVoltage_Cell115 0;
BA_ "GenSigTimeoutTime_AGSM" SG_ 1849 HVBatCellVoltage_Cell115 0;
BA_ "GenSigTimeoutTime_PBWM" SG_ 1849 HVBatCellVoltage_Cell116 0;
BA_ "GenSigTimeoutTime_IDCM" SG_ 1849 HVBatCellVoltage_Cell116 0;
BA_ "GenSigTimeoutTime_EVCU2" SG_ 1849 HVBatCellVoltage_Cell116 0;
BA_ "GenSigTimeoutTime_ECM" SG_ 1849 HVBatCellVoltage_Cell116 0;
BA_ "GenSigTimeoutTime_DMPI" SG_ 1849 HVBatCellVoltage_Cell116 0;
BA_ "GenSigTimeoutTime_BPCM" SG_ 1849 HVBatCellVoltage_Cell116 0;
BA_ "GenSigTimeoutTime_AGSM" SG_ 1849 HVBatCellVoltage_Cell116 0;
BA_ "GenSigTimeoutTime_PBWM" SG_ 1849 HVBatCellVoltage_Cell117 0;
BA_ "GenSigTimeoutTime_IDCM" SG_ 1849 HVBatCellVoltage_Cell117 0;
BA_ "GenSigTimeoutTime_EVCU2" SG_ 1849 HVBatCellVoltage_Cell117 0;
BA_ "GenSigTimeoutTime_ECM" SG_ 1849 HVBatCellVoltage_Cell117 0;
BA_ "GenSigTimeoutTime_DMPI" SG_ 1849 HVBatCellVoltage_Cell117 0;
BA_ "GenSigTimeoutTime_BPCM" SG_ 1849 HVBatCellVoltage_Cell117 0;
BA_ "GenSigTimeoutTime_AGSM" SG_ 1849 HVBatCellVoltage_Cell117 0;
BA_ "GenSigTimeoutTime_PBWM" SG_ 1849 HVBatCellVoltage_Cell118 0;
BA_ "GenSigTimeoutTime_IDCM" SG_ 1849 HVBatCellVoltage_Cell118 0;
BA_ "GenSigTimeoutTime_EVCU2" SG_ 1849 HVBatCellVoltage_Cell118 0;
BA_ "GenSigTimeoutTime_ECM" SG_ 1849 HVBatCellVoltage_Cell118 0;
BA_ "GenSigTimeoutTime_DMPI" SG_ 1849 HVBatCellVoltage_Cell118 0;
BA_ "GenSigTimeoutTime_BPCM" SG_ 1849 HVBatCellVoltage_Cell118 0;
BA_ "GenSigTimeoutTime_AGSM" SG_ 1849 HVBatCellVoltage_Cell118 0;
BA_ "GenSigTimeoutTime_PBWM" SG_ 1849 HVBatCellVoltage_Cell119 0;
BA_ "GenSigTimeoutTime_IDCM" SG_ 1849 HVBatCellVoltage_Cell119 0;
BA_ "GenSigTimeoutTime_EVCU2" SG_ 1849 HVBatCellVoltage_Cell119 0;
BA_ "GenSigTimeoutTime_ECM" SG_ 1849 HVBatCellVoltage_Cell119 0;
BA_ "GenSigTimeoutTime_DMPI" SG_ 1849 HVBatCellVoltage_Cell119 0;
BA_ "GenSigTimeoutTime_BPCM" SG_ 1849 HVBatCellVoltage_Cell119 0;
BA_ "GenSigTimeoutTime_AGSM" SG_ 1849 HVBatCellVoltage_Cell119 0;
BA_ "GenSigTimeoutTime_PBWM" SG_ 1849 HVBatCellVoltage_Cell120 0;
BA_ "GenSigTimeoutTime_IDCM" SG_ 1849 HVBatCellVoltage_Cell120 0;
BA_ "GenSigTimeoutTime_EVCU2" SG_ 1849 HVBatCellVoltage_Cell120 0;
BA_ "GenSigTimeoutTime_ECM" SG_ 1849 HVBatCellVoltage_Cell120 0;
BA_ "GenSigTimeoutTime_DMPI" SG_ 1849 HVBatCellVoltage_Cell120 0;
BA_ "GenSigTimeoutTime_BPCM" SG_ 1849 HVBatCellVoltage_Cell120 0;
BA_ "GenSigTimeoutTime_AGSM" SG_ 1849 HVBatCellVoltage_Cell120 0;
BA_ "GenSigTimeoutTime_SGW" SG_ 1578 OBC_IdleTimeMin 0;
BA_ "GenSigTimeoutTime_PBWM" SG_ 1578 OBC_IdleTimeMin 0;
BA_ "GenSigTimeoutTime_IDCM" SG_ 1578 OBC_IdleTimeMin 0;
BA_ "GenSigTimeoutTime_ECM" SG_ 1578 OBC_IdleTimeMin 0;
BA_ "GenSigTimeoutTime_DMPI" SG_ 1578 OBC_IdleTimeMin 0;
BA_ "GenSigTimeoutTime_BPCM" SG_ 1578 OBC_IdleTimeMin 0;
BA_ "GenSigTimeoutTime_AGSM" SG_ 1578 OBC_IdleTimeMin 0;
BA_ "GenSigTimeoutTime_SGW" SG_ 1578 OBC_IdleTimeSec 0;
BA_ "GenSigTimeoutTime_PBWM" SG_ 1578 OBC_IdleTimeSec 0;
BA_ "GenSigTimeoutTime_IDCM" SG_ 1578 OBC_IdleTimeSec 0;
BA_ "GenSigTimeoutTime_ECM" SG_ 1578 OBC_IdleTimeSec 0;
BA_ "GenSigTimeoutTime_DMPI" SG_ 1578 OBC_IdleTimeSec 0;
BA_ "GenSigTimeoutTime_BPCM" SG_ 1578 OBC_IdleTimeSec 0;
BA_ "GenSigTimeoutTime_AGSM" SG_ 1578 OBC_IdleTimeSec 0;
BA_ "GenSigTimeoutTime_SGW" SG_ 1578 Charging_WHr 0;
BA_ "GenSigTimeoutTime_PBWM" SG_ 1578 Charging_WHr 0;
BA_ "GenSigTimeoutTime_IDCM" SG_ 1578 Charging_WHr 0;
BA_ "GenSigTimeoutTime_ECM" SG_ 1578 Charging_WHr 0;
BA_ "GenSigTimeoutTime_DMPI" SG_ 1578 Charging_WHr 0;
BA_ "GenSigTimeoutTime_BPCM" SG_ 1578 Charging_WHr 0;
BA_ "GenSigTimeoutTime_AGSM" SG_ 1578 Charging_WHr 0;
BA_ "GenSigTimeoutTime_SGW" SG_ 1578 OBC_ChargeTimeMin 0;
BA_ "GenSigTimeoutTime_PBWM" SG_ 1578 OBC_ChargeTimeMin 0;
BA_ "GenSigTimeoutTime_IDCM" SG_ 1578 OBC_ChargeTimeMin 0;
BA_ "GenSigTimeoutTime_ECM" SG_ 1578 OBC_ChargeTimeMin 0;
BA_ "GenSigTimeoutTime_DMPI" SG_ 1578 OBC_ChargeTimeMin 0;
BA_ "GenSigTimeoutTime_BPCM" SG_ 1578 OBC_ChargeTimeMin 0;
BA_ "GenSigTimeoutTime_AGSM" SG_ 1578 OBC_ChargeTimeMin 0;
BA_ "GenSigTimeoutTime_SGW" SG_ 1578 OBC_ChargeTimeSec 0;
BA_ "GenSigTimeoutTime_PBWM" SG_ 1578 OBC_ChargeTimeSec 0;
BA_ "GenSigTimeoutTime_IDCM" SG_ 1578 OBC_ChargeTimeSec 0;
BA_ "GenSigTimeoutTime_ECM" SG_ 1578 OBC_ChargeTimeSec 0;
BA_ "GenSigTimeoutTime_DMPI" SG_ 1578 OBC_ChargeTimeSec 0;
BA_ "GenSigTimeoutTime_BPCM" SG_ 1578 OBC_ChargeTimeSec 0;
BA_ "GenSigTimeoutTime_AGSM" SG_ 1578 OBC_ChargeTimeSec 0;
BA_ "GenSigTimeoutTime_PBWM" SG_ 1845 HVBatSerialLength 0;
BA_ "GenSigTimeoutTime_IDCM" SG_ 1845 HVBatSerialLength 0;
BA_ "GenSigTimeoutTime_EVCU2" SG_ 1845 HVBatSerialLength 0;
BA_ "GenSigTimeoutTime_ECM" SG_ 1845 HVBatSerialLength 0;
BA_ "GenSigTimeoutTime_DMPI" SG_ 1845 HVBatSerialLength 0;
BA_ "GenSigTimeoutTime_BPCM" SG_ 1845 HVBatSerialLength 0;
BA_ "GenSigTimeoutTime_AGSM" SG_ 1845 HVBatSerialLength 0;
BA_ "GenSigTimeoutTime_SGW" SG_ 1578 OBCM_PrechargeSts 0;
BA_ "GenSigTimeoutTime_PBWM" SG_ 1578 OBCM_PrechargeSts 0;
BA_ "GenSigTimeoutTime_IDCM" SG_ 1578 OBCM_PrechargeSts 0;
BA_ "GenSigTimeoutTime_ECM" SG_ 1578 OBCM_PrechargeSts 0;
BA_ "GenSigTimeoutTime_DMPI" SG_ 1578 OBCM_PrechargeSts 0;
BA_ "GenSigTimeoutTime_BPCM" SG_ 1578 OBCM_PrechargeSts 0;
BA_ "GenSigTimeoutTime_AGSM" SG_ 1578 OBCM_PrechargeSts 0;
BA_ "GenSigTimeoutTime_PBWM" SG_ 1845 HVBatSerialNumber 0;
BA_ "GenSigTimeoutTime_IDCM" SG_ 1845 HVBatSerialNumber 0;
BA_ "GenSigTimeoutTime_EVCU2" SG_ 1845 HVBatSerialNumber 0;
BA_ "GenSigTimeoutTime_ECM" SG_ 1845 HVBatSerialNumber 0;
BA_ "GenSigTimeoutTime_DMPI" SG_ 1845 HVBatSerialNumber 0;
BA_ "GenSigTimeoutTime_BPCM" SG_ 1845 HVBatSerialNumber 0;
BA_ "GenSigTimeoutTime_AGSM" SG_ 1845 HVBatSerialNumber 0;
BA_ "GenSigTimeoutTime_SGW" SG_ 1578 ChrgFailSts 0;
BA_ "GenSigTimeoutTime_PBWM" SG_ 1578 ChrgFailSts 0;
BA_ "GenSigTimeoutTime_IDCM" SG_ 1578 ChrgFailSts 0;
BA_ "GenSigTimeoutTime_ECM" SG_ 1578 ChrgFailSts 0;
BA_ "GenSigTimeoutTime_DMPI" SG_ 1578 ChrgFailSts 0;
BA_ "GenSigTimeoutTime_BPCM" SG_ 1578 ChrgFailSts 0;
BA_ "GenSigTimeoutTime_AGSM" SG_ 1578 ChrgFailSts 0;
BA_ "GenSigTimeoutTime_SGW" SG_ 1578 OnboardChargerReady 0;
BA_ "GenSigTimeoutTime_PBWM" SG_ 1578 OnboardChargerReady 0;
BA_ "GenSigTimeoutTime_IDCM" SG_ 1578 OnboardChargerReady 0;
BA_ "GenSigTimeoutTime_ECM" SG_ 1578 OnboardChargerReady 0;
BA_ "GenSigTimeoutTime_DMPI" SG_ 1578 OnboardChargerReady 0;
BA_ "GenSigTimeoutTime_BPCM" SG_ 1578 OnboardChargerReady 0;
BA_ "GenSigTimeoutTime_AGSM" SG_ 1578 OnboardChargerReady 0;
BA_ "GenSigStartValue" SG_ 1578 OnboardChargerReady 1;
BA_ "GenSigTimeoutTime_SGW" SG_ 1578 OBC_FaultReason 0;
BA_ "GenSigTimeoutTime_PBWM" SG_ 1578 OBC_FaultReason 0;
BA_ "GenSigTimeoutTime_IDCM" SG_ 1578 OBC_FaultReason 0;
BA_ "GenSigTimeoutTime_ECM" SG_ 1578 OBC_FaultReason 0;
BA_ "GenSigTimeoutTime_DMPI" SG_ 1578 OBC_FaultReason 0;
BA_ "GenSigTimeoutTime_BPCM" SG_ 1578 OBC_FaultReason 0;
BA_ "GenSigTimeoutTime_AGSM" SG_ 1578 OBC_FaultReason 0;
BA_ "GenSigTimeoutTime_SGW" SG_ 1578 OBC_GenericFailSts 0;
BA_ "GenSigTimeoutTime_PBWM" SG_ 1578 OBC_GenericFailSts 0;
BA_ "GenSigTimeoutTime_IDCM" SG_ 1578 OBC_GenericFailSts 0;
BA_ "GenSigTimeoutTime_ECM" SG_ 1578 OBC_GenericFailSts 0;
BA_ "GenSigTimeoutTime_DMPI" SG_ 1578 OBC_GenericFailSts 0;
BA_ "GenSigTimeoutTime_BPCM" SG_ 1578 OBC_GenericFailSts 0;
BA_ "GenSigTimeoutTime_AGSM" SG_ 1578 OBC_GenericFailSts 0;
BA_ "GenSigTimeoutTime_SGW" SG_ 1578 OBC_WakeReason 0;
BA_ "GenSigTimeoutTime_PBWM" SG_ 1578 OBC_WakeReason 0;
BA_ "GenSigTimeoutTime_IDCM" SG_ 1578 OBC_WakeReason 0;
BA_ "GenSigTimeoutTime_ECM" SG_ 1578 OBC_WakeReason 0;
BA_ "GenSigTimeoutTime_DMPI" SG_ 1578 OBC_WakeReason 0;
BA_ "GenSigTimeoutTime_BPCM" SG_ 1578 OBC_WakeReason 0;
BA_ "GenSigTimeoutTime_AGSM" SG_ 1578 OBC_WakeReason 0;
BA_ "GenSigTimeoutTime_SGW" SG_ 1578 OnboardChargerMode 0;
BA_ "GenSigTimeoutTime_PBWM" SG_ 1578 OnboardChargerMode 0;
BA_ "GenSigTimeoutTime_IDCM" SG_ 1578 OnboardChargerMode 0;
BA_ "GenSigTimeoutTime_ECM" SG_ 1578 OnboardChargerMode 0;
BA_ "GenSigTimeoutTime_DMPI" SG_ 1578 OnboardChargerMode 0;
BA_ "GenSigTimeoutTime_BPCM" SG_ 1578 OnboardChargerMode 0;
BA_ "GenSigTimeoutTime_AGSM" SG_ 1578 OnboardChargerMode 0;
BA_ "GenSigSendType" SG_ 1578 OnboardChargerMode 4;
BA_ "GenSigTimeoutTime_SGW" SG_ 1578 ACplug_PwrMax 0;
BA_ "GenSigTimeoutTime_PBWM" SG_ 1578 ACplug_PwrMax 0;
BA_ "GenSigTimeoutTime_IDCM" SG_ 1578 ACplug_PwrMax 0;
BA_ "GenSigTimeoutTime_ECM" SG_ 1578 ACplug_PwrMax 0;
BA_ "GenSigTimeoutTime_DMPI" SG_ 1578 ACplug_PwrMax 0;
BA_ "GenSigTimeoutTime_BPCM" SG_ 1578 ACplug_PwrMax 0;
BA_ "GenSigTimeoutTime_AGSM" SG_ 1578 ACplug_PwrMax 0;
BA_ "GenSigTimeoutTime_SGW" SG_ 1578 OBC_CaptureEnvironmentData 0;
BA_ "GenSigTimeoutTime_PBWM" SG_ 1578 OBC_CaptureEnvironmentData 0;
BA_ "GenSigTimeoutTime_IDCM" SG_ 1578 OBC_CaptureEnvironmentData 0;
BA_ "GenSigTimeoutTime_ECM" SG_ 1578 OBC_CaptureEnvironmentData 0;
BA_ "GenSigTimeoutTime_DMPI" SG_ 1578 OBC_CaptureEnvironmentData 0;
BA_ "GenSigTimeoutTime_BPCM" SG_ 1578 OBC_CaptureEnvironmentData 0;
BA_ "GenSigTimeoutTime_AGSM" SG_ 1578 OBC_CaptureEnvironmentData 0;
BA_ "GenSigTimeoutTime_SGW" SG_ 1578 OBC_ChargeFailure 0;
BA_ "GenSigTimeoutTime_PBWM" SG_ 1578 OBC_ChargeFailure 0;
BA_ "GenSigTimeoutTime_IDCM" SG_ 1578 OBC_ChargeFailure 0;
BA_ "GenSigTimeoutTime_ECM" SG_ 1578 OBC_ChargeFailure 0;
BA_ "GenSigTimeoutTime_DMPI" SG_ 1578 OBC_ChargeFailure 0;
BA_ "GenSigTimeoutTime_BPCM" SG_ 1578 OBC_ChargeFailure 0;
BA_ "GenSigTimeoutTime_AGSM" SG_ 1578 OBC_ChargeFailure 0;
BA_ "GenSigTimeoutTime_SGW" SG_ 1578 OBC_ChargingFaultSts 0;
BA_ "GenSigTimeoutTime_PBWM" SG_ 1578 OBC_ChargingFaultSts 0;
BA_ "GenSigTimeoutTime_IDCM" SG_ 1578 OBC_ChargingFaultSts 0;
BA_ "GenSigTimeoutTime_ECM" SG_ 1578 OBC_ChargingFaultSts 0;
BA_ "GenSigTimeoutTime_DMPI" SG_ 1578 OBC_ChargingFaultSts 0;
BA_ "GenSigTimeoutTime_BPCM" SG_ 1578 OBC_ChargingFaultSts 0;
BA_ "GenSigTimeoutTime_AGSM" SG_ 1578 OBC_ChargingFaultSts 0;
BA_ "GenSigTimeoutTime_SGW" SG_ 1578 OBC_CurrentFailureSts 0;
BA_ "GenSigTimeoutTime_PBWM" SG_ 1578 OBC_CurrentFailureSts 0;
BA_ "GenSigTimeoutTime_IDCM" SG_ 1578 OBC_CurrentFailureSts 0;
BA_ "GenSigTimeoutTime_ECM" SG_ 1578 OBC_CurrentFailureSts 0;
BA_ "GenSigTimeoutTime_DMPI" SG_ 1578 OBC_CurrentFailureSts 0;
BA_ "GenSigTimeoutTime_BPCM" SG_ 1578 OBC_CurrentFailureSts 0;
BA_ "GenSigTimeoutTime_AGSM" SG_ 1578 OBC_CurrentFailureSts 0;
BA_ "GenSigTimeoutTime_SGW" SG_ 1578 OBC_EVServiceLampFlash 0;
BA_ "GenSigTimeoutTime_PBWM" SG_ 1578 OBC_EVServiceLampFlash 0;
BA_ "GenSigTimeoutTime_IDCM" SG_ 1578 OBC_EVServiceLampFlash 0;
BA_ "GenSigTimeoutTime_ECM" SG_ 1578 OBC_EVServiceLampFlash 0;
BA_ "GenSigTimeoutTime_DMPI" SG_ 1578 OBC_EVServiceLampFlash 0;
BA_ "GenSigTimeoutTime_BPCM" SG_ 1578 OBC_EVServiceLampFlash 0;
BA_ "GenSigTimeoutTime_AGSM" SG_ 1578 OBC_EVServiceLampFlash 0;
BA_ "GenSigTimeoutTime_SGW" SG_ 1578 OBC_EVServiceLampOn 0;
BA_ "GenSigTimeoutTime_PBWM" SG_ 1578 OBC_EVServiceLampOn 0;
BA_ "GenSigTimeoutTime_IDCM" SG_ 1578 OBC_EVServiceLampOn 0;
BA_ "GenSigTimeoutTime_ECM" SG_ 1578 OBC_EVServiceLampOn 0;
BA_ "GenSigTimeoutTime_DMPI" SG_ 1578 OBC_EVServiceLampOn 0;
BA_ "GenSigTimeoutTime_BPCM" SG_ 1578 OBC_EVServiceLampOn 0;
BA_ "GenSigTimeoutTime_AGSM" SG_ 1578 OBC_EVServiceLampOn 0;
BA_ "GenSigTimeoutTime_SGW" SG_ 1578 OBC_Pilot 0;
BA_ "GenSigTimeoutTime_PBWM" SG_ 1578 OBC_Pilot 0;
BA_ "GenSigTimeoutTime_IDCM" SG_ 1578 OBC_Pilot 0;
BA_ "GenSigTimeoutTime_ECM" SG_ 1578 OBC_Pilot 0;
BA_ "GenSigTimeoutTime_DMPI" SG_ 1578 OBC_Pilot 0;
BA_ "GenSigTimeoutTime_BPCM" SG_ 1578 OBC_Pilot 0;
BA_ "GenSigTimeoutTime_AGSM" SG_ 1578 OBC_Pilot 0;
BA_ "GenSigTimeoutTime_SGW" SG_ 1578 OBC_Prox 0;
BA_ "GenSigTimeoutTime_PBWM" SG_ 1578 OBC_Prox 0;
BA_ "GenSigTimeoutTime_IDCM" SG_ 1578 OBC_Prox 0;
BA_ "GenSigTimeoutTime_ECM" SG_ 1578 OBC_Prox 0;
BA_ "GenSigTimeoutTime_DMPI" SG_ 1578 OBC_Prox 0;
BA_ "GenSigTimeoutTime_BPCM" SG_ 1578 OBC_Prox 0;
BA_ "GenSigTimeoutTime_AGSM" SG_ 1578 OBC_Prox 0;
BA_ "GenSigTimeoutTime_SGW" SG_ 1460 FOTA_Status 0;
BA_ "GenSigTimeoutTime_PBWM" SG_ 1460 FOTA_Status 0;
BA_ "GenSigTimeoutTime_IDCM" SG_ 1460 FOTA_Status 0;
BA_ "GenSigTimeoutTime_ECM" SG_ 1460 FOTA_Status 0;
BA_ "GenSigTimeoutTime_DMPI" SG_ 1460 FOTA_Status 0;
BA_ "GenSigTimeoutTime_AGSM" SG_ 1460 FOTA_Status 0;
BA_ "GenSigSendType" SG_ 1460 FOTA_Status 3;
BA_ "GenSigTimeoutTime_SGW" SG_ 271 PT_CrnkAct 0;
BA_ "GenSigTimeoutTime_PBWM" SG_ 271 PT_CrnkAct 0;
BA_ "GenSigTimeoutTime_IDCM" SG_ 271 PT_CrnkAct 0;
BA_ "GenSigTimeoutTime_ECM" SG_ 271 PT_CrnkAct 0;
BA_ "GenSigTimeoutTime_DMPI" SG_ 271 PT_CrnkAct 0;
BA_ "GenSigTimeoutTime_BPCM" SG_ 271 PT_CrnkAct 0;
BA_ "GenSigTimeoutTime_AGSM" SG_ 271 PT_CrnkAct 0;
BA_ "GenSigTimeoutTime_SGW" SG_ 271 Sum_FW_ID_Fst 0;
BA_ "GenSigTimeoutTime_PBWM" SG_ 271 Sum_FW_ID_Fst 0;
BA_ "GenSigTimeoutTime_IDCM" SG_ 271 Sum_FW_ID_Fst 0;
BA_ "GenSigTimeoutTime_ECM" SG_ 271 Sum_FW_ID_Fst 0;
BA_ "GenSigTimeoutTime_DMPI" SG_ 271 Sum_FW_ID_Fst 0;
BA_ "GenSigTimeoutTime_BPCM" SG_ 271 Sum_FW_ID_Fst 0;
BA_ "GenSigTimeoutTime_AGSM" SG_ 271 Sum_FW_ID_Fst 0;
BA_ "GenSigStartValue" SG_ 271 Sum_FW_ID_Fst 1;
BA_ "GenSigTimeoutTime_SGW" SG_ 271 Sum_FW_ID_Slw 0;
BA_ "GenSigTimeoutTime_PBWM" SG_ 271 Sum_FW_ID_Slw 0;
BA_ "GenSigTimeoutTime_IDCM" SG_ 271 Sum_FW_ID_Slw 0;
BA_ "GenSigTimeoutTime_ECM" SG_ 271 Sum_FW_ID_Slw 0;
BA_ "GenSigTimeoutTime_DMPI" SG_ 271 Sum_FW_ID_Slw 0;
BA_ "GenSigTimeoutTime_BPCM" SG_ 271 Sum_FW_ID_Slw 0;
BA_ "GenSigTimeoutTime_AGSM" SG_ 271 Sum_FW_ID_Slw 0;
BA_ "GenSigStartValue" SG_ 271 Sum_FW_ID_Slw 1;
BA_ "GenSigTimeoutTime_SGW" SG_ 271 TLC_LRN_Rq 0;
BA_ "GenSigTimeoutTime_PBWM" SG_ 271 TLC_LRN_Rq 0;
BA_ "GenSigTimeoutTime_IDCM" SG_ 271 TLC_LRN_Rq 0;
BA_ "GenSigTimeoutTime_ECM" SG_ 271 TLC_LRN_Rq 0;
BA_ "GenSigTimeoutTime_DMPI" SG_ 271 TLC_LRN_Rq 0;
BA_ "GenSigTimeoutTime_BPCM" SG_ 271 TLC_LRN_Rq 0;
BA_ "GenSigTimeoutTime_AGSM" SG_ 271 TLC_LRN_Rq 0;
BA_ "GenSigTimeoutTime_SGW" SG_ 271 MaxPrdtdEngTorqCapV 0;
BA_ "GenSigTimeoutTime_PBWM" SG_ 271 MaxPrdtdEngTorqCapV 0;
BA_ "GenSigTimeoutTime_IDCM" SG_ 271 MaxPrdtdEngTorqCapV 0;
BA_ "GenSigTimeoutTime_ECM" SG_ 271 MaxPrdtdEngTorqCapV 0;
BA_ "GenSigTimeoutTime_DMPI" SG_ 271 MaxPrdtdEngTorqCapV 0;
BA_ "GenSigTimeoutTime_BPCM" SG_ 271 MaxPrdtdEngTorqCapV 0;
BA_ "GenSigTimeoutTime_AGSM" SG_ 271 MaxPrdtdEngTorqCapV 0;
BA_ "GenSigTimeoutTime_SGW" SG_ 271 MessageCounter_ENGINE_HYBD_FD_1 0;
BA_ "GenSigTimeoutTime_PBWM" SG_ 271 MessageCounter_ENGINE_HYBD_FD_1 0;
BA_ "GenSigTimeoutTime_IDCM" SG_ 271 MessageCounter_ENGINE_HYBD_FD_1 0;
BA_ "GenSigTimeoutTime_ECM" SG_ 271 MessageCounter_ENGINE_HYBD_FD_1 0;
BA_ "GenSigTimeoutTime_DMPI" SG_ 271 MessageCounter_ENGINE_HYBD_FD_1 0;
BA_ "GenSigTimeoutTime_BPCM" SG_ 271 MessageCounter_ENGINE_HYBD_FD_1 0;
BA_ "GenSigTimeoutTime_AGSM" SG_ 271 MessageCounter_ENGINE_HYBD_FD_1 0;
BA_ "GenSigTimeoutTime_SGW" SG_ 271 MinAirFlowMinSparkTorqCap 0;
BA_ "GenSigTimeoutTime_PBWM" SG_ 271 MinAirFlowMinSparkTorqCap 0;
BA_ "GenSigTimeoutTime_IDCM" SG_ 271 MinAirFlowMinSparkTorqCap 0;
BA_ "GenSigTimeoutTime_ECM" SG_ 271 MinAirFlowMinSparkTorqCap 0;
BA_ "GenSigTimeoutTime_DMPI" SG_ 271 MinAirFlowMinSparkTorqCap 0;
BA_ "GenSigTimeoutTime_BPCM" SG_ 271 MinAirFlowMinSparkTorqCap 0;
BA_ "GenSigTimeoutTime_AGSM" SG_ 271 MinAirFlowMinSparkTorqCap 0;
BA_ "GenSigStartValue" SG_ 271 MinAirFlowMinSparkTorqCap 938;
BA_ "GenSigTimeoutTime_SGW" SG_ 271 MinAirFlowMinSparkTorqCapV 0;
BA_ "GenSigTimeoutTime_PBWM" SG_ 271 MinAirFlowMinSparkTorqCapV 0;
BA_ "GenSigTimeoutTime_IDCM" SG_ 271 MinAirFlowMinSparkTorqCapV 0;
BA_ "GenSigTimeoutTime_ECM" SG_ 271 MinAirFlowMinSparkTorqCapV 0;
BA_ "GenSigTimeoutTime_DMPI" SG_ 271 MinAirFlowMinSparkTorqCapV 0;
BA_ "GenSigTimeoutTime_BPCM" SG_ 271 MinAirFlowMinSparkTorqCapV 0;
BA_ "GenSigTimeoutTime_AGSM" SG_ 271 MinAirFlowMinSparkTorqCapV 0;
BA_ "GenSigTimeoutTime_SGW" SG_ 271 MinEngTorqCap 0;
BA_ "GenSigTimeoutTime_PBWM" SG_ 271 MinEngTorqCap 0;
BA_ "GenSigTimeoutTime_IDCM" SG_ 271 MinEngTorqCap 0;
BA_ "GenSigTimeoutTime_ECM" SG_ 271 MinEngTorqCap 0;
BA_ "GenSigTimeoutTime_DMPI" SG_ 271 MinEngTorqCap 0;
BA_ "GenSigTimeoutTime_BPCM" SG_ 271 MinEngTorqCap 0;
BA_ "GenSigTimeoutTime_AGSM" SG_ 271 MinEngTorqCap 0;
BA_ "GenSigStartValue" SG_ 271 MinEngTorqCap 938;
BA_ "GenSigTimeoutTime_SGW" SG_ 271 MinEngTorqCapV 0;
BA_ "GenSigTimeoutTime_PBWM" SG_ 271 MinEngTorqCapV 0;
BA_ "GenSigTimeoutTime_IDCM" SG_ 271 MinEngTorqCapV 0;
BA_ "GenSigTimeoutTime_ECM" SG_ 271 MinEngTorqCapV 0;
BA_ "GenSigTimeoutTime_DMPI" SG_ 271 MinEngTorqCapV 0;
BA_ "GenSigTimeoutTime_BPCM" SG_ 271 MinEngTorqCapV 0;
BA_ "GenSigTimeoutTime_AGSM" SG_ 271 MinEngTorqCapV 0;
BA_ "GenSigTimeoutTime_SGW" SG_ 271 MinImmedEngTorqCap 0;
BA_ "GenSigTimeoutTime_PBWM" SG_ 271 MinImmedEngTorqCap 0;
BA_ "GenSigTimeoutTime_IDCM" SG_ 271 MinImmedEngTorqCap 0;
BA_ "GenSigTimeoutTime_ECM" SG_ 271 MinImmedEngTorqCap 0;
BA_ "GenSigTimeoutTime_DMPI" SG_ 271 MinImmedEngTorqCap 0;
BA_ "GenSigTimeoutTime_BPCM" SG_ 271 MinImmedEngTorqCap 0;
BA_ "GenSigTimeoutTime_AGSM" SG_ 271 MinImmedEngTorqCap 0;
BA_ "GenSigStartValue" SG_ 271 MinImmedEngTorqCap 938;
BA_ "GenSigTimeoutTime_SGW" SG_ 271 MinImmedEngTorqCapV 0;
BA_ "GenSigTimeoutTime_PBWM" SG_ 271 MinImmedEngTorqCapV 0;
BA_ "GenSigTimeoutTime_IDCM" SG_ 271 MinImmedEngTorqCapV 0;
BA_ "GenSigTimeoutTime_ECM" SG_ 271 MinImmedEngTorqCapV 0;
BA_ "GenSigTimeoutTime_DMPI" SG_ 271 MinImmedEngTorqCapV 0;
BA_ "GenSigTimeoutTime_BPCM" SG_ 271 MinImmedEngTorqCapV 0;
BA_ "GenSigTimeoutTime_AGSM" SG_ 271 MinImmedEngTorqCapV 0;
BA_ "GenSigTimeoutTime_SGW" SG_ 271 MinPrdtdEngRunTorqCap 0;
BA_ "GenSigTimeoutTime_PBWM" SG_ 271 MinPrdtdEngRunTorqCap 0;
BA_ "GenSigTimeoutTime_IDCM" SG_ 271 MinPrdtdEngRunTorqCap 0;
BA_ "GenSigTimeoutTime_ECM" SG_ 271 MinPrdtdEngRunTorqCap 0;
BA_ "GenSigTimeoutTime_DMPI" SG_ 271 MinPrdtdEngRunTorqCap 0;
BA_ "GenSigTimeoutTime_BPCM" SG_ 271 MinPrdtdEngRunTorqCap 0;
BA_ "GenSigTimeoutTime_AGSM" SG_ 271 MinPrdtdEngRunTorqCap 0;
BA_ "GenSigStartValue" SG_ 271 MinPrdtdEngRunTorqCap 938;
BA_ "GenSigTimeoutTime_SGW" SG_ 271 MinPrdtdEngRunTorqCapV 0;
BA_ "GenSigTimeoutTime_PBWM" SG_ 271 MinPrdtdEngRunTorqCapV 0;
BA_ "GenSigTimeoutTime_IDCM" SG_ 271 MinPrdtdEngRunTorqCapV 0;
BA_ "GenSigTimeoutTime_ECM" SG_ 271 MinPrdtdEngRunTorqCapV 0;
BA_ "GenSigTimeoutTime_DMPI" SG_ 271 MinPrdtdEngRunTorqCapV 0;
BA_ "GenSigTimeoutTime_BPCM" SG_ 271 MinPrdtdEngRunTorqCapV 0;
BA_ "GenSigTimeoutTime_AGSM" SG_ 271 MinPrdtdEngRunTorqCapV 0;
BA_ "GenSigTimeoutTime_SGW" SG_ 271 RedSpkAuthorityAvbl 0;
BA_ "GenSigTimeoutTime_PBWM" SG_ 271 RedSpkAuthorityAvbl 0;
BA_ "GenSigTimeoutTime_IDCM" SG_ 271 RedSpkAuthorityAvbl 0;
BA_ "GenSigTimeoutTime_ECM" SG_ 271 RedSpkAuthorityAvbl 0;
BA_ "GenSigTimeoutTime_DMPI" SG_ 271 RedSpkAuthorityAvbl 0;
BA_ "GenSigTimeoutTime_BPCM" SG_ 271 RedSpkAuthorityAvbl 0;
BA_ "GenSigTimeoutTime_AGSM" SG_ 271 RedSpkAuthorityAvbl 0;
BA_ "GenSigTimeoutTime_SGW" SG_ 271 PnLimitMaxEngTrqCapV 0;
BA_ "GenSigTimeoutTime_PBWM" SG_ 271 PnLimitMaxEngTrqCapV 0;
BA_ "GenSigTimeoutTime_IDCM" SG_ 271 PnLimitMaxEngTrqCapV 0;
BA_ "GenSigTimeoutTime_ECM" SG_ 271 PnLimitMaxEngTrqCapV 0;
BA_ "GenSigTimeoutTime_DMPI" SG_ 271 PnLimitMaxEngTrqCapV 0;
BA_ "GenSigTimeoutTime_BPCM" SG_ 271 PnLimitMaxEngTrqCapV 0;
BA_ "GenSigTimeoutTime_AGSM" SG_ 271 PnLimitMaxEngTrqCapV 0;
BA_ "GenSigTimeoutTime_SGW" SG_ 271 PnLimitActvFlg 0;
BA_ "GenSigTimeoutTime_PBWM" SG_ 271 PnLimitActvFlg 0;
BA_ "GenSigTimeoutTime_IDCM" SG_ 271 PnLimitActvFlg 0;
BA_ "GenSigTimeoutTime_ECM" SG_ 271 PnLimitActvFlg 0;
BA_ "GenSigTimeoutTime_DMPI" SG_ 271 PnLimitActvFlg 0;
BA_ "GenSigTimeoutTime_BPCM" SG_ 271 PnLimitActvFlg 0;
BA_ "GenSigTimeoutTime_AGSM" SG_ 271 PnLimitActvFlg 0;
BA_ "GenSigTimeoutTime_SGW" SG_ 271 PnLimitMaxEngTrqCap 0;
BA_ "GenSigTimeoutTime_PBWM" SG_ 271 PnLimitMaxEngTrqCap 0;
BA_ "GenSigTimeoutTime_IDCM" SG_ 271 PnLimitMaxEngTrqCap 0;
BA_ "GenSigTimeoutTime_ECM" SG_ 271 PnLimitMaxEngTrqCap 0;
BA_ "GenSigTimeoutTime_DMPI" SG_ 271 PnLimitMaxEngTrqCap 0;
BA_ "GenSigTimeoutTime_BPCM" SG_ 271 PnLimitMaxEngTrqCap 0;
BA_ "GenSigTimeoutTime_AGSM" SG_ 271 PnLimitMaxEngTrqCap 0;
BA_ "GenSigTimeoutTime_SGW" SG_ 271 EngMinSparkNomCurrAirTorqCap 0;
BA_ "GenSigTimeoutTime_PBWM" SG_ 271 EngMinSparkNomCurrAirTorqCap 0;
BA_ "GenSigTimeoutTime_IDCM" SG_ 271 EngMinSparkNomCurrAirTorqCap 0;
BA_ "GenSigTimeoutTime_ECM" SG_ 271 EngMinSparkNomCurrAirTorqCap 0;
BA_ "GenSigTimeoutTime_DMPI" SG_ 271 EngMinSparkNomCurrAirTorqCap 0;
BA_ "GenSigTimeoutTime_BPCM" SG_ 271 EngMinSparkNomCurrAirTorqCap 0;
BA_ "GenSigTimeoutTime_AGSM" SG_ 271 EngMinSparkNomCurrAirTorqCap 0;
BA_ "GenSigTimeoutTime_SGW" SG_ 271 MaxOffEngTorqCap 0;
BA_ "GenSigTimeoutTime_PBWM" SG_ 271 MaxOffEngTorqCap 0;
BA_ "GenSigTimeoutTime_IDCM" SG_ 271 MaxOffEngTorqCap 0;
BA_ "GenSigTimeoutTime_ECM" SG_ 271 MaxOffEngTorqCap 0;
BA_ "GenSigTimeoutTime_DMPI" SG_ 271 MaxOffEngTorqCap 0;
BA_ "GenSigTimeoutTime_BPCM" SG_ 271 MaxOffEngTorqCap 0;
BA_ "GenSigTimeoutTime_AGSM" SG_ 271 MaxOffEngTorqCap 0;
BA_ "GenSigStartValue" SG_ 271 MaxOffEngTorqCap 938;
BA_ "GenSigTimeoutTime_SGW" SG_ 271 MaxPrdtdEngTorqCap 0;
BA_ "GenSigTimeoutTime_PBWM" SG_ 271 MaxPrdtdEngTorqCap 0;
BA_ "GenSigTimeoutTime_IDCM" SG_ 271 MaxPrdtdEngTorqCap 0;
BA_ "GenSigTimeoutTime_ECM" SG_ 271 MaxPrdtdEngTorqCap 0;
BA_ "GenSigTimeoutTime_DMPI" SG_ 271 MaxPrdtdEngTorqCap 0;
BA_ "GenSigTimeoutTime_BPCM" SG_ 271 MaxPrdtdEngTorqCap 0;
BA_ "GenSigTimeoutTime_AGSM" SG_ 271 MaxPrdtdEngTorqCap 0;
BA_ "GenSigStartValue" SG_ 271 MaxPrdtdEngTorqCap 938;
BA_ "GenSigTimeoutTime_SGW" SG_ 271 EngTrqReserveReq 0;
BA_ "GenSigTimeoutTime_PBWM" SG_ 271 EngTrqReserveReq 0;
BA_ "GenSigTimeoutTime_IDCM" SG_ 271 EngTrqReserveReq 0;
BA_ "GenSigTimeoutTime_ECM" SG_ 271 EngTrqReserveReq 0;
BA_ "GenSigTimeoutTime_DMPI" SG_ 271 EngTrqReserveReq 0;
BA_ "GenSigTimeoutTime_BPCM" SG_ 271 EngTrqReserveReq 0;
BA_ "GenSigTimeoutTime_AGSM" SG_ 271 EngTrqReserveReq 0;
BA_ "GenSigTimeoutTime_SGW" SG_ 271 ETRQ_Mode 0;
BA_ "GenSigTimeoutTime_PBWM" SG_ 271 ETRQ_Mode 0;
BA_ "GenSigTimeoutTime_IDCM" SG_ 271 ETRQ_Mode 0;
BA_ "GenSigTimeoutTime_ECM" SG_ 271 ETRQ_Mode 0;
BA_ "GenSigTimeoutTime_DMPI" SG_ 271 ETRQ_Mode 0;
BA_ "GenSigTimeoutTime_BPCM" SG_ 271 ETRQ_Mode 0;
BA_ "GenSigTimeoutTime_AGSM" SG_ 271 ETRQ_Mode 0;
BA_ "GenSigTimeoutTime_SGW" SG_ 271 Feedback_HCP 0;
BA_ "GenSigTimeoutTime_PBWM" SG_ 271 Feedback_HCP 0;
BA_ "GenSigTimeoutTime_IDCM" SG_ 271 Feedback_HCP 0;
BA_ "GenSigTimeoutTime_ECM" SG_ 271 Feedback_HCP 0;
BA_ "GenSigTimeoutTime_DMPI" SG_ 271 Feedback_HCP 0;
BA_ "GenSigTimeoutTime_BPCM" SG_ 271 Feedback_HCP 0;
BA_ "GenSigTimeoutTime_AGSM" SG_ 271 Feedback_HCP 0;
BA_ "GenSigTimeoutTime_SGW" SG_ 271 HybActEngTorqRespTyp 0;
BA_ "GenSigTimeoutTime_PBWM" SG_ 271 HybActEngTorqRespTyp 0;
BA_ "GenSigTimeoutTime_IDCM" SG_ 271 HybActEngTorqRespTyp 0;
BA_ "GenSigTimeoutTime_ECM" SG_ 271 HybActEngTorqRespTyp 0;
BA_ "GenSigTimeoutTime_DMPI" SG_ 271 HybActEngTorqRespTyp 0;
BA_ "GenSigTimeoutTime_BPCM" SG_ 271 HybActEngTorqRespTyp 0;
BA_ "GenSigTimeoutTime_AGSM" SG_ 271 HybActEngTorqRespTyp 0;
BA_ "GenSigTimeoutTime_SGW" SG_ 271 ECMReq_Remedial_Stop 0;
BA_ "GenSigTimeoutTime_PBWM" SG_ 271 ECMReq_Remedial_Stop 0;
BA_ "GenSigTimeoutTime_IDCM" SG_ 271 ECMReq_Remedial_Stop 0;
BA_ "GenSigTimeoutTime_ECM" SG_ 271 ECMReq_Remedial_Stop 0;
BA_ "GenSigTimeoutTime_DMPI" SG_ 271 ECMReq_Remedial_Stop 0;
BA_ "GenSigTimeoutTime_BPCM" SG_ 271 ECMReq_Remedial_Stop 0;
BA_ "GenSigTimeoutTime_AGSM" SG_ 271 ECMReq_Remedial_Stop 0;
BA_ "GenSigTimeoutTime_SGW" SG_ 271 AccPosV 0;
BA_ "GenSigTimeoutTime_PBWM" SG_ 271 AccPosV 0;
BA_ "GenSigTimeoutTime_IDCM" SG_ 271 AccPosV 0;
BA_ "GenSigTimeoutTime_ECM" SG_ 271 AccPosV 0;
BA_ "GenSigTimeoutTime_DMPI" SG_ 271 AccPosV 0;
BA_ "GenSigTimeoutTime_BPCM" SG_ 271 AccPosV 0;
BA_ "GenSigTimeoutTime_AGSM" SG_ 271 AccPosV 0;
BA_ "GenSigTimeoutTime_SGW" SG_ 271 Cam_Exh_1_Locked 0;
BA_ "GenSigTimeoutTime_PBWM" SG_ 271 Cam_Exh_1_Locked 0;
BA_ "GenSigTimeoutTime_IDCM" SG_ 271 Cam_Exh_1_Locked 0;
BA_ "GenSigTimeoutTime_EVCU2" SG_ 271 Cam_Exh_1_Locked 0;
BA_ "GenSigTimeoutTime_ECM" SG_ 271 Cam_Exh_1_Locked 0;
BA_ "GenSigTimeoutTime_DMPI" SG_ 271 Cam_Exh_1_Locked 0;
BA_ "GenSigTimeoutTime_BPCM" SG_ 271 Cam_Exh_1_Locked 0;
BA_ "GenSigTimeoutTime_AGSM" SG_ 271 Cam_Exh_1_Locked 0;
BA_ "GenSigTimeoutTime_SGW" SG_ 271 Cam_Int_1_Locked 0;
BA_ "GenSigTimeoutTime_PBWM" SG_ 271 Cam_Int_1_Locked 0;
BA_ "GenSigTimeoutTime_IDCM" SG_ 271 Cam_Int_1_Locked 0;
BA_ "GenSigTimeoutTime_EVCU2" SG_ 271 Cam_Int_1_Locked 0;
BA_ "GenSigTimeoutTime_ECM" SG_ 271 Cam_Int_1_Locked 0;
BA_ "GenSigTimeoutTime_DMPI" SG_ 271 Cam_Int_1_Locked 0;
BA_ "GenSigTimeoutTime_BPCM" SG_ 271 Cam_Int_1_Locked 0;
BA_ "GenSigTimeoutTime_AGSM" SG_ 271 Cam_Int_1_Locked 0;
BA_ "GenSigTimeoutTime_SGW" SG_ 271 EngOffRecom 0;
BA_ "GenSigTimeoutTime_PBWM" SG_ 271 EngOffRecom 0;
BA_ "GenSigTimeoutTime_IDCM" SG_ 271 EngOffRecom 0;
BA_ "GenSigTimeoutTime_ECM" SG_ 271 EngOffRecom 0;
BA_ "GenSigTimeoutTime_DMPI" SG_ 271 EngOffRecom 0;
BA_ "GenSigTimeoutTime_BPCM" SG_ 271 EngOffRecom 0;
BA_ "GenSigTimeoutTime_AGSM" SG_ 271 EngOffRecom 0;
BA_ "GenSigTimeoutTime_SGW" SG_ 271 EngRunCrnkAct 0;
BA_ "GenSigTimeoutTime_PBWM" SG_ 271 EngRunCrnkAct 0;
BA_ "GenSigTimeoutTime_IDCM" SG_ 271 EngRunCrnkAct 0;
BA_ "GenSigTimeoutTime_ECM" SG_ 271 EngRunCrnkAct 0;
BA_ "GenSigTimeoutTime_DMPI" SG_ 271 EngRunCrnkAct 0;
BA_ "GenSigTimeoutTime_BPCM" SG_ 271 EngRunCrnkAct 0;
BA_ "GenSigTimeoutTime_AGSM" SG_ 271 EngRunCrnkAct 0;
BA_ "GenSigTimeoutTime_SGW" SG_ 271 Engine_Sync_720 0;
BA_ "GenSigTimeoutTime_PBWM" SG_ 271 Engine_Sync_720 0;
BA_ "GenSigTimeoutTime_IDCM" SG_ 271 Engine_Sync_720 0;
BA_ "GenSigTimeoutTime_EVCU2" SG_ 271 Engine_Sync_720 0;
BA_ "GenSigTimeoutTime_ECM" SG_ 271 Engine_Sync_720 0;
BA_ "GenSigTimeoutTime_DMPI" SG_ 271 Engine_Sync_720 0;
BA_ "GenSigTimeoutTime_BPCM" SG_ 271 Engine_Sync_720 0;
BA_ "GenSigTimeoutTime_AGSM" SG_ 271 Engine_Sync_720 0;
BA_ "GenSigTimeoutTime_SGW" SG_ 271 EngDFCO_St 0;
BA_ "GenSigTimeoutTime_PBWM" SG_ 271 EngDFCO_St 0;
BA_ "GenSigTimeoutTime_IDCM" SG_ 271 EngDFCO_St 0;
BA_ "GenSigTimeoutTime_ECM" SG_ 271 EngDFCO_St 0;
BA_ "GenSigTimeoutTime_DMPI" SG_ 271 EngDFCO_St 0;
BA_ "GenSigTimeoutTime_BPCM" SG_ 271 EngDFCO_St 0;
BA_ "GenSigTimeoutTime_AGSM" SG_ 271 EngDFCO_St 0;
BA_ "GenSigTimeoutTime_SGW" SG_ 271 EngAirFlwStdyStTorqV 0;
BA_ "GenSigTimeoutTime_PBWM" SG_ 271 EngAirFlwStdyStTorqV 0;
BA_ "GenSigTimeoutTime_IDCM" SG_ 271 EngAirFlwStdyStTorqV 0;
BA_ "GenSigTimeoutTime_ECM" SG_ 271 EngAirFlwStdyStTorqV 0;
BA_ "GenSigTimeoutTime_DMPI" SG_ 271 EngAirFlwStdyStTorqV 0;
BA_ "GenSigTimeoutTime_BPCM" SG_ 271 EngAirFlwStdyStTorqV 0;
BA_ "GenSigTimeoutTime_AGSM" SG_ 271 EngAirFlwStdyStTorqV 0;
BA_ "GenSigTimeoutTime_SGW" SG_ 271 EngCmbstnCmnd 0;
BA_ "GenSigTimeoutTime_PBWM" SG_ 271 EngCmbstnCmnd 0;
BA_ "GenSigTimeoutTime_IDCM" SG_ 271 EngCmbstnCmnd 0;
BA_ "GenSigTimeoutTime_ECM" SG_ 271 EngCmbstnCmnd 0;
BA_ "GenSigTimeoutTime_DMPI" SG_ 271 EngCmbstnCmnd 0;
BA_ "GenSigTimeoutTime_BPCM" SG_ 271 EngCmbstnCmnd 0;
BA_ "GenSigTimeoutTime_AGSM" SG_ 271 EngCmbstnCmnd 0;
BA_ "GenSigTimeoutTime_SGW" SG_ 271 EngDFCO_Allw 0;
BA_ "GenSigTimeoutTime_PBWM" SG_ 271 EngDFCO_Allw 0;
BA_ "GenSigTimeoutTime_IDCM" SG_ 271 EngDFCO_Allw 0;
BA_ "GenSigTimeoutTime_ECM" SG_ 271 EngDFCO_Allw 0;
BA_ "GenSigTimeoutTime_DMPI" SG_ 271 EngDFCO_Allw 0;
BA_ "GenSigTimeoutTime_BPCM" SG_ 271 EngDFCO_Allw 0;
BA_ "GenSigTimeoutTime_AGSM" SG_ 271 EngDFCO_Allw 0;
BA_ "GenSigTimeoutTime_SGW" SG_ 271 EngDFCO_Req 0;
BA_ "GenSigTimeoutTime_PBWM" SG_ 271 EngDFCO_Req 0;
BA_ "GenSigTimeoutTime_IDCM" SG_ 271 EngDFCO_Req 0;
BA_ "GenSigTimeoutTime_ECM" SG_ 271 EngDFCO_Req 0;
BA_ "GenSigTimeoutTime_DMPI" SG_ 271 EngDFCO_Req 0;
BA_ "GenSigTimeoutTime_BPCM" SG_ 271 EngDFCO_Req 0;
BA_ "GenSigTimeoutTime_AGSM" SG_ 271 EngDFCO_Req 0;
BA_ "GenSigTimeoutTime_ECM" SG_ 271 Crank_Locked 0;
BA_ "GenSigTimeoutTime_DMPI" SG_ 271 Crank_Locked 0;
BA_ "GenSigTimeoutTime_BPCM" SG_ 271 Crank_Locked 0;
BA_ "GenSigTimeoutTime_AGSM" SG_ 271 Crank_Locked 0;
BA_ "GenSigTimeoutTime_SGW" SG_ 271 Crank_Locked 0;
BA_ "GenSigTimeoutTime_PBWM" SG_ 271 Crank_Locked 0;
BA_ "GenSigTimeoutTime_IDCM" SG_ 271 Crank_Locked 0;
BA_ "GenSigTimeoutTime_EVCU2" SG_ 271 Crank_Locked 0;
BA_ "GenSigTimeoutTime_SGW" SG_ 271 Crank_Maturing_Fault 0;
BA_ "GenSigTimeoutTime_PBWM" SG_ 271 Crank_Maturing_Fault 0;
BA_ "GenSigTimeoutTime_IDCM" SG_ 271 Crank_Maturing_Fault 0;
BA_ "GenSigTimeoutTime_ECM" SG_ 271 Crank_Maturing_Fault 0;
BA_ "GenSigTimeoutTime_DMPI" SG_ 271 Crank_Maturing_Fault 0;
BA_ "GenSigTimeoutTime_BPCM" SG_ 271 Crank_Maturing_Fault 0;
BA_ "GenSigTimeoutTime_AGSM" SG_ 271 Crank_Maturing_Fault 0;
BA_ "GenSigTimeoutTime_SGW" SG_ 271 CRC_ENGINE_HYBD_FD_1 0;
BA_ "GenSigTimeoutTime_PBWM" SG_ 271 CRC_ENGINE_HYBD_FD_1 0;
BA_ "GenSigTimeoutTime_IDCM" SG_ 271 CRC_ENGINE_HYBD_FD_1 0;
BA_ "GenSigTimeoutTime_ECM" SG_ 271 CRC_ENGINE_HYBD_FD_1 0;
BA_ "GenSigTimeoutTime_DMPI" SG_ 271 CRC_ENGINE_HYBD_FD_1 0;
BA_ "GenSigTimeoutTime_BPCM" SG_ 271 CRC_ENGINE_HYBD_FD_1 0;
BA_ "GenSigTimeoutTime_AGSM" SG_ 271 CRC_ENGINE_HYBD_FD_1 0;
BA_ "GenSigTimeoutTime_SGW" SG_ 271 CylOff 0;
BA_ "GenSigTimeoutTime_PBWM" SG_ 271 CylOff 0;
BA_ "GenSigTimeoutTime_IDCM" SG_ 271 CylOff 0;
BA_ "GenSigTimeoutTime_ECM" SG_ 271 CylOff 0;
BA_ "GenSigTimeoutTime_DMPI" SG_ 271 CylOff 0;
BA_ "GenSigTimeoutTime_BPCM" SG_ 271 CylOff 0;
BA_ "GenSigTimeoutTime_AGSM" SG_ 271 CylOff 0;
BA_ "GenSigTimeoutTime_SGW" SG_ 271 EngActStdyStTorq 0;
BA_ "GenSigTimeoutTime_PBWM" SG_ 271 EngActStdyStTorq 0;
BA_ "GenSigTimeoutTime_IDCM" SG_ 271 EngActStdyStTorq 0;
BA_ "GenSigTimeoutTime_ECM" SG_ 271 EngActStdyStTorq 0;
BA_ "GenSigTimeoutTime_DMPI" SG_ 271 EngActStdyStTorq 0;
BA_ "GenSigTimeoutTime_BPCM" SG_ 271 EngActStdyStTorq 0;
BA_ "GenSigTimeoutTime_AGSM" SG_ 271 EngActStdyStTorq 0;
BA_ "GenSigStartValue" SG_ 271 EngActStdyStTorq 938;
BA_ "GenSigTimeoutTime_SGW" SG_ 271 EngActStdyStTorqV 0;
BA_ "GenSigTimeoutTime_PBWM" SG_ 271 EngActStdyStTorqV 0;
BA_ "GenSigTimeoutTime_IDCM" SG_ 271 EngActStdyStTorqV 0;
BA_ "GenSigTimeoutTime_ECM" SG_ 271 EngActStdyStTorqV 0;
BA_ "GenSigTimeoutTime_DMPI" SG_ 271 EngActStdyStTorqV 0;
BA_ "GenSigTimeoutTime_BPCM" SG_ 271 EngActStdyStTorqV 0;
BA_ "GenSigTimeoutTime_AGSM" SG_ 271 EngActStdyStTorqV 0;
BA_ "GenSigTimeoutTime_SGW" SG_ 271 EngActuatorsStat 0;
BA_ "GenSigTimeoutTime_PBWM" SG_ 271 EngActuatorsStat 0;
BA_ "GenSigTimeoutTime_IDCM" SG_ 271 EngActuatorsStat 0;
BA_ "GenSigTimeoutTime_ECM" SG_ 271 EngActuatorsStat 0;
BA_ "GenSigTimeoutTime_DMPI" SG_ 271 EngActuatorsStat 0;
BA_ "GenSigTimeoutTime_BPCM" SG_ 271 EngActuatorsStat 0;
BA_ "GenSigTimeoutTime_AGSM" SG_ 271 EngActuatorsStat 0;
BA_ "GenSigTimeoutTime_SGW" SG_ 271 EngAirFlwStdyStTorq 0;
BA_ "GenSigTimeoutTime_PBWM" SG_ 271 EngAirFlwStdyStTorq 0;
BA_ "GenSigTimeoutTime_IDCM" SG_ 271 EngAirFlwStdyStTorq 0;
BA_ "GenSigTimeoutTime_ECM" SG_ 271 EngAirFlwStdyStTorq 0;
BA_ "GenSigTimeoutTime_DMPI" SG_ 271 EngAirFlwStdyStTorq 0;
BA_ "GenSigTimeoutTime_BPCM" SG_ 271 EngAirFlwStdyStTorq 0;
BA_ "GenSigTimeoutTime_AGSM" SG_ 271 EngAirFlwStdyStTorq 0;
BA_ "GenSigStartValue" SG_ 271 EngAirFlwStdyStTorq 938;
BA_ "GenSigTimeoutTime_SGW" SG_ 271 AccPos 0;
BA_ "GenSigTimeoutTime_SGW" SG_ 271 ECM_Crank_Phase 0;
BA_ "GenSigTimeoutTime_PBWM" SG_ 271 ECM_Crank_Phase 0;
BA_ "GenSigTimeoutTime_IDCM" SG_ 271 ECM_Crank_Phase 0;
BA_ "GenSigTimeoutTime_EVCU2" SG_ 271 ECM_Crank_Phase 0;
BA_ "GenSigTimeoutTime_ECM" SG_ 271 ECM_Crank_Phase 0;
BA_ "GenSigTimeoutTime_DMPI" SG_ 271 ECM_Crank_Phase 0;
BA_ "GenSigTimeoutTime_BPCM" SG_ 271 ECM_Crank_Phase 0;
BA_ "GenSigTimeoutTime_AGSM" SG_ 271 ECM_Crank_Phase 0;
BA_ "GenSigTimeoutTime_SGW" SG_ 271 MAP_4_BAR_PHEV 0;
BA_ "GenSigTimeoutTime_PBWM" SG_ 271 MAP_4_BAR_PHEV 0;
BA_ "GenSigTimeoutTime_IDCM" SG_ 271 MAP_4_BAR_PHEV 0;
BA_ "GenSigTimeoutTime_ECM" SG_ 271 MAP_4_BAR_PHEV 0;
BA_ "GenSigTimeoutTime_DMPI" SG_ 271 MAP_4_BAR_PHEV 0;
BA_ "GenSigTimeoutTime_BPCM" SG_ 271 MAP_4_BAR_PHEV 0;
BA_ "GenSigTimeoutTime_AGSM" SG_ 271 MAP_4_BAR_PHEV 0;
BA_ "GenSigStartValue" SG_ 271 MAP_4_BAR_PHEV 511;
BA_ "GenSigTimeoutTime_SGW" SG_ 2564444402 N_PDU 0;
BA_ "GenSigTimeoutTime_PBWM" SG_ 2564444402 N_PDU 0;
BA_ "GenSigTimeoutTime_IDCM" SG_ 2564444402 N_PDU 0;
BA_ "GenSigTimeoutTime_EVCU2" SG_ 2564444402 N_PDU 0;
BA_ "GenSigTimeoutTime_ECM" SG_ 2564444402 N_PDU 0;
BA_ "GenSigTimeoutTime_DMPI" SG_ 2564444402 N_PDU 0;
BA_ "GenSigTimeoutTime_BPCM" SG_ 2564444402 N_PDU 0;
BA_ "GenSigTimeoutTime_AGSM" SG_ 2564444402 N_PDU 0;
BA_ "GenSigTimeoutTime_SGW" SG_ 2564441330 N_PDU 0;
BA_ "GenSigTimeoutTime_PBWM" SG_ 2564441330 N_PDU 0;
BA_ "GenSigTimeoutTime_IDCM" SG_ 2564441330 N_PDU 0;
BA_ "GenSigTimeoutTime_EVCU2" SG_ 2564441330 N_PDU 0;
BA_ "GenSigTimeoutTime_ECM" SG_ 2564441330 N_PDU 0;
BA_ "GenSigTimeoutTime_DMPI" SG_ 2564441330 N_PDU 0;
BA_ "GenSigTimeoutTime_BPCM" SG_ 2564441330 N_PDU 0;
BA_ "GenSigTimeoutTime_AGSM" SG_ 2564441330 N_PDU 0;
BA_ "GenSigTimeoutTime_SGW" SG_ 2564485700 N_PDU 0;
BA_ "GenSigTimeoutTime_PBWM" SG_ 2564485700 N_PDU 0;
BA_ "GenSigTimeoutTime_IDCM" SG_ 2564485700 N_PDU 0;
BA_ "GenSigTimeoutTime_EVCU2" SG_ 2564485700 N_PDU 0;
BA_ "GenSigTimeoutTime_ECM" SG_ 2564485700 N_PDU 0;
BA_ "GenSigTimeoutTime_DMPI" SG_ 2564485700 N_PDU 0;
BA_ "GenSigTimeoutTime_BPCM" SG_ 2564485700 N_PDU 0;
BA_ "GenSigTimeoutTime_AGSM" SG_ 2564485700 N_PDU 0;
BA_ "GenSigTimeoutTime_SGW" SG_ 258 VehicleSpeedVSOSig 0;
BA_ "GenSigTimeoutTime_PBWM" SG_ 258 VehicleSpeedVSOSig 0;
BA_ "GenSigTimeoutTime_EVCU2" SG_ 258 VehicleSpeedVSOSig 0;
BA_ "GenSigTimeoutTime_ECM" SG_ 258 VehicleSpeedVSOSig 0;
BA_ "GenSigTimeoutTime_DMPI" SG_ 258 VehicleSpeedVSOSig 0;
BA_ "GenSigTimeoutTime_AGSM" SG_ 258 VehicleSpeedVSOSig 0;
BA_ "GenSigTimeoutTime_SGW" SG_ 476 MessageCounter_AGSM2 0;
BA_ "GenSigTimeoutTime_IDCM" SG_ 476 MessageCounter_AGSM2 0;
BA_ "GenSigTimeoutTime_ECM" SG_ 476 MessageCounter_AGSM2 0;
BA_ "GenSigTimeoutTime_DMPI" SG_ 476 MessageCounter_AGSM2 0;
BA_ "GenSigTimeoutTime_BPCM" SG_ 476 MessageCounter_AGSM2 0;
BA_ "GenSigTimeoutTime_AGSM" SG_ 476 MessageCounter_AGSM2 0;
BA_ "GenSigTimeoutTime_SGW" SG_ 476 CRC_AGSM2 0;
BA_ "GenSigTimeoutTime_IDCM" SG_ 476 CRC_AGSM2 0;
BA_ "GenSigTimeoutTime_ECM" SG_ 476 CRC_AGSM2 0;
BA_ "GenSigTimeoutTime_DMPI" SG_ 476 CRC_AGSM2 0;
BA_ "GenSigTimeoutTime_BPCM" SG_ 476 CRC_AGSM2 0;
BA_ "GenSigTimeoutTime_AGSM" SG_ 476 CRC_AGSM2 0;
BA_ "GenSigTimeoutTime_SGW" SG_ 476 ShiftLeverPositionReq 0;
BA_ "GenSigTimeoutTime_IDCM" SG_ 476 ShiftLeverPositionReq 0;
BA_ "GenSigTimeoutTime_ECM" SG_ 476 ShiftLeverPositionReq 0;
BA_ "GenSigTimeoutTime_DMPI" SG_ 476 ShiftLeverPositionReq 0;
BA_ "GenSigTimeoutTime_BPCM" SG_ 476 ShiftLeverPositionReq 0;
BA_ "GenSigTimeoutTime_AGSM" SG_ 476 ShiftLeverPositionReq 0;
BA_ "GenSigSendType" SG_ 476 ShiftLeverPositionReq 3;
BA_ "GenSigTimeoutTime_SGW" SG_ 1851 HVBatCellVoltage_Cell188 0;
BA_ "GenSigTimeoutTime_PBWM" SG_ 1851 HVBatCellVoltage_Cell188 0;
BA_ "GenSigTimeoutTime_SGW" SG_ 1851 HVBatCellVoltage_Cell189 0;
BA_ "GenSigTimeoutTime_PBWM" SG_ 1851 HVBatCellVoltage_Cell189 0;
BA_ "GenSigTimeoutTime_IDCM" SG_ 1851 HVBatCellVoltage_Cell189 0;
BA_ "GenSigTimeoutTime_EVCU2" SG_ 1851 HVBatCellVoltage_Cell189 0;
BA_ "GenSigTimeoutTime_ECM" SG_ 1851 HVBatCellVoltage_Cell189 0;
BA_ "GenSigTimeoutTime_DMPI" SG_ 1851 HVBatCellVoltage_Cell189 0;
BA_ "GenSigTimeoutTime_BPCM" SG_ 1851 HVBatCellVoltage_Cell189 0;
BA_ "GenSigTimeoutTime_AGSM" SG_ 1851 HVBatCellVoltage_Cell189 0;
BA_ "GenSigTimeoutTime_SGW" SG_ 1852 HVBatCellVoltage_Cell190 0;
BA_ "GenSigTimeoutTime_PBWM" SG_ 1852 HVBatCellVoltage_Cell190 0;
BA_ "GenSigTimeoutTime_IDCM" SG_ 1852 HVBatCellVoltage_Cell190 0;
BA_ "GenSigTimeoutTime_EVCU2" SG_ 1852 HVBatCellVoltage_Cell190 0;
BA_ "GenSigTimeoutTime_ECM" SG_ 1852 HVBatCellVoltage_Cell190 0;
BA_ "GenSigTimeoutTime_DMPI" SG_ 1852 HVBatCellVoltage_Cell190 0;
BA_ "GenSigTimeoutTime_BPCM" SG_ 1852 HVBatCellVoltage_Cell190 0;
BA_ "GenSigTimeoutTime_AGSM" SG_ 1852 HVBatCellVoltage_Cell190 0;
BA_ "GenSigTimeoutTime_SGW" SG_ 1852 HVBatCellVoltage_Cell191 0;
BA_ "GenSigTimeoutTime_PBWM" SG_ 1852 HVBatCellVoltage_Cell191 0;
BA_ "GenSigTimeoutTime_IDCM" SG_ 1852 HVBatCellVoltage_Cell191 0;
BA_ "GenSigTimeoutTime_EVCU2" SG_ 1852 HVBatCellVoltage_Cell191 0;
BA_ "GenSigTimeoutTime_ECM" SG_ 1852 HVBatCellVoltage_Cell191 0;
BA_ "GenSigTimeoutTime_DMPI" SG_ 1852 HVBatCellVoltage_Cell191 0;
BA_ "GenSigTimeoutTime_BPCM" SG_ 1852 HVBatCellVoltage_Cell191 0;
BA_ "GenSigTimeoutTime_AGSM" SG_ 1852 HVBatCellVoltage_Cell191 0;
BA_ "GenSigTimeoutTime_BPCM" SG_ 1852 HVBatCellVoltage_Cell192 0;
BA_ "GenSigTimeoutTime_AGSM" SG_ 1852 HVBatCellVoltage_Cell192 0;
BA_ "GenSigTimeoutTime_SGW" SG_ 1852 HVBatCellVoltage_Cell192 0;
BA_ "GenSigTimeoutTime_PBWM" SG_ 1852 HVBatCellVoltage_Cell192 0;
BA_ "GenSigTimeoutTime_IDCM" SG_ 1852 HVBatCellVoltage_Cell192 0;
BA_ "GenSigTimeoutTime_EVCU2" SG_ 1852 HVBatCellVoltage_Cell192 0;
BA_ "GenSigTimeoutTime_ECM" SG_ 1852 HVBatCellVoltage_Cell192 0;
BA_ "GenSigTimeoutTime_DMPI" SG_ 1852 HVBatCellVoltage_Cell192 0;
BA_ "GenSigTimeoutTime_SGW" SG_ 1852 HVBatCellVoltage_Cell193 0;
BA_ "GenSigTimeoutTime_PBWM" SG_ 1852 HVBatCellVoltage_Cell193 0;
BA_ "GenSigTimeoutTime_IDCM" SG_ 1852 HVBatCellVoltage_Cell193 0;
BA_ "GenSigTimeoutTime_EVCU2" SG_ 1852 HVBatCellVoltage_Cell193 0;
BA_ "GenSigTimeoutTime_ECM" SG_ 1852 HVBatCellVoltage_Cell193 0;
BA_ "GenSigTimeoutTime_DMPI" SG_ 1852 HVBatCellVoltage_Cell193 0;
BA_ "GenSigTimeoutTime_BPCM" SG_ 1852 HVBatCellVoltage_Cell193 0;
BA_ "GenSigTimeoutTime_AGSM" SG_ 1852 HVBatCellVoltage_Cell193 0;
BA_ "GenSigTimeoutTime_SGW" SG_ 1852 HVBatCellVoltage_Cell194 0;
BA_ "GenSigTimeoutTime_PBWM" SG_ 1852 HVBatCellVoltage_Cell194 0;
BA_ "GenSigTimeoutTime_IDCM" SG_ 1852 HVBatCellVoltage_Cell194 0;
BA_ "GenSigTimeoutTime_EVCU2" SG_ 1852 HVBatCellVoltage_Cell194 0;
BA_ "GenSigTimeoutTime_ECM" SG_ 1852 HVBatCellVoltage_Cell194 0;
BA_ "GenSigTimeoutTime_DMPI" SG_ 1852 HVBatCellVoltage_Cell194 0;
BA_ "GenSigTimeoutTime_BPCM" SG_ 1852 HVBatCellVoltage_Cell194 0;
BA_ "GenSigTimeoutTime_AGSM" SG_ 1852 HVBatCellVoltage_Cell194 0;
BA_ "GenSigTimeoutTime_SGW" SG_ 1852 HVBatCellVoltage_Cell195 0;
BA_ "GenSigTimeoutTime_PBWM" SG_ 1852 HVBatCellVoltage_Cell195 0;
BA_ "GenSigTimeoutTime_IDCM" SG_ 1852 HVBatCellVoltage_Cell195 0;
BA_ "GenSigTimeoutTime_EVCU2" SG_ 1852 HVBatCellVoltage_Cell195 0;
BA_ "GenSigTimeoutTime_ECM" SG_ 1852 HVBatCellVoltage_Cell195 0;
BA_ "GenSigTimeoutTime_DMPI" SG_ 1852 HVBatCellVoltage_Cell195 0;
BA_ "GenSigTimeoutTime_BPCM" SG_ 1852 HVBatCellVoltage_Cell195 0;
BA_ "GenSigTimeoutTime_AGSM" SG_ 1852 HVBatCellVoltage_Cell195 0;
BA_ "GenSigTimeoutTime_SGW" SG_ 1852 HVBatCellVoltage_Cell196 0;
BA_ "GenSigTimeoutTime_PBWM" SG_ 1852 HVBatCellVoltage_Cell196 0;
BA_ "GenSigTimeoutTime_IDCM" SG_ 1852 HVBatCellVoltage_Cell196 0;
BA_ "GenSigTimeoutTime_EVCU2" SG_ 1852 HVBatCellVoltage_Cell196 0;
BA_ "GenSigTimeoutTime_ECM" SG_ 1852 HVBatCellVoltage_Cell196 0;
BA_ "GenSigTimeoutTime_DMPI" SG_ 1852 HVBatCellVoltage_Cell196 0;
BA_ "GenSigTimeoutTime_BPCM" SG_ 1852 HVBatCellVoltage_Cell196 0;
BA_ "GenSigTimeoutTime_AGSM" SG_ 1852 HVBatCellVoltage_Cell196 0;
BA_ "GenSigTimeoutTime_SGW" SG_ 1852 HVBatCellVoltage_Cell197 0;
BA_ "GenSigTimeoutTime_PBWM" SG_ 1852 HVBatCellVoltage_Cell197 0;
BA_ "GenSigTimeoutTime_IDCM" SG_ 1852 HVBatCellVoltage_Cell197 0;
BA_ "GenSigTimeoutTime_EVCU2" SG_ 1852 HVBatCellVoltage_Cell197 0;
BA_ "GenSigTimeoutTime_ECM" SG_ 1852 HVBatCellVoltage_Cell197 0;
BA_ "GenSigTimeoutTime_DMPI" SG_ 1852 HVBatCellVoltage_Cell197 0;
BA_ "GenSigTimeoutTime_BPCM" SG_ 1852 HVBatCellVoltage_Cell197 0;
BA_ "GenSigTimeoutTime_AGSM" SG_ 1852 HVBatCellVoltage_Cell197 0;
BA_ "GenSigTimeoutTime_SGW" SG_ 1852 HVBatCellVoltage_Cell198 0;
BA_ "GenSigTimeoutTime_PBWM" SG_ 1852 HVBatCellVoltage_Cell198 0;
BA_ "GenSigTimeoutTime_IDCM" SG_ 1852 HVBatCellVoltage_Cell198 0;
BA_ "GenSigTimeoutTime_EVCU2" SG_ 1852 HVBatCellVoltage_Cell198 0;
BA_ "GenSigTimeoutTime_ECM" SG_ 1852 HVBatCellVoltage_Cell198 0;
BA_ "GenSigTimeoutTime_DMPI" SG_ 1852 HVBatCellVoltage_Cell198 0;
BA_ "GenSigTimeoutTime_BPCM" SG_ 1852 HVBatCellVoltage_Cell198 0;
BA_ "GenSigTimeoutTime_AGSM" SG_ 1852 HVBatCellVoltage_Cell198 0;
BA_ "GenSigTimeoutTime_SGW" SG_ 1852 HVBatCellVoltage_Cell200 0;
BA_ "GenSigTimeoutTime_PBWM" SG_ 1852 HVBatCellVoltage_Cell200 0;
BA_ "GenSigTimeoutTime_IDCM" SG_ 1852 HVBatCellVoltage_Cell200 0;
BA_ "GenSigTimeoutTime_EVCU2" SG_ 1852 HVBatCellVoltage_Cell200 0;
BA_ "GenSigTimeoutTime_ECM" SG_ 1852 HVBatCellVoltage_Cell200 0;
BA_ "GenSigTimeoutTime_DMPI" SG_ 1852 HVBatCellVoltage_Cell200 0;
BA_ "GenSigTimeoutTime_BPCM" SG_ 1852 HVBatCellVoltage_Cell200 0;
BA_ "GenSigTimeoutTime_AGSM" SG_ 1852 HVBatCellVoltage_Cell200 0;
BA_ "GenSigTimeoutTime_SGW" SG_ 1852 HVBatCellVoltage_Cell201 0;
BA_ "GenSigTimeoutTime_PBWM" SG_ 1852 HVBatCellVoltage_Cell201 0;
BA_ "GenSigTimeoutTime_IDCM" SG_ 1852 HVBatCellVoltage_Cell201 0;
BA_ "GenSigTimeoutTime_EVCU2" SG_ 1852 HVBatCellVoltage_Cell201 0;
BA_ "GenSigTimeoutTime_ECM" SG_ 1852 HVBatCellVoltage_Cell201 0;
BA_ "GenSigTimeoutTime_DMPI" SG_ 1852 HVBatCellVoltage_Cell201 0;
BA_ "GenSigTimeoutTime_BPCM" SG_ 1852 HVBatCellVoltage_Cell201 0;
BA_ "GenSigTimeoutTime_AGSM" SG_ 1852 HVBatCellVoltage_Cell201 0;
BA_ "GenSigTimeoutTime_SGW" SG_ 1852 HVBatCellVoltage_Cell202 0;
BA_ "GenSigTimeoutTime_PBWM" SG_ 1852 HVBatCellVoltage_Cell202 0;
BA_ "GenSigTimeoutTime_IDCM" SG_ 1852 HVBatCellVoltage_Cell202 0;
BA_ "GenSigTimeoutTime_EVCU2" SG_ 1852 HVBatCellVoltage_Cell202 0;
BA_ "GenSigTimeoutTime_ECM" SG_ 1852 HVBatCellVoltage_Cell202 0;
BA_ "GenSigTimeoutTime_DMPI" SG_ 1852 HVBatCellVoltage_Cell202 0;
BA_ "GenSigTimeoutTime_BPCM" SG_ 1852 HVBatCellVoltage_Cell202 0;
BA_ "GenSigTimeoutTime_AGSM" SG_ 1852 HVBatCellVoltage_Cell202 0;
BA_ "GenSigTimeoutTime_SGW" SG_ 1852 HVBatCellVoltage_Cell203 0;
BA_ "GenSigTimeoutTime_PBWM" SG_ 1852 HVBatCellVoltage_Cell203 0;
BA_ "GenSigTimeoutTime_IDCM" SG_ 1852 HVBatCellVoltage_Cell203 0;
BA_ "GenSigTimeoutTime_EVCU2" SG_ 1852 HVBatCellVoltage_Cell203 0;
BA_ "GenSigTimeoutTime_ECM" SG_ 1852 HVBatCellVoltage_Cell203 0;
BA_ "GenSigTimeoutTime_DMPI" SG_ 1852 HVBatCellVoltage_Cell203 0;
BA_ "GenSigTimeoutTime_BPCM" SG_ 1852 HVBatCellVoltage_Cell203 0;
BA_ "GenSigTimeoutTime_AGSM" SG_ 1852 HVBatCellVoltage_Cell203 0;
BA_ "GenSigTimeoutTime_SGW" SG_ 1852 HVBatCellVoltage_Cell204 0;
BA_ "GenSigTimeoutTime_PBWM" SG_ 1852 HVBatCellVoltage_Cell204 0;
BA_ "GenSigTimeoutTime_IDCM" SG_ 1852 HVBatCellVoltage_Cell204 0;
BA_ "GenSigTimeoutTime_EVCU2" SG_ 1852 HVBatCellVoltage_Cell204 0;
BA_ "GenSigTimeoutTime_ECM" SG_ 1852 HVBatCellVoltage_Cell204 0;
BA_ "GenSigTimeoutTime_DMPI" SG_ 1852 HVBatCellVoltage_Cell204 0;
BA_ "GenSigTimeoutTime_BPCM" SG_ 1852 HVBatCellVoltage_Cell204 0;
BA_ "GenSigTimeoutTime_AGSM" SG_ 1852 HVBatCellVoltage_Cell204 0;
BA_ "GenSigTimeoutTime_SGW" SG_ 1852 HVBatCellVoltage_Cell205 0;
BA_ "GenSigTimeoutTime_PBWM" SG_ 1852 HVBatCellVoltage_Cell205 0;
BA_ "GenSigTimeoutTime_IDCM" SG_ 1852 HVBatCellVoltage_Cell205 0;
BA_ "GenSigTimeoutTime_EVCU2" SG_ 1852 HVBatCellVoltage_Cell205 0;
BA_ "GenSigTimeoutTime_ECM" SG_ 1852 HVBatCellVoltage_Cell205 0;
BA_ "GenSigTimeoutTime_DMPI" SG_ 1852 HVBatCellVoltage_Cell205 0;
BA_ "GenSigTimeoutTime_BPCM" SG_ 1852 HVBatCellVoltage_Cell205 0;
BA_ "GenSigTimeoutTime_AGSM" SG_ 1852 HVBatCellVoltage_Cell205 0;
BA_ "GenSigTimeoutTime_SGW" SG_ 1852 HVBatCellVoltage_Cell206 0;
BA_ "GenSigTimeoutTime_PBWM" SG_ 1852 HVBatCellVoltage_Cell206 0;
BA_ "GenSigTimeoutTime_IDCM" SG_ 1852 HVBatCellVoltage_Cell206 0;
BA_ "GenSigTimeoutTime_EVCU2" SG_ 1852 HVBatCellVoltage_Cell206 0;
BA_ "GenSigTimeoutTime_ECM" SG_ 1852 HVBatCellVoltage_Cell206 0;
BA_ "GenSigTimeoutTime_DMPI" SG_ 1852 HVBatCellVoltage_Cell206 0;
BA_ "GenSigTimeoutTime_BPCM" SG_ 1852 HVBatCellVoltage_Cell206 0;
BA_ "GenSigTimeoutTime_AGSM" SG_ 1852 HVBatCellVoltage_Cell206 0;
BA_ "GenSigTimeoutTime_SGW" SG_ 1852 HVBatCellVoltage_Cell207 0;
BA_ "GenSigTimeoutTime_PBWM" SG_ 1852 HVBatCellVoltage_Cell207 0;
BA_ "GenSigTimeoutTime_IDCM" SG_ 1852 HVBatCellVoltage_Cell207 0;
BA_ "GenSigTimeoutTime_EVCU2" SG_ 1852 HVBatCellVoltage_Cell207 0;
BA_ "GenSigTimeoutTime_ECM" SG_ 1852 HVBatCellVoltage_Cell207 0;
BA_ "GenSigTimeoutTime_DMPI" SG_ 1852 HVBatCellVoltage_Cell207 0;
BA_ "GenSigTimeoutTime_BPCM" SG_ 1852 HVBatCellVoltage_Cell207 0;
BA_ "GenSigTimeoutTime_AGSM" SG_ 1852 HVBatCellVoltage_Cell207 0;
BA_ "GenSigTimeoutTime_SGW" SG_ 1852 HVBatCellVoltage_Cell208 0;
BA_ "GenSigTimeoutTime_PBWM" SG_ 1852 HVBatCellVoltage_Cell208 0;
BA_ "GenSigTimeoutTime_IDCM" SG_ 1852 HVBatCellVoltage_Cell208 0;
BA_ "GenSigTimeoutTime_EVCU2" SG_ 1852 HVBatCellVoltage_Cell208 0;
BA_ "GenSigTimeoutTime_ECM" SG_ 1852 HVBatCellVoltage_Cell208 0;
BA_ "GenSigTimeoutTime_DMPI" SG_ 1852 HVBatCellVoltage_Cell208 0;
BA_ "GenSigTimeoutTime_BPCM" SG_ 1852 HVBatCellVoltage_Cell208 0;
BA_ "GenSigTimeoutTime_AGSM" SG_ 1852 HVBatCellVoltage_Cell208 0;
BA_ "GenSigTimeoutTime_SGW" SG_ 1852 HVBatCellVoltage_Cell209 0;
BA_ "GenSigTimeoutTime_PBWM" SG_ 1852 HVBatCellVoltage_Cell209 0;
BA_ "GenSigTimeoutTime_IDCM" SG_ 1852 HVBatCellVoltage_Cell209 0;
BA_ "GenSigTimeoutTime_EVCU2" SG_ 1852 HVBatCellVoltage_Cell209 0;
BA_ "GenSigTimeoutTime_ECM" SG_ 1852 HVBatCellVoltage_Cell209 0;
BA_ "GenSigTimeoutTime_DMPI" SG_ 1852 HVBatCellVoltage_Cell209 0;
BA_ "GenSigTimeoutTime_BPCM" SG_ 1852 HVBatCellVoltage_Cell209 0;
BA_ "GenSigTimeoutTime_AGSM" SG_ 1852 HVBatCellVoltage_Cell209 0;
BA_ "GenSigTimeoutTime_SGW" SG_ 1852 HVBatCellVoltage_Cell210 0;
BA_ "GenSigTimeoutTime_PBWM" SG_ 1852 HVBatCellVoltage_Cell210 0;
BA_ "GenSigTimeoutTime_IDCM" SG_ 1852 HVBatCellVoltage_Cell210 0;
BA_ "GenSigTimeoutTime_EVCU2" SG_ 1852 HVBatCellVoltage_Cell210 0;
BA_ "GenSigTimeoutTime_ECM" SG_ 1852 HVBatCellVoltage_Cell210 0;
BA_ "GenSigTimeoutTime_DMPI" SG_ 1852 HVBatCellVoltage_Cell210 0;
BA_ "GenSigTimeoutTime_BPCM" SG_ 1852 HVBatCellVoltage_Cell210 0;
BA_ "GenSigTimeoutTime_AGSM" SG_ 1852 HVBatCellVoltage_Cell210 0;
BA_ "GenSigTimeoutTime_SGW" SG_ 1852 HVBatCellVoltage_Cell211 0;
BA_ "GenSigTimeoutTime_PBWM" SG_ 1852 HVBatCellVoltage_Cell211 0;
BA_ "GenSigTimeoutTime_IDCM" SG_ 1852 HVBatCellVoltage_Cell211 0;
BA_ "GenSigTimeoutTime_EVCU2" SG_ 1852 HVBatCellVoltage_Cell211 0;
BA_ "GenSigTimeoutTime_ECM" SG_ 1852 HVBatCellVoltage_Cell211 0;
BA_ "GenSigTimeoutTime_DMPI" SG_ 1852 HVBatCellVoltage_Cell211 0;
BA_ "GenSigTimeoutTime_BPCM" SG_ 1852 HVBatCellVoltage_Cell211 0;
BA_ "GenSigTimeoutTime_AGSM" SG_ 1852 HVBatCellVoltage_Cell211 0;
BA_ "GenSigTimeoutTime_SGW" SG_ 1852 HVBatCellVoltage_Cell212 0;
BA_ "GenSigTimeoutTime_PBWM" SG_ 1852 HVBatCellVoltage_Cell212 0;
BA_ "GenSigTimeoutTime_IDCM" SG_ 1852 HVBatCellVoltage_Cell212 0;
BA_ "GenSigTimeoutTime_EVCU2" SG_ 1852 HVBatCellVoltage_Cell212 0;
BA_ "GenSigTimeoutTime_ECM" SG_ 1852 HVBatCellVoltage_Cell212 0;
BA_ "GenSigTimeoutTime_DMPI" SG_ 1852 HVBatCellVoltage_Cell212 0;
BA_ "GenSigTimeoutTime_BPCM" SG_ 1852 HVBatCellVoltage_Cell212 0;
BA_ "GenSigTimeoutTime_AGSM" SG_ 1852 HVBatCellVoltage_Cell212 0;
BA_ "GenSigTimeoutTime_SGW" SG_ 1852 HVBatCellVoltage_Cell213 0;
BA_ "GenSigTimeoutTime_PBWM" SG_ 1852 HVBatCellVoltage_Cell213 0;
BA_ "GenSigTimeoutTime_IDCM" SG_ 1852 HVBatCellVoltage_Cell213 0;
BA_ "GenSigTimeoutTime_EVCU2" SG_ 1852 HVBatCellVoltage_Cell213 0;
BA_ "GenSigTimeoutTime_ECM" SG_ 1852 HVBatCellVoltage_Cell213 0;
BA_ "GenSigTimeoutTime_DMPI" SG_ 1852 HVBatCellVoltage_Cell213 0;
BA_ "GenSigTimeoutTime_BPCM" SG_ 1852 HVBatCellVoltage_Cell213 0;
BA_ "GenSigTimeoutTime_AGSM" SG_ 1852 HVBatCellVoltage_Cell213 0;
BA_ "GenSigTimeoutTime_SGW" SG_ 1852 HVBatCellVoltage_Cell214 0;
BA_ "GenSigTimeoutTime_PBWM" SG_ 1852 HVBatCellVoltage_Cell214 0;
BA_ "GenSigTimeoutTime_IDCM" SG_ 1852 HVBatCellVoltage_Cell214 0;
BA_ "GenSigTimeoutTime_EVCU2" SG_ 1852 HVBatCellVoltage_Cell214 0;
BA_ "GenSigTimeoutTime_ECM" SG_ 1852 HVBatCellVoltage_Cell214 0;
BA_ "GenSigTimeoutTime_DMPI" SG_ 1852 HVBatCellVoltage_Cell214 0;
BA_ "GenSigTimeoutTime_BPCM" SG_ 1852 HVBatCellVoltage_Cell214 0;
BA_ "GenSigTimeoutTime_AGSM" SG_ 1852 HVBatCellVoltage_Cell214 0;
BA_ "GenSigTimeoutTime_SGW" SG_ 1852 HVBatCellVoltage_Cell215 0;
BA_ "GenSigTimeoutTime_PBWM" SG_ 1852 HVBatCellVoltage_Cell215 0;
BA_ "GenSigTimeoutTime_IDCM" SG_ 1852 HVBatCellVoltage_Cell215 0;
BA_ "GenSigTimeoutTime_EVCU2" SG_ 1852 HVBatCellVoltage_Cell215 0;
BA_ "GenSigTimeoutTime_ECM" SG_ 1852 HVBatCellVoltage_Cell215 0;
BA_ "GenSigTimeoutTime_DMPI" SG_ 1852 HVBatCellVoltage_Cell215 0;
BA_ "GenSigTimeoutTime_BPCM" SG_ 1852 HVBatCellVoltage_Cell215 0;
BA_ "GenSigTimeoutTime_AGSM" SG_ 1852 HVBatCellVoltage_Cell215 0;
BA_ "GenSigTimeoutTime_EVCU2" SG_ 1852 HVBatCellVoltage_Cell216 0;
BA_ "GenSigTimeoutTime_ECM" SG_ 1852 HVBatCellVoltage_Cell216 0;
BA_ "GenSigTimeoutTime_DMPI" SG_ 1852 HVBatCellVoltage_Cell216 0;
BA_ "GenSigTimeoutTime_BPCM" SG_ 1852 HVBatCellVoltage_Cell216 0;
BA_ "GenSigTimeoutTime_AGSM" SG_ 1852 HVBatCellVoltage_Cell216 0;
BA_ "GenSigTimeoutTime_SGW" SG_ 1372 OBC_Temp1 0;
BA_ "GenSigTimeoutTime_PBWM" SG_ 1372 OBC_Temp1 0;
BA_ "GenSigTimeoutTime_IDCM" SG_ 1372 OBC_Temp1 0;
BA_ "GenSigTimeoutTime_ECM" SG_ 1372 OBC_Temp1 0;
BA_ "GenSigTimeoutTime_DMPI" SG_ 1372 OBC_Temp1 0;
BA_ "GenSigTimeoutTime_BPCM" SG_ 1372 OBC_Temp1 0;
BA_ "GenSigTimeoutTime_AGSM" SG_ 1372 OBC_Temp1 0;
BA_ "GenSigTimeoutTime_SGW" SG_ 1372 OBC_Temp2 0;
BA_ "GenSigTimeoutTime_PBWM" SG_ 1372 OBC_Temp2 0;
BA_ "GenSigTimeoutTime_IDCM" SG_ 1372 OBC_Temp2 0;
BA_ "GenSigTimeoutTime_ECM" SG_ 1372 OBC_Temp2 0;
BA_ "GenSigTimeoutTime_DMPI" SG_ 1372 OBC_Temp2 0;
BA_ "GenSigTimeoutTime_BPCM" SG_ 1372 OBC_Temp2 0;
BA_ "GenSigTimeoutTime_AGSM" SG_ 1372 OBC_Temp2 0;
BA_ "GenSigTimeoutTime_SGW" SG_ 1372 OBC_Temp3 0;
BA_ "GenSigTimeoutTime_PBWM" SG_ 1372 OBC_Temp3 0;
BA_ "GenSigTimeoutTime_IDCM" SG_ 1372 OBC_Temp3 0;
BA_ "GenSigTimeoutTime_ECM" SG_ 1372 OBC_Temp3 0;
BA_ "GenSigTimeoutTime_DMPI" SG_ 1372 OBC_Temp3 0;
BA_ "GenSigTimeoutTime_BPCM" SG_ 1372 OBC_Temp3 0;
BA_ "GenSigTimeoutTime_AGSM" SG_ 1372 OBC_Temp3 0;
BA_ "GenSigTimeoutTime_SGW" SG_ 1372 OBC_Temp4 0;
BA_ "GenSigTimeoutTime_PBWM" SG_ 1372 OBC_Temp4 0;
BA_ "GenSigTimeoutTime_IDCM" SG_ 1372 OBC_Temp4 0;
BA_ "GenSigTimeoutTime_ECM" SG_ 1372 OBC_Temp4 0;
BA_ "GenSigTimeoutTime_DMPI" SG_ 1372 OBC_Temp4 0;
BA_ "GenSigTimeoutTime_BPCM" SG_ 1372 OBC_Temp4 0;
BA_ "GenSigTimeoutTime_AGSM" SG_ 1372 OBC_Temp4 0;
BA_ "GenSigTimeoutTime_PBWM" SG_ 271 AccPos 0;
BA_ "GenSigTimeoutTime_IDCM" SG_ 271 AccPos 0;
BA_ "GenSigTimeoutTime_ECM" SG_ 271 AccPos 0;
BA_ "GenSigTimeoutTime_DMPI" SG_ 271 AccPos 0;
BA_ "GenSigTimeoutTime_BPCM" SG_ 271 AccPos 0;
BA_ "GenSigTimeoutTime_AGSM" SG_ 271 AccPos 0;
BA_ "GenSigTimeoutTime_SGW" SG_ 2564682064 N_PDU 0;
BA_ "GenSigTimeoutTime_PBWM" SG_ 2564682064 N_PDU 0;
BA_ "GenSigTimeoutTime_IDCM" SG_ 2564682064 N_PDU 0;
BA_ "GenSigTimeoutTime_EVCU2" SG_ 2564682064 N_PDU 0;
BA_ "GenSigTimeoutTime_ECM" SG_ 2564682064 N_PDU 0;
BA_ "GenSigTimeoutTime_DMPI" SG_ 2564682064 N_PDU 0;
BA_ "GenSigTimeoutTime_BPCM" SG_ 2564682064 N_PDU 0;
BA_ "GenSigTimeoutTime_AGSM" SG_ 2564682064 N_PDU 0;
BA_ "GenSigTimeoutTime_SGW" SG_ 2564682052 N_PDU 0;
BA_ "GenSigTimeoutTime_PBWM" SG_ 2564682052 N_PDU 0;
BA_ "GenSigTimeoutTime_IDCM" SG_ 2564682052 N_PDU 0;
BA_ "GenSigTimeoutTime_EVCU2" SG_ 2564682052 N_PDU 0;
BA_ "GenSigTimeoutTime_ECM" SG_ 2564682052 N_PDU 0;
BA_ "GenSigTimeoutTime_DMPI" SG_ 2564682052 N_PDU 0;
BA_ "GenSigTimeoutTime_BPCM" SG_ 2564682052 N_PDU 0;
BA_ "GenSigTimeoutTime_AGSM" SG_ 2564682052 N_PDU 0;
BA_ "GenSigTimeoutTime_SGW" SG_ 2564682308 N_PDU 0;
BA_ "GenSigTimeoutTime_PBWM" SG_ 2564682308 N_PDU 0;
BA_ "GenSigTimeoutTime_IDCM" SG_ 2564682308 N_PDU 0;
BA_ "GenSigTimeoutTime_EVCU2" SG_ 2564682308 N_PDU 0;
BA_ "GenSigTimeoutTime_ECM" SG_ 2564682308 N_PDU 0;
BA_ "GenSigTimeoutTime_DMPI" SG_ 2564682308 N_PDU 0;
BA_ "GenSigTimeoutTime_BPCM" SG_ 2564682308 N_PDU 0;
BA_ "GenSigTimeoutTime_AGSM" SG_ 2564682308 N_PDU 0;
BA_ "GenSigTimeoutTime_SGW" SG_ 2564682320 N_PDU 0;
BA_ "GenSigTimeoutTime_PBWM" SG_ 2564682320 N_PDU 0;
BA_ "GenSigTimeoutTime_IDCM" SG_ 2564682320 N_PDU 0;
BA_ "GenSigTimeoutTime_EVCU2" SG_ 2564682320 N_PDU 0;
BA_ "GenSigTimeoutTime_ECM" SG_ 2564682320 N_PDU 0;
BA_ "GenSigTimeoutTime_DMPI" SG_ 2564682320 N_PDU 0;
BA_ "GenSigTimeoutTime_BPCM" SG_ 2564682320 N_PDU 0;
BA_ "GenSigTimeoutTime_AGSM" SG_ 2564682320 N_PDU 0;
BA_ "GenSigTimeoutTime_SGW" SG_ 2564485712 N_PDU 0;
BA_ "GenSigTimeoutTime_PBWM" SG_ 2564485712 N_PDU 0;
BA_ "GenSigTimeoutTime_IDCM" SG_ 2564485712 N_PDU 0;
BA_ "GenSigTimeoutTime_EVCU2" SG_ 2564485712 N_PDU 0;
BA_ "GenSigTimeoutTime_ECM" SG_ 2564485712 N_PDU 0;
BA_ "GenSigTimeoutTime_DMPI" SG_ 2564485712 N_PDU 0;
BA_ "GenSigTimeoutTime_BPCM" SG_ 2564485712 N_PDU 0;
BA_ "GenSigTimeoutTime_AGSM" SG_ 2564485712 N_PDU 0;
BA_ "GenSigTimeoutTime_SGW" SG_ 2654486653 CBV_bit0_RepeatMessageRequestBit 0;
BA_ "GenSigTimeoutTime_PBWM" SG_ 2654486653 CBV_bit0_RepeatMessageRequestBit 0;
BA_ "GenSigTimeoutTime_IDCM" SG_ 2654486653 CBV_bit0_RepeatMessageRequestBit 0;
BA_ "GenSigTimeoutTime_EVCU2" SG_ 2654486653 CBV_bit0_RepeatMessageRequestBit 0;
BA_ "GenSigTimeoutTime_SGW" SG_ 2654486653 CBV_bit1 0;
BA_ "GenSigTimeoutTime_PBWM" SG_ 2654486653 CBV_bit1 0;
BA_ "GenSigTimeoutTime_IDCM" SG_ 2654486653 CBV_bit1 0;
BA_ "GenSigTimeoutTime_EVCU2" SG_ 2654486653 CBV_bit1 0;
BA_ "GenSigTimeoutTime_ECM" SG_ 2654486653 CBV_bit1 0;
BA_ "GenSigTimeoutTime_DMPI" SG_ 2654486653 CBV_bit1 0;
BA_ "GenSigTimeoutTime_BPCM" SG_ 2654486653 CBV_bit1 0;
BA_ "GenSigTimeoutTime_AGSM" SG_ 2654486653 CBV_bit1 0;
BA_ "GenSigTimeoutTime_SGW" SG_ 2654486653 CBV_bit3_NMCoordinatorBit 0;
BA_ "GenSigTimeoutTime_PBWM" SG_ 2654486653 CBV_bit3_NMCoordinatorBit 0;
BA_ "GenSigTimeoutTime_IDCM" SG_ 2654486653 CBV_bit3_NMCoordinatorBit 0;
BA_ "GenSigTimeoutTime_EVCU2" SG_ 2654486653 CBV_bit3_NMCoordinatorBit 0;
BA_ "GenSigTimeoutTime_ECM" SG_ 2654486653 CBV_bit3_NMCoordinatorBit 0;
BA_ "GenSigTimeoutTime_DMPI" SG_ 2654486653 CBV_bit3_NMCoordinatorBit 0;
BA_ "GenSigTimeoutTime_BPCM" SG_ 2654486653 CBV_bit3_NMCoordinatorBit 0;
BA_ "GenSigTimeoutTime_AGSM" SG_ 2654486653 CBV_bit3_NMCoordinatorBit 0;
BA_ "GenSigTimeoutTime_SGW" SG_ 2654486653 CBV_bit2 0;
BA_ "GenSigTimeoutTime_PBWM" SG_ 2654486653 CBV_bit2 0;
BA_ "GenSigTimeoutTime_IDCM" SG_ 2654486653 CBV_bit2 0;
BA_ "GenSigTimeoutTime_EVCU2" SG_ 2654486653 CBV_bit2 0;
BA_ "GenSigTimeoutTime_ECM" SG_ 2654486653 CBV_bit2 0;
BA_ "GenSigTimeoutTime_DMPI" SG_ 2654486653 CBV_bit2 0;
BA_ "GenSigTimeoutTime_BPCM" SG_ 2654486653 CBV_bit2 0;
BA_ "GenSigTimeoutTime_AGSM" SG_ 2654486653 CBV_bit2 0;
BA_ "GenSigTimeoutTime_SGW" SG_ 2654486653 CBV_bit7 0;
BA_ "GenSigTimeoutTime_PBWM" SG_ 2654486653 CBV_bit7 0;
BA_ "GenSigTimeoutTime_IDCM" SG_ 2654486653 CBV_bit7 0;
BA_ "GenSigTimeoutTime_EVCU2" SG_ 2654486653 CBV_bit7 0;
BA_ "GenSigTimeoutTime_ECM" SG_ 2654486653 CBV_bit7 0;
BA_ "GenSigTimeoutTime_DMPI" SG_ 2654486653 CBV_bit7 0;
BA_ "GenSigTimeoutTime_BPCM" SG_ 2654486653 CBV_bit7 0;
BA_ "GenSigTimeoutTime_AGSM" SG_ 2654486653 CBV_bit7 0;
BA_ "GenSigTimeoutTime_SGW" SG_ 2654486653 SourceNodeIdentifier 0;
BA_ "GenSigTimeoutTime_PBWM" SG_ 2654486653 SourceNodeIdentifier 0;
BA_ "GenSigTimeoutTime_IDCM" SG_ 2654486653 SourceNodeIdentifier 0;
BA_ "GenSigTimeoutTime_EVCU2" SG_ 2654486653 SourceNodeIdentifier 0;
BA_ "GenSigTimeoutTime_ECM" SG_ 2654486653 SourceNodeIdentifier 0;
BA_ "GenSigTimeoutTime_DMPI" SG_ 2654486653 SourceNodeIdentifier 0;
BA_ "GenSigTimeoutTime_BPCM" SG_ 2654486653 SourceNodeIdentifier 0;
BA_ "GenSigTimeoutTime_AGSM" SG_ 2654486653 SourceNodeIdentifier 0;
BA_ "GenSigTimeoutTime_SGW" SG_ 2654486653 CBV_bit4_ActiveWakeupBit 0;
BA_ "GenSigTimeoutTime_PBWM" SG_ 2654486653 CBV_bit4_ActiveWakeupBit 0;
BA_ "GenSigTimeoutTime_IDCM" SG_ 2654486653 CBV_bit4_ActiveWakeupBit 0;
BA_ "GenSigTimeoutTime_EVCU2" SG_ 2654486653 CBV_bit4_ActiveWakeupBit 0;
BA_ "GenSigTimeoutTime_ECM" SG_ 2654486653 CBV_bit4_ActiveWakeupBit 0;
BA_ "GenSigTimeoutTime_DMPI" SG_ 2654486653 CBV_bit4_ActiveWakeupBit 0;
BA_ "GenSigTimeoutTime_BPCM" SG_ 2654486653 CBV_bit4_ActiveWakeupBit 0;
BA_ "GenSigTimeoutTime_AGSM" SG_ 2654486653 CBV_bit4_ActiveWakeupBit 0;
BA_ "GenSigTimeoutTime_SGW" SG_ 2654486653 CBV_bit6_PartialNtwInfBit 0;
BA_ "GenSigTimeoutTime_PBWM" SG_ 2654486653 CBV_bit6_PartialNtwInfBit 0;
BA_ "GenSigTimeoutTime_IDCM" SG_ 2654486653 CBV_bit6_PartialNtwInfBit 0;
BA_ "GenSigTimeoutTime_EVCU2" SG_ 2654486653 CBV_bit6_PartialNtwInfBit 0;
BA_ "GenSigTimeoutTime_ECM" SG_ 2654486653 CBV_bit6_PartialNtwInfBit 0;
BA_ "GenSigTimeoutTime_DMPI" SG_ 2654486653 CBV_bit6_PartialNtwInfBit 0;
BA_ "GenSigTimeoutTime_BPCM" SG_ 2654486653 CBV_bit6_PartialNtwInfBit 0;
BA_ "GenSigTimeoutTime_AGSM" SG_ 2654486653 CBV_bit6_PartialNtwInfBit 0;
BA_ "GenSigTimeoutTime_SGW" SG_ 2654486653 CBV_bit5 0;
BA_ "GenSigTimeoutTime_PBWM" SG_ 2654486653 CBV_bit5 0;
BA_ "GenSigTimeoutTime_IDCM" SG_ 2654486653 CBV_bit5 0;
BA_ "GenSigTimeoutTime_EVCU2" SG_ 2654486653 CBV_bit5 0;
BA_ "GenSigTimeoutTime_ECM" SG_ 2654486653 CBV_bit5 0;
BA_ "GenSigTimeoutTime_DMPI" SG_ 2654486653 CBV_bit5 0;
BA_ "GenSigTimeoutTime_BPCM" SG_ 2654486653 CBV_bit5 0;
BA_ "GenSigTimeoutTime_AGSM" SG_ 2654486653 CBV_bit5 0;
BA_ "GenSigTimeoutTime_ECM" SG_ 2654486653 CBV_bit0_RepeatMessageRequestBit 0;
BA_ "GenSigTimeoutTime_DMPI" SG_ 2654486653 CBV_bit0_RepeatMessageRequestBit 0;
BA_ "GenSigTimeoutTime_BPCM" SG_ 2654486653 CBV_bit0_RepeatMessageRequestBit 0;
BA_ "GenSigTimeoutTime_AGSM" SG_ 2654486653 CBV_bit0_RepeatMessageRequestBit 0;
BA_ "GenSigTimeoutTime_SGW" SG_ 2654486598 CBV_bit0_RepeatMessageRequestBit 0;
BA_ "GenSigTimeoutTime_PBWM" SG_ 2654486598 CBV_bit0_RepeatMessageRequestBit 0;
BA_ "GenSigTimeoutTime_IDCM" SG_ 2654486598 CBV_bit0_RepeatMessageRequestBit 0;
BA_ "GenSigTimeoutTime_EVCU2" SG_ 2654486598 CBV_bit0_RepeatMessageRequestBit 0;
BA_ "GenSigTimeoutTime_ECM" SG_ 2654486598 CBV_bit0_RepeatMessageRequestBit 0;
BA_ "GenSigTimeoutTime_DMPI" SG_ 2654486598 CBV_bit0_RepeatMessageRequestBit 0;
BA_ "GenSigTimeoutTime_BPCM" SG_ 2654486598 CBV_bit0_RepeatMessageRequestBit 0;
BA_ "GenSigTimeoutTime_AGSM" SG_ 2654486598 CBV_bit0_RepeatMessageRequestBit 0;
BA_ "GenSigTimeoutTime_SGW" SG_ 2654486598 CBV_bit1 0;
BA_ "GenSigTimeoutTime_PBWM" SG_ 2654486598 CBV_bit1 0;
BA_ "GenSigTimeoutTime_IDCM" SG_ 2654486598 CBV_bit1 0;
BA_ "GenSigTimeoutTime_EVCU2" SG_ 2654486598 CBV_bit1 0;
BA_ "GenSigTimeoutTime_ECM" SG_ 2654486598 CBV_bit1 0;
BA_ "GenSigTimeoutTime_DMPI" SG_ 2654486598 CBV_bit1 0;
BA_ "GenSigTimeoutTime_BPCM" SG_ 2654486598 CBV_bit1 0;
BA_ "GenSigTimeoutTime_AGSM" SG_ 2654486598 CBV_bit1 0;
BA_ "GenSigTimeoutTime_SGW" SG_ 2654486598 CBV_bit3_NMCoordinatorBit 0;
BA_ "GenSigTimeoutTime_PBWM" SG_ 2654486598 CBV_bit3_NMCoordinatorBit 0;
BA_ "GenSigTimeoutTime_IDCM" SG_ 2654486598 CBV_bit3_NMCoordinatorBit 0;
BA_ "GenSigTimeoutTime_EVCU2" SG_ 2654486598 CBV_bit3_NMCoordinatorBit 0;
BA_ "GenSigTimeoutTime_ECM" SG_ 2654486598 CBV_bit3_NMCoordinatorBit 0;
BA_ "GenSigTimeoutTime_DMPI" SG_ 2654486598 CBV_bit3_NMCoordinatorBit 0;
BA_ "GenSigTimeoutTime_BPCM" SG_ 2654486598 CBV_bit3_NMCoordinatorBit 0;
BA_ "GenSigTimeoutTime_AGSM" SG_ 2654486598 CBV_bit3_NMCoordinatorBit 0;
BA_ "GenSigTimeoutTime_SGW" SG_ 2654486598 CBV_bit2 0;
BA_ "GenSigTimeoutTime_PBWM" SG_ 2654486598 CBV_bit2 0;
BA_ "GenSigTimeoutTime_IDCM" SG_ 2654486598 CBV_bit2 0;
BA_ "GenSigTimeoutTime_EVCU2" SG_ 2654486598 CBV_bit2 0;
BA_ "GenSigTimeoutTime_ECM" SG_ 2654486598 CBV_bit2 0;
BA_ "GenSigTimeoutTime_DMPI" SG_ 2654486598 CBV_bit2 0;
BA_ "GenSigTimeoutTime_BPCM" SG_ 2654486598 CBV_bit2 0;
BA_ "GenSigTimeoutTime_AGSM" SG_ 2654486598 CBV_bit2 0;
BA_ "GenSigTimeoutTime_SGW" SG_ 2654486598 SourceNodeIdentifier 0;
BA_ "GenSigTimeoutTime_PBWM" SG_ 2654486598 SourceNodeIdentifier 0;
BA_ "GenSigTimeoutTime_IDCM" SG_ 2654486598 SourceNodeIdentifier 0;
BA_ "GenSigTimeoutTime_EVCU2" SG_ 2654486598 SourceNodeIdentifier 0;
BA_ "GenSigTimeoutTime_ECM" SG_ 2654486598 SourceNodeIdentifier 0;
BA_ "GenSigTimeoutTime_DMPI" SG_ 2654486598 SourceNodeIdentifier 0;
BA_ "GenSigTimeoutTime_BPCM" SG_ 2654486598 SourceNodeIdentifier 0;
BA_ "GenSigTimeoutTime_AGSM" SG_ 2654486598 SourceNodeIdentifier 0;
BA_ "GenSigTimeoutTime_SGW" SG_ 2654486598 CBV_bit7 0;
BA_ "GenSigTimeoutTime_PBWM" SG_ 2654486598 CBV_bit7 0;
BA_ "GenSigTimeoutTime_IDCM" SG_ 2654486598 CBV_bit7 0;
BA_ "GenSigTimeoutTime_EVCU2" SG_ 2654486598 CBV_bit7 0;
BA_ "GenSigTimeoutTime_ECM" SG_ 2654486598 CBV_bit7 0;
BA_ "GenSigTimeoutTime_DMPI" SG_ 2654486598 CBV_bit7 0;
BA_ "GenSigTimeoutTime_BPCM" SG_ 2654486598 CBV_bit7 0;
BA_ "GenSigTimeoutTime_AGSM" SG_ 2654486598 CBV_bit7 0;
BA_ "GenSigTimeoutTime_SGW" SG_ 2654486598 CBV_bit4_ActiveWakeupBit 0;
BA_ "GenSigTimeoutTime_PBWM" SG_ 2654486598 CBV_bit4_ActiveWakeupBit 0;
BA_ "GenSigTimeoutTime_IDCM" SG_ 2654486598 CBV_bit4_ActiveWakeupBit 0;
BA_ "GenSigTimeoutTime_EVCU2" SG_ 2654486598 CBV_bit4_ActiveWakeupBit 0;
BA_ "GenSigTimeoutTime_ECM" SG_ 2654486598 CBV_bit4_ActiveWakeupBit 0;
BA_ "GenSigTimeoutTime_DMPI" SG_ 2654486598 CBV_bit4_ActiveWakeupBit 0;
BA_ "GenSigTimeoutTime_BPCM" SG_ 2654486598 CBV_bit4_ActiveWakeupBit 0;
BA_ "GenSigTimeoutTime_AGSM" SG_ 2654486598 CBV_bit4_ActiveWakeupBit 0;
BA_ "GenSigTimeoutTime_SGW" SG_ 2654486598 CBV_bit5 0;
BA_ "GenSigTimeoutTime_PBWM" SG_ 2654486598 CBV_bit5 0;
BA_ "GenSigTimeoutTime_IDCM" SG_ 2654486598 CBV_bit5 0;
BA_ "GenSigTimeoutTime_EVCU2" SG_ 2654486598 CBV_bit5 0;
BA_ "GenSigTimeoutTime_ECM" SG_ 2654486598 CBV_bit5 0;
BA_ "GenSigTimeoutTime_DMPI" SG_ 2654486598 CBV_bit5 0;
BA_ "GenSigTimeoutTime_BPCM" SG_ 2654486598 CBV_bit5 0;
BA_ "GenSigTimeoutTime_AGSM" SG_ 2654486598 CBV_bit5 0;
BA_ "GenSigTimeoutTime_SGW" SG_ 2654486598 CBV_bit6_PartialNtwInfBit 0;
BA_ "GenSigTimeoutTime_PBWM" SG_ 2654486598 CBV_bit6_PartialNtwInfBit 0;
BA_ "GenSigTimeoutTime_IDCM" SG_ 2654486598 CBV_bit6_PartialNtwInfBit 0;
BA_ "GenSigTimeoutTime_EVCU2" SG_ 2654486598 CBV_bit6_PartialNtwInfBit 0;
BA_ "GenSigTimeoutTime_ECM" SG_ 2654486598 CBV_bit6_PartialNtwInfBit 0;
BA_ "GenSigTimeoutTime_DMPI" SG_ 2654486598 CBV_bit6_PartialNtwInfBit 0;
BA_ "GenSigTimeoutTime_BPCM" SG_ 2654486598 CBV_bit6_PartialNtwInfBit 0;
BA_ "GenSigTimeoutTime_AGSM" SG_ 2654486598 CBV_bit6_PartialNtwInfBit 0;
VAL_ 276 InputSpdRaw 4095 "SNA";
VAL_ 276 HybTransSt 0 "INIT" 1 "Neutral_Stable_State" 2 "EVT_Mode1_Stable_State" 3 "EVT_Mode2_Stable_State" 4 "Gear1_Stable_State" 5 "Gear2_Stable_State" 6 "Gear3_Stable_State" 7 "Gear4_Stable_State" 8 "G1_G2_SP" 9 "G1_G2_TP" 10 "G2_G1_SP" 11 "G2_G1_TP" 12 "G2_G3_SP" 13 "G2_G3_TP" 14 "G3_G2_SP" 15 "G3_G2_TP" 16 "G3_G4_SP" 17 "G3_G4_TP" 18 "G4_G3_SP" 19 "G4_G3_TP" 20 "EVT_M1_Gear1_SP" 21 "EVT_M1_Gear2_SP" 22 "EVT_M2_Gear2_SP" 23 "EVT_M2_Gear3_SP" 24 "EVT_M2_Gear4_SP" 25 "Neutral_EVT_M1_Shift" 26 "Neutral_EVT_M2_Shift" 27 "Shift_Neutral" 28 "EVT_M1_EVT_M2_QS" 29 "EVT_M2_EVT_M1_QS" 30 "EVT_M1_SP" 31 "EVT_M2_SP" 32 "G1_Abort_G1G2_TP" 33 "G2_Abort_G2G3_TP" 34 "G3_Abort_G3G4_TP" 35 "G2_Abort_G2G1_TP" 36 "G3_Abort_G3G2_TP" 37 "G4_Abort_G4G3_TP" 38 "Init_Neut" 39 "M3" 40 "NeutToM3" 41 "M1ToM2_PwrOnC2CSpdPhs" 42 "M1ToM2_PwrOnC2CTorqPhs" 43 "M2ToM1_PwrOffC2CSpdPhs" 44 "M2ToM1_PwrOffC2CTorqPhs" 45 "M1ToM3_PwrOnC2CSpdPhs" 46 "M1ToM3_PwrOnC2CTorqPhs" 47 "M3ToM1_PwrOffC2CSpdPhs" 48 "M3ToM1_PwrOffC2CTorqPhs" 49 "M3ToG4" 50 "G2ToG4_PwrOnC2CSpdPhs" 51 "G2ToG4_PwrOnC2CTorqPhs" 52 "G4ToG2_PwrOffC2CSpdPhs" 53 "G4ToG2_PwrOffC2CTorqPhs" 54 "M1Abort_FromM1ToM2_C2CSpdPhs" 55 "M1Abort_FromM1ToM2_C2CTorqPhs" 56 "M1Abort_FromM1ToM3_C2CSpdPhs" 57 "M1Abort_FromM1ToM3_C2CTorqPhs" 58 "M2Abort_FromM2ToM1_C2CSpdPhs" 59 "M2Abort_FromM2ToM1_C2CTorqPhs" 60 "M3Abort" 61 "M3Abort_FromM3ToM1_C2CSpdPhs" 62 "M3Abort_FromM3ToM1_C2CTorqPhs" 63 "INV" 64 "G2Abort_FromG2ToG4_C2CSpdPhs" 65 "G2Abort_FromG2ToG4_C2CTorqPhs" 66 "G4Abort_FromG4ToG2_C2CSpdPhs" 67 "G4Abort_FromG4ToG2_C2CTorqPhs";
VAL_ 276 HybEstEngTorq 4095 "SNA";
VAL_ 276 HybCmndEngTorqRespTyp 0 "Inactive" 1 "PL" 2 "MR" 3 "SNA";
VAL_ 276 HybCmndEngTorqPrdtd 4095 "SNA";
VAL_ 276 HybCmndEngTorqImmed 4095 "SNA";
VAL_ 276 EngTrqReserveCmd 255 "SNA";
VAL_ 271 Sum_FW_ID_Slw 31 "SNA";
VAL_ 271 Sum_FW_ID_Fst 31 "SNA";
VAL_ 271 MinPrdtdEngRunTorqCapV 0 "Valid" 1 "Not_Valid";
VAL_ 271 MinPrdtdEngRunTorqCap 4095 "SNA";
VAL_ 271 MinImmedEngTorqCapV 0 "Valid" 1 "Not_Valid";
VAL_ 271 MinImmedEngTorqCap 4095 "SNA";
VAL_ 271 MinEngTorqCapV 0 "Valid" 1 "Not_Valid";
VAL_ 271 MinEngTorqCap 4095 "SNA";
VAL_ 271 MinAirFlowMinSparkTorqCap 4095 "SNA";
VAL_ 271 MaxPrdtdEngTorqCapV 0 "Valid" 1 "Not_Valid";
VAL_ 271 MaxPrdtdEngTorqCap 4095 "SNA";
VAL_ 271 MaxOffEngTorqCap 4095 "SNA";
VAL_ 271 HybActEngTorqRespTyp 0 "Inactive" 1 "Pleasability_Limited" 2 "Maximum_Range";
VAL_ 271 ETRQ_Mode 7 "SNA";
VAL_ 271 EngTrqReserveReq 255 "SNA";
VAL_ 271 Engine_Sync_720 0 "NOT_SYNCED" 1 "SYNC_720_ACHIEVED";
VAL_ 271 EngAirFlwStdyStTorqV 0 "Valid" 1 "Not_Valid";
VAL_ 271 EngAirFlwStdyStTorq 4095 "SNA";
VAL_ 271 EngActuatorsStat 0 "ACPP" 1 "SCPP" 2 "ACPA";
VAL_ 271 EngActStdyStTorqV 0 "Valid" 1 "Not_Valid";
VAL_ 271 EngActStdyStTorq 4095 "SNA";
VAL_ 271 Crank_Maturing_Fault 0 "False" 1 "True";
VAL_ 271 Crank_Locked 0 "NOT_LOCKED" 1 "CRANK_LOCKED";
VAL_ 271 Cam_Int_1_Locked 0 "CAM_UNLOCKED" 1 "CAM_LOCKED";
VAL_ 271 Cam_Exh_1_Locked 0 "CAM_UNLOCKED" 1 "CAM_LOCKED";
VAL_ 271 AccPosV 0 "False" 1 "True";
VAL_ 258 VehicleSpeedVSOSig 8191 "SNA";
VAL_ 1579 HVBatteryVoltage_MinCal 511 "SNA";
VAL_ 1579 HVBatteryVoltage_MaxCal 511 "SNA";
VAL_ 1579 HVBatteryCurrent_MaxCal 255 "SNA";
VAL_ 1579 ChargeSystemFaultReason 0 "No_Failure" 1 "Failure1" 2 "Failure2" 3 "Failure3" 4 "Failure4" 5 "Failure5" 6 "Failure6" 7 "Failure7" 8 "Failure8" 9 "Failure9" 10 "Failure10" 11 "Failure11" 12 "Failure12" 13 "Failure13" 14 "Failure14" 15 "Failure15" 16 "Failure16" 17 "Failure17" 18 "Failure18" 19 "Failure19" 20 "Failure20" 21 "Failure21" 22 "Failure22" 23 "Failure23" 24 "Failure24" 25 "Failure25" 26 "Failure26" 27 "Failure27" 28 "Failure28" 29 "Failure29" 30 "Failure30" 31 "Failure31" 32 "Failure32" 33 "Failure33" 34 "Failure34" 35 "Failure35" 36 "Failure36" 37 "Failure37" 38 "Failure38" 39 "Failure39" 40 "Failure40" 41 "Failure41" 42 "Failure42" 43 "Failure43" 44 "Failure44" 45 "Failure45" 46 "Failure46" 47 "Failure47" 48 "Failure48" 49 "Failure49" 50 "Failure50" 51 "Failure51" 52 "Failure52" 53 "Failure53" 54 "Failure54" 55 "Failure55" 56 "Failure56" 57 "Failure57" 58 "Failure58" 59 "Failure59" 60 "Failure60" 61 "Failure61" 62 "Failure62" 63 "Failure63" 64 "Failure64" 65 "Failure65" 66 "Failure66" 67 "Failure67" 68 "Failure68" 69 "Failure69" 70 "Failure70" 71 "Failure71" 72 "Failure72" 73 "Failure73" 74 "Failure74" 75 "Failure75" 76 "Failure76" 77 "Failure77" 78 "Failure78" 79 "Failure79" 80 "Failure80" 81 "Failure81" 82 "Failure82" 83 "Failure83" 84 "Failure84" 85 "Failure85" 86 "Failure86" 87 "Failure87" 88 "Failure88" 89 "Failure89" 90 "Failure90" 91 "Failure91" 92 "Failure92" 93 "Failure93" 94 "Failure94" 95 "Failure95" 96 "Failure96" 97 "Failure97" 98 "Failure98" 99 "Failure99" 100 "Failure100" 101 "Failure101" 102 "Failure102" 103 "Failure103" 104 "Failure104" 105 "Failure105" 106 "Failure106" 107 "Failure107" 108 "Failure108" 109 "Failure109" 110 "Failure110" 111 "Failure111" 112 "Failure112" 113 "Failure113" 114 "Failure114" 115 "Failure115" 116 "Failure116" 117 "Failure117" 118 "Failure118" 119 "Failure119" 120 "Failure120" 121 "Failure121" 122 "Failure122" 123 "Failure123" 124 "Failure124" 125 "Failure125" 126 "Failure126" 127 "Failure127" 128 "Failure128" 129 "Failure129" 130 "Failure130" 131 "Failure131" 132 "Failure132" 133 "Failure133" 134 "Failure134" 135 "Failure135" 136 "Failure136" 137 "Failure137" 138 "Failure138" 139 "Failure139" 140 "Failure140" 141 "Failure141" 142 "Failure142" 143 "Failure143" 144 "Failure144" 145 "Failure145" 146 "Failure146" 147 "Failure147" 148 "Failure148" 149 "Failure149" 150 "Failure150" 151 "Failure151" 152 "Failure152" 153 "Failure153" 154 "Failure154" 155 "Failure155" 156 "Failure156" 157 "Failure157" 158 "Failure158" 159 "Failure159" 160 "Failure160" 161 "Failure161" 162 "Failure162" 163 "Failure163" 164 "Failure164" 165 "Failure165" 166 "Failure166" 167 "Failure167" 168 "Failure168" 169 "Failure169" 170 "Failure170" 171 "Failure171" 172 "Failure172" 173 "Failure173" 174 "Failure174" 175 "Failure175" 176 "Failure176" 177 "Failure177" 178 "Failure178" 179 "Failure179" 180 "Failure180" 181 "Failure181" 182 "Failure182" 183 "Failure183" 184 "Failure184" 185 "Failure185" 186 "Failure186" 187 "Failure187" 188 "Failure188" 189 "Failure189" 190 "Failure190" 191 "Failure191" 192 "Failure192" 193 "Failure193" 194 "Failure194" 195 "Failure195" 196 "Failure196" 197 "Failure197" 198 "Failure198" 199 "Failure199" 200 "Failure200" 201 "Failure201" 202 "Failure202" 203 "Failure203" 204 "Failure204" 205 "Failure205" 206 "Failure206" 207 "Failure207" 208 "Failure208" 209 "Failure209" 210 "Failure210" 211 "Failure211" 212 "Failure212" 213 "Failure213" 214 "Failure214" 215 "Failure215" 216 "Failure216" 217 "Failure217" 218 "Failure218" 219 "Failure219" 220 "Failure220" 221 "Failure221" 222 "Failure222" 223 "Failure223" 224 "Failure224" 225 "Failure225" 226 "Failure226" 227 "Failure227" 228 "Failure228" 229 "Failure229" 230 "Failure230" 231 "Failure231" 232 "Failure232" 233 "Failure233" 234 "Failure234" 235 "Failure235" 236 "Failure236" 237 "Failure237" 238 "Failure238" 239 "Failure239" 240 "Failure240" 241 "Failure241" 242 "Failure242" 243 "Failure243" 244 "Failure244" 245 "Failure245" 246 "Failure246" 247 "Failure247" 248 "Failure248" 249 "Failure249" 250 "Failure250" 251 "Failure251" 252 "Failure252" 253 "Failure253" 254 "Failure254" 255 "SNA";
VAL_ 1579 ACCurrent_MaxCal 511 "SNA";
VAL_ 1578 OBC_IdleTimeSec 65535 "SNA";
VAL_ 1578 OBC_IdleTimeMin 65535 "SNA";
VAL_ 1578 OBC_ChargeTimeSec 65535 "SNA";
VAL_ 1578 OBC_ChargeTimeMin 65535 "SNA";
VAL_ 1578 Charging_WHr 65535 "SNA";
VAL_ 1372 OBC_Temp4 255 "SNA";
VAL_ 1372 OBC_Temp3 255 "SNA";
VAL_ 1372 OBC_Temp2 255 "SNA";
VAL_ 1372 OBC_Temp1 255 "SNA";
VAL_ 276 PropulsionSystemActive 0 "Not_Active" 1 "Active";
VAL_ 1460 FOTA_Status 0 "No FOTA Event" 1 "Downloading Package from Backend" 2 "Passing Images to Big Target ECUs" 3 "Waiting for HMI Acceptance" 4 "Installing FOTA Updated" 5 "Successful FOTA Update" 6 "FOTA Failure Rollback Successful" 7 "FOTA Failure Complete" 8 "Build Vehicle Library" 9 "Check Campaign Availability" 10 "Check Download Conditions" 11 "Validate Vehicle Package" 12 "Double Check Manifest" 13 "Initiate Authenticated Diagnostic session" 14 "Ready_State" 15 "Rollback";
VAL_ 271 ECMReq_Remedial_Stop 0 "DEFAULT" 1 "Remedial_Stp_Req" 2 "Remedial_Stp_Req_w_Limp" 3 "SNA";
VAL_ 2654486598 CBV_bit6_PartialNtwInfBit 0 "NM PDU contains no Partial Network request information" 1 "NM PDU contains Partial Network request information";
VAL_ 2654486653 CBV_bit6_PartialNtwInfBit 0 "NM PDU contains no Partial Network request information" 1 "NM PDU contains Partial Network request information";
VAL_ 2654486653 CBV_bit4_ActiveWakeupBit 0 "PassiveWakeup" 1 "ActiveWakeup";
VAL_ 2654486598 CBV_bit4_ActiveWakeupBit 0 "PassiveWakeup" 1 "ActiveWakeup";
VAL_ 2654486653 CBV_bit3_NMCoordinatorBit 0 "Start of synchronized shutdown is not requested by main coordinator" 1 "Start of synchronized shutdown is requested by main coordinator";
VAL_ 2654486598 CBV_bit3_NMCoordinatorBit 0 "Start of synchronized shutdown is not requested by main coordinator" 1 "Start of synchronized shutdown is requested by main coordinator";
VAL_ 2654486598 CBV_bit0_RepeatMessageRequestBit 0 "Repeat Message State not requested" 1 "Repeat Message State requested";
VAL_ 2654486653 CBV_bit0_RepeatMessageRequestBit 0 "Repeat Message State not requested" 1 "Repeat Message State requested";
VAL_ 1579 ChargingLevel 0 "Default_NoLevel" 1 "Level_1_AC" 2 "Level_2_AC" 3 "Level_3_AC" 4 "Level_1_DC" 5 "Level_2_DC" 6 "PlugInNotDet" 7 "PPI_1_No_Drive" 8 "PPI_2_OK_Drive" 15 "SNA";
VAL_ 478 OBC_ControlMethod 0 "CURRENT" 1 "VOLTAGE" 2 "POWER" 3 "SNA";
VAL_ 478 J1772_CloseS2 0 "OPN" 1 "CLS";
VAL_ 478 HVPowertrain_InterlockSts 0 "N_S" 1 "PASS" 2 "FAIL" 3 "INV";
VAL_ 478 ClearLegislatedDiagInfo 0 "FALSE" 1 "TRUE";
VAL_ 1852 HVBatCellVoltage_Cell192 8191 "SNA";
VAL_ 1852 HVBatCellVoltage_Cell191 8191 "SNA";
VAL_ 1852 HVBatCellVoltage_Cell190 8191 "SNA";
VAL_ 1851 HVBatCellVoltage_Cell189 8191 "SNA";
VAL_ 1851 HVBatCellVoltage_Cell188 8191 "SNA";
VAL_ 1851 HVBatCellVoltage_Cell187 8191 "SNA";
VAL_ 1851 HVBatCellVoltage_Cell186 8191 "SNA";
VAL_ 1851 HVBatCellVoltage_Cell185 8191 "SNA";
VAL_ 1851 HVBatCellVoltage_Cell184 8191 "SNA";
VAL_ 1851 HVBatCellVoltage_Cell183 8191 "SNA";
VAL_ 1851 HVBatCellVoltage_Cell182 8191 "SNA";
VAL_ 1851 HVBatCellVoltage_Cell181 8191 "SNA";
VAL_ 1851 HVBatCellVoltage_Cell180 8191 "SNA";
VAL_ 1851 HVBatCellVoltage_Cell179 8191 "SNA";
VAL_ 1851 HVBatCellVoltage_Cell178 8191 "SNA";
VAL_ 1851 HVBatCellVoltage_Cell177 8191 "SNA";
VAL_ 1851 HVBatCellVoltage_Cell176 8191 "SNA";
VAL_ 1851 HVBatCellVoltage_Cell175 8191 "SNA";
VAL_ 1851 HVBatCellVoltage_Cell174 8191 "SNA";
VAL_ 1851 HVBatCellVoltage_Cell173 8191 "SNA";
VAL_ 1851 HVBatCellVoltage_Cell172 8191 "SNA";
VAL_ 1851 HVBatCellVoltage_Cell171 8191 "SNA";
VAL_ 1851 HVBatCellVoltage_Cell170 8191 "SNA";
VAL_ 1851 HVBatCellVoltage_Cell169 8191 "SNA";
VAL_ 1851 HVBatCellVoltage_Cell168 8191 "SNA";
VAL_ 1851 HVBatCellVoltage_Cell167 8191 "SNA";
VAL_ 1851 HVBatCellVoltage_Cell166 8191 "SNA";
VAL_ 1851 HVBatCellVoltage_Cell165 8191 "SNA";
VAL_ 1851 HVBatCellVoltage_Cell164 8191 "SNA";
VAL_ 1851 HVBatCellVoltage_Cell163 8191 "SNA";
VAL_ 1850 HVBatCellVoltage_Cell162 8191 "SNA";
VAL_ 1850 HVBatCellVoltage_Cell161 8191 "SNA";
VAL_ 1850 HVBatCellVoltage_Cell160 8191 "SNA";
VAL_ 1850 HVBatCellVoltage_Cell159 8191 "SNA";
VAL_ 1850 HVBatCellVoltage_Cell158 8191 "SNA";
VAL_ 1850 HVBatCellVoltage_Cell157 8191 "SNA";
VAL_ 1850 HVBatCellVoltage_Cell156 8191 "SNA";
VAL_ 1850 HVBatCellVoltage_Cell155 8191 "SNA";
VAL_ 1850 HVBatCellVoltage_Cell154 8191 "SNA";
VAL_ 1850 HVBatCellVoltage_Cell153 8191 "SNA";
VAL_ 1850 HVBatCellVoltage_Cell152 8191 "SNA";
VAL_ 1850 HVBatCellVoltage_Cell151 8191 "SNA";
VAL_ 1850 HVBatCellVoltage_Cell150 8191 "SNA";
VAL_ 1850 HVBatCellVoltage_Cell149 8191 "SNA";
VAL_ 1850 HVBatCellVoltage_Cell148 8191 "SNA";
VAL_ 1850 HVBatCellVoltage_Cell147 8191 "SNA";
VAL_ 1850 HVBatCellVoltage_Cell146 8191 "SNA";
VAL_ 1850 HVBatCellVoltage_Cell145 8191 "SNA";
VAL_ 1850 HVBatCellVoltage_Cell144 8191 "SNA";
VAL_ 1850 HVBatCellVoltage_Cell143 8191 "SNA";
VAL_ 1850 HVBatCellVoltage_Cell142 8191 "SNA";
VAL_ 1850 HVBatCellVoltage_Cell141 8191 "SNA";
VAL_ 1850 HVBatCellVoltage_Cell140 8191 "SNA";
VAL_ 1850 HVBatCellVoltage_Cell139 8191 "SNA";
VAL_ 1850 HVBatCellVoltage_Cell138 8191 "SNA";
VAL_ 1850 HVBatCellVoltage_Cell137 8191 "SNA";
VAL_ 1850 HVBatCellVoltage_Cell136 8191 "SNA";
VAL_ 1849 HVBatCellVoltage_Cell135 8191 "SNA";
VAL_ 1849 HVBatCellVoltage_Cell134 8191 "SNA";
VAL_ 1849 HVBatCellVoltage_Cell133 8191 "SNA";
VAL_ 1849 HVBatCellVoltage_Cell132 8191 "SNA";
VAL_ 1849 HVBatCellVoltage_Cell131 8191 "SNA";
VAL_ 1849 HVBatCellVoltage_Cell130 8191 "SNA";
VAL_ 1849 HVBatCellVoltage_Cell129 8191 "SNA";
VAL_ 1849 HVBatCellVoltage_Cell128 8191 "SNA";
VAL_ 1849 HVBatCellVoltage_Cell127 8191 "SNA";
VAL_ 1849 HVBatCellVoltage_Cell126 8191 "SNA";
VAL_ 1849 HVBatCellVoltage_Cell125 8191 "SNA";
VAL_ 1849 HVBatCellVoltage_Cell124 8191 "SNA";
VAL_ 1849 HVBatCellVoltage_Cell123 8191 "SNA";
VAL_ 1849 HVBatCellVoltage_Cell122 8191 "SNA";
VAL_ 1849 HVBatCellVoltage_Cell121 8191 "SNA";
VAL_ 1849 HVBatCellVoltage_Cell120 8191 "SNA";
VAL_ 1849 HVBatCellVoltage_Cell119 8191 "SNA";
VAL_ 1849 HVBatCellVoltage_Cell118 8191 "SNA";
VAL_ 1849 HVBatCellVoltage_Cell117 8191 "SNA";
VAL_ 1849 HVBatCellVoltage_Cell116 8191 "SNA";
VAL_ 1849 HVBatCellVoltage_Cell115 8191 "SNA";
VAL_ 1849 HVBatCellVoltage_Cell114 8191 "SNA";
VAL_ 1849 HVBatCellVoltage_Cell113 8191 "SNA";
VAL_ 1849 HVBatCellVoltage_Cell112 8191 "SNA";
VAL_ 1849 HVBatCellVoltage_Cell111 8191 "SNA";
VAL_ 1849 HVBatCellVoltage_Cell110 8191 "SNA";
VAL_ 1849 HVBatCellVoltage_Cell109 8191 "SNA";
VAL_ 1579 OBCM_PLUG_STS 0 "NOT_PLUG_IN" 1 "PLUG_IN";
VAL_ 478 OBC_OperativeModeReq 0 "IDLE" 1 "HEATER" 2 "CHARGE" 3 "Discharge" 4 "AC_GRD_Sync" 5 "AC_GRD_Synth" 6 "CHARGE_INTERRUPTED" 7 "NOT_CHARGING" 15 "SNA";
VAL_ 478 HV_Volt_Min_Thrsh 2047 "SNA";
VAL_ 478 HV_Volt_Max_Thrsh 2047 "SNA";
VAL_ 478 DC_Curr_Max_Thrsh 1023 "SNA";
VAL_ 478 ChargeEnable 0 "Charge_Not_Enabled" 1 "Charge_Enabled" 3 "SNA";
VAL_ 478 AC_Curr_Min_Thrsh 1023 "SNA";
VAL_ 478 AC_Curr_Max_Thrsh 1023 "SNA";
VAL_ 1578 OnboardChargerReady 0 "WU_FLT" 1 "OFF" 2 "ON" 3 "SNA";
VAL_ 1578 OnboardChargerMode 0 "IDLE" 1 "HEATER" 2 "CHARGE" 3 "Discharge" 4 "AC_GRD" 5 "UTC" 6 "STOP" 7 "FORCED_SHUTDOWN" 8 "CHARGE_INTERRUPTED" 9 "NOT_CHARGING";
VAL_ 1578 OBC_WakeReason 0 "NOT_DETECTED" 1 "Master_WU" 2 "EVSE_PlugIn" 3 "Pilot_PWM" 4 "Prox_in" 5 "EVSE_UnPlug" 6 "s3_open" 7 "BPCM_WU";
VAL_ 1578 OBC_GenericFailSts 0 "Fail_Not_Present" 1 "Fail_Present";
VAL_ 1578 OBC_FaultReason 0 "No_Fault" 1 "COMM_FAULT" 2 "EVSE_InputCirFault" 3 "Batt_12vFault" 4 "OBCM_LV_Fault" 5 "OBCM_HV_Fault" 6 "Extern_Dev_Fault" 7 "WakeupCircuitFault" 8 "Impact" 9 "DischargeFault" 127 "SNA";
VAL_ 1578 OBC_ChargingFaultSts 0 "No_Performed" 1 "No_Fault" 2 "OBCM_ECU_HW_Error" 3 "OBCM_Modules_Error" 4 "Gnd_Fault" 5 "Temperature_Error" 6 "OverCurrent_Error" 7 "OverVoltage_Error";
VAL_ 1578 ACplug_PwrMax 65535 "SNA";
VAL_ 1579 VDCM_UDCChrgr 65535 "SNA";
VAL_ 1579 VDCM_IDCChrgr 65535 "SNA";
VAL_ 1579 ChargeSystemSts 0 "NotCharging" 1 "Charging" 2 "ChargeInterrupted" 3 "ChargeComplete" 4 "ChargeError" 7 "SNA";
VAL_ 1579 ChargeSystemFault 0 "No_Fail" 1 "Fail";
VAL_ 478 VDCM_StsWldgReq 0 "No_WeldingCheck_Req" 1 "WeldingCheck_Req";
VAL_ 478 VDCM_SessnStopReq 0 "No_SessStop_Req" 1 "SessStop_Req";
VAL_ 271 ECM_Crank_Phase 0 "Not_Initialized" 1 "Quadrant_1" 2 "Quadrant_2" 3 "Quadrant_3" 4 "Quadrant_4" 7 "SNA";
VAL_ 271 MAP_4_BAR_PHEV 511 "SNA";
VAL_ 478 VDCM_StsSWWldgReq 0 "No_SWWeldingCheck_Req" 1 "SWWeldingCheck_Req";
VAL_ 1578 OBCM_PrechargeSts 0 "Not_Requested" 1 "Ongoing" 2 "Completed" 3 "Fail";
VAL_ 1578 ChrgFailSts 0 "No_Fault" 1 "Flt_charging_allowed" 2 "Flt_charging_inhibited" 3 "Flt_charging_terminated" 4 "Flt_AC_failure_DC_chg_allwd" 7 "SNA";
VAL_ 1852 HVBatCellVoltage_Cell216 8191 "SNA";
VAL_ 1852 HVBatCellVoltage_Cell215 8191 "SNA";
VAL_ 1852 HVBatCellVoltage_Cell214 8191 "SNA";
VAL_ 1852 HVBatCellVoltage_Cell213 8191 "SNA";
VAL_ 1852 HVBatCellVoltage_Cell212 8191 "SNA";
VAL_ 1852 HVBatCellVoltage_Cell211 8191 "SNA";
VAL_ 1852 HVBatCellVoltage_Cell210 8191 "SNA";
VAL_ 1852 HVBatCellVoltage_Cell209 8191 "SNA";
VAL_ 1852 HVBatCellVoltage_Cell208 8191 "SNA";
VAL_ 1852 HVBatCellVoltage_Cell207 8191 "SNA";
VAL_ 1852 HVBatCellVoltage_Cell206 8191 "SNA";
VAL_ 1852 HVBatCellVoltage_Cell205 8191 "SNA";
VAL_ 1852 HVBatCellVoltage_Cell204 8191 "SNA";
VAL_ 1852 HVBatCellVoltage_Cell203 8191 "SNA";
VAL_ 1852 HVBatCellVoltage_Cell202 8191 "SNA";
VAL_ 1852 HVBatCellVoltage_Cell201 8191 "SNA";
VAL_ 1852 HVBatCellVoltage_Cell200 8191 "SNA";
VAL_ 1852 HVBatCellVoltage_Cell198 8191 "SNA";
VAL_ 1852 HVBatCellVoltage_Cell197 8191 "SNA";
VAL_ 1852 HVBatCellVoltage_Cell196 8191 "SNA";
VAL_ 1852 HVBatCellVoltage_Cell195 8191 "SNA";
VAL_ 1852 HVBatCellVoltage_Cell194 8191 "SNA";
VAL_ 1852 HVBatCellVoltage_Cell193 8191 "SNA";
VAL_ 271 RedSpkAuthorityAvbl 0 "Not_Available" 1 "Available";
VAL_ 271 EngMinSparkNomCurrAirTorqCap 2047 "SNA";
VAL_ 271 PnLimitMaxEngTrqCapV 0 "Valid" 1 "Not_Valid";
VAL_ 271 PnLimitMaxEngTrqCap 1023 "SNA";
VAL_ 271 PnLimitActvFlg 0 "Not_Active" 1 "Active";
VAL_ 476 ShiftLeverPositionReq 0 "No_Selection_Active_Or_Available" 1 "P" 2 "R" 3 "N" 4 "D" 5 "L" 6 "TIP_Autostick" 7 "Plus" 8 "Minus" 9 "Sport" 10 "Not_Used" 11 "Not_Used" 12 "Not_Used" 13 "Not_Used" 14 "Not_Used" 15 "SNA";
SIG_GROUP_ 276 HYBRID_POWERTRAIN1_Pkt 1 : MessageCounter_HYBRID_POWERTRAI TransInpSpdPrfl InputSpdRaw HybTransSt Hybrid_Remedial_Stop HybFeedback_Engine HybEstEngTorqV HybEstEngTorq HybCrnkAbrted HybCmndEngTorqRespTyp HybCmndEngTorqPrdtd HybCmndEngTorqImmed EngTrqReserveCmd EngCntrlMode ECMPrepIdleRes CRC_HYBRID_POWERTRAIN1 PropulsionSystemActive HybFstTrqRq_Trans;
SIG_GROUP_ 271 ENGINE_HYBD_FD_1_Pkt 1 : EngSysFld TLC_LRN_Rq Sum_FW_ID_Slw Sum_FW_ID_Fst PT_CrnkAct MinPrdtdEngRunTorqCapV MinPrdtdEngRunTorqCap MinImmedEngTorqCapV MinImmedEngTorqCap MinEngTorqCapV MinEngTorqCap MinAirFlowMinSparkTorqCapV MinAirFlowMinSparkTorqCap MessageCounter_ENGINE_HYBD_FD_1 MaxPrdtdEngTorqCapV MaxPrdtdEngTorqCap MaxOffEngTorqCap HybActEngTorqRespTyp Feedback_HCP ETRQ_Mode EngTrqReserveReq EngRunCrnkAct EngOffRecom Engine_Sync_720 EngDFCO_St EngDFCO_Req EngDFCO_Allw EngCmbstnCmnd EngAirFlwStdyStTorqV EngAirFlwStdyStTorq EngActuatorsStat EngActStdyStTorqV EngActStdyStTorq CylOff CRC_ENGINE_HYBD_FD_1 Crank_Maturing_Fault Crank_Locked Cam_Int_1_Locked Cam_Exh_1_Locked AccPosV AccPos ECMReq_Remedial_Stop ECM_Crank_Phase MAP_4_BAR_PHEV RedSpkAuthorityAvbl EngMinSparkNomCurrAirTorqCap PnLimitMaxEngTrqCapV PnLimitMaxEngTrqCap PnLimitActvFlg;
SIG_GROUP_ 476 AGSM_FD_2_Pkt 1 : MessageCounter_AGSM2 CRC_AGSM2 ShiftLeverPositionReq;
